VERSION ""

NS_ :

BS_:

BU_: BMS ECC EVBUS_Virtual_ECU GW OBC VCU

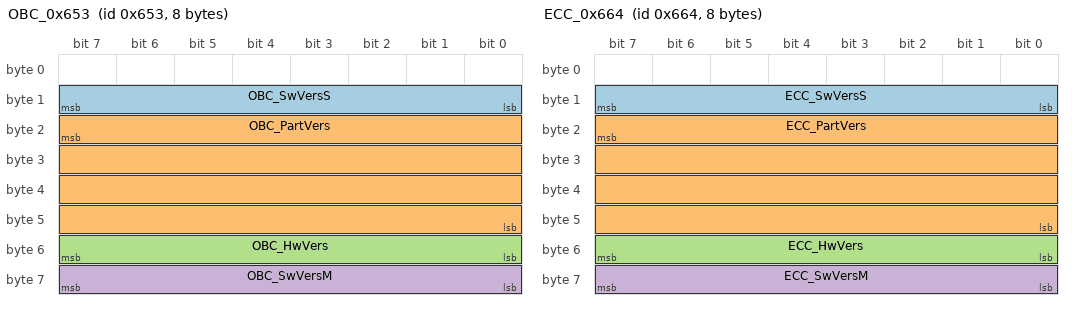
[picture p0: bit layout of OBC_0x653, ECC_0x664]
BO_ 1619 OBC_0x653: 8 OBC
 SG_ OBC_SwVersS : 15|8@0+ (1,0) [0|255] ""  GW,VCU
 SG_ OBC_PartVers : 23|32@0+ (1,0) [0|4294967295] ""  GW,VCU
 SG_ OBC_HwVers : 55|8@0+ (1,0) [0|255] ""  GW,VCU
 SG_ OBC_SwVersM : 63|8@0+ (1,0) [0|255] ""  GW,VCU

BO_ 1636 ECC_0x664: 8 ECC
 SG_ ECC_SwVersS : 15|8@0+ (1,0) [0|255] ""  GW
 SG_ ECC_PartVers : 23|32@0+ (1,0) [0|4294967295] ""  GW
 SG_ ECC_HwVers : 55|8@0+ (1,0) [0|255] ""  GW
 SG_ ECC_SwVersM : 63|8@0+ (1,0) [0|255] ""  GW

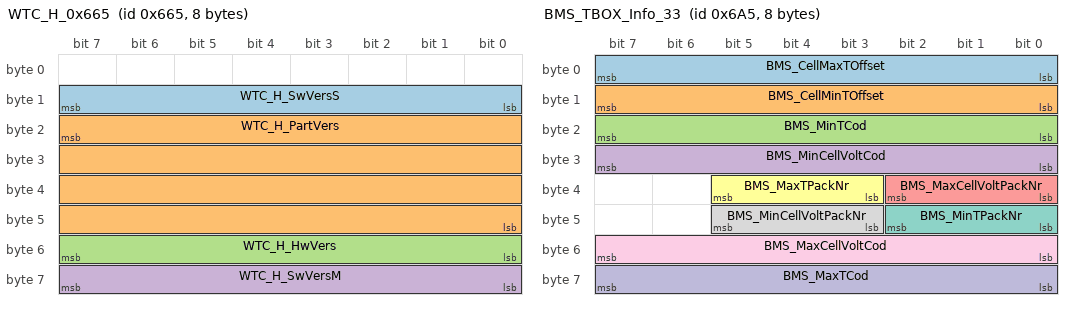
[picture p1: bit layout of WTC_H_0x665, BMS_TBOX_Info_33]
BO_ 1637 WTC_H_0x665: 8 ECC
 SG_ WTC_H_SwVersS : 15|8@0+ (1,0) [0|255] ""  GW
 SG_ WTC_H_PartVers : 23|32@0+ (1,0) [0|4294967295] ""  GW
 SG_ WTC_H_HwVers : 55|8@0+ (1,0) [0|255] ""  GW
 SG_ WTC_H_SwVersM : 63|8@0+ (1,0) [51|255] ""  GW

BO_ 1638 WTC_B_0x666: 8 ECC
 SG_ WTC_B_SwVersS : 15|8@0+ (1,0) [0|255] ""  GW
 SG_ WTC_B_PartVers : 23|32@0+ (1,0) [0|4294967295] ""  GW
 SG_ WTC_B_HwVers : 55|8@0+ (1,0) [0|255] ""  GW
 SG_ WTC_B_SwVersM : 63|8@0+ (1,0) [51|255] ""  GW

BO_ 1695 EAS_0x69F: 8 ECC
 SG_ EAS_SwVersS : 15|8@0+ (1,0) [0|255] ""  GW
 SG_ EAS_PartVers : 23|32@0+ (1,0) [0|4294967295] ""  GW
 SG_ EAS_HwVers : 55|8@0+ (1,0) [1|255] ""  GW
 SG_ EAS_SwVersM : 63|8@0+ (1,0) [51|255] ""  GW

BO_ 1696 BMS_PVIU_EnergyCounterActual: 8 BMS
 SG_ BMS_mxCounterActEnergy : 7|8@0+ (1,0) [0|255] ""  GW
 SG_ BMS_mxEnergyActValue1 : 15|24@0+ (1,0) [0|16777215] "Wh"  GW
 SG_ BMS_mxEnergyActValue2 : 39|24@0+ (1,0) [0|16777215] "Wh"  GW
 SG_ DCDC_ActTemp : 63|8@0+ (1,-40) [-40|210] "Degree Celsius"  GW

BO_ 1697 BMS_C_D_Ah: 8 BMS
 SG_ BMS_AccueChrgTotAh : 7|32@0+ (1,0) [0|4294967295] "Ah"  GW
 SG_ BMS_AccueDchaTotAh : 39|32@0+ (1,0) [0|4294967295] "Ah"  GW

BO_ 1698 VCU_0x6A2: 8 VCU
 SG_ VCU_SCChrgCnt : 7|16@0+ (1,0) [0|65535] ""  GW
 SG_ VCU_VehHVPwrOffTi : 23|24@0+ (1,0) [0|16777215] "min"  GW
 SG_ VCU_FCChrgCnt : 55|16@0+ (1,0) [0|65535] ""  GW

BO_ 1701 BMS_TBOX_Info_33: 8 BMS
 SG_ BMS_CellMaxTOffset : 7|8@0+ (1,-48) [-48|207] ""  GW
 SG_ BMS_CellMinTOffset : 15|8@0+ (1,-48) [-48|207] ""  GW
 SG_ BMS_MinTCod : 23|8@0+ (1,0) [0|255] ""  GW
 SG_ BMS_MinCellVoltCod : 31|8@0+ (1,0) [0|255] ""  GW
 SG_ BMS_MaxCellVoltPackNr : 34|3@0+ (1,0) [0|7] ""  GW
 SG_ BMS_MaxTPackNr : 37|3@0+ (1,0) [0|7] ""  GW
 SG_ BMS_MinTPackNr : 42|3@0+ (1,0) [0|7] ""  GW
 SG_ BMS_MinCellVoltPackNr : 45|3@0+ (1,0) [0|7] ""  GW
 SG_ BMS_MaxCellVoltCod : 55|8@0+ (1,0) [0|255] ""  GW
 SG_ BMS_MaxTCod : 63|8@0+ (1,0) [0|255] ""  GW

BO_ 1712 BMS_TBOX_Info_8: 8 BMS
 SG_ BMS_CellVolt1 : 7|16@0+ (0.1,0) [0|6553.4] "mV"  GW
 SG_ BMS_CellVolt2 : 23|16@0+ (0.1,0) [0|6553.4] "mV"  GW
 SG_ BMS_CellVolt3 : 39|16@0+ (0.1,0) [0|6553.4] "mV"  GW
 SG_ BMS_CellVolt4 : 55|16@0+ (0.1,0) [0|6553.4] "mV"  GW

BO_ 1713 BMS_TBOX_Info_9: 8 BMS
 SG_ BMS_CellVolt5 : 7|16@0+ (0.1,0) [0|6553.4] "mV"  GW
 SG_ BMS_CellVolt6 : 23|16@0+ (0.1,0) [0|6553.4] "mV"  GW
 SG_ BMS_CellVolt7 : 39|16@0+ (0.1,0) [0|6553.4] "mV"  GW
 SG_ BMS_CellVolt8 : 55|16@0+ (0.1,0) [0|6553.4] "mV"  GW

BO_ 1714 BMS_TBOX_Info_10: 8 BMS
 SG_ BMS_CellVolt9 : 7|16@0+ (0.1,0) [0|6553.4] "mV"  GW
 SG_ BMS_CellVolt10 : 23|16@0+ (0.1,0) [0|6553.4] "mV"  GW
 SG_ BMS_CellVolt11 : 39|16@0+ (0.1,0) [0|6553.4] "mV"  GW
 SG_ BMS_CellVolt12 : 55|16@0+ (0.1,0) [0|6553.4] "mV"  GW

BO_ 1715 BMS_TBOX_Info_11: 8 BMS
 SG_ BMS_CellVolt13 : 7|16@0+ (0.1,0) [0|6553.4] "mV"  GW
 SG_ BMS_CellVolt14 : 23|16@0+ (0.1,0) [0|6553.4] "mV"  GW
 SG_ BMS_CellVolt15 : 39|16@0+ (0.1,0) [0|6553.4] "mV"  GW
 SG_ BMS_CellVolt16 : 55|16@0+ (0.1,0) [0|6553.4] "mV"  GW

BO_ 1716 BMS_TBOX_Info_12: 8 BMS
 SG_ BMS_CellVolt17 : 7|16@0+ (0.1,0) [0|6553.4] "mV"  GW
 SG_ BMS_CellVolt18 : 23|16@0+ (0.1,0) [0|6553.4] "mV"  GW
 SG_ BMS_CellVolt19 : 39|16@0+ (0.1,0) [0|6553.4] "mV"  GW
 SG_ BMS_CellVolt20 : 55|16@0+ (0.1,0) [0|6553.4] "mV"  GW

BO_ 1717 BMS_TBOX_Info_13: 8 BMS
 SG_ BMS_CellVolt21 : 7|16@0+ (0.1,0) [0|6553.4] "mV"  GW
 SG_ BMS_CellVolt22 : 23|16@0+ (0.1,0) [0|6553.4] "mV"  GW
 SG_ BMS_CellVolt23 : 39|16@0+ (0.1,0) [0|6553.4] "mV"  GW
 SG_ BMS_CellVolt24 : 55|16@0+ (0.1,0) [0|6553.4] "mV"  GW

BO_ 1718 BMS_TBOX_Info_14: 8 BMS
 SG_ BMS_CellVolt25 : 7|16@0+ (0.1,0) [0|6553.4] "mV"  GW
 SG_ BMS_CellVolt26 : 23|16@0+ (0.1,0) [0|6553.4] "mV"  GW
 SG_ BMS_CellVolt27 : 39|16@0+ (0.1,0) [0|6553.4] "mV"  GW
 SG_ BMS_CellVolt28 : 55|16@0+ (0.1,0) [0|6553.4] "mV"  GW

BO_ 1719 BMS_TBOX_Info_15: 8 BMS
 SG_ BMS_CellVolt29 : 7|16@0+ (0.1,0) [0|6553.4] "mV"  GW
 SG_ BMS_CellVolt30 : 23|16@0+ (0.1,0) [0|6553.4] "mV"  GW
 SG_ BMS_CellVolt31 : 39|16@0+ (0.1,0) [0|6553.4] "mV"  GW
 SG_ BMS_CellVolt32 : 55|16@0+ (0.1,0) [0|6553.4] "mV"  GW

BO_ 1720 BMS_TBOX_Info_16: 8 BMS
 SG_ BMS_CellVolt33 : 7|16@0+ (0.1,0) [0|6553.4] "mV"  GW
 SG_ BMS_CellVolt34 : 23|16@0+ (0.1,0) [0|6553.4] "mV"  GW
 SG_ BMS_CellVolt35 : 39|16@0+ (0.1,0) [0|6553.4] "mV"  GW
 SG_ BMS_CellVolt36 : 55|16@0+ (0.1,0) [0|6553.4] "mV"  GW

BO_ 1721 BMS_TBOX_Info_17: 8 BMS
 SG_ BMS_CellVolt37 : 7|16@0+ (0.1,0) [0|6553.4] "mV"  GW
 SG_ BMS_CellVolt38 : 23|16@0+ (0.1,0) [0|6553.4] "mV"  GW
 SG_ BMS_CellVolt39 : 39|16@0+ (0.1,0) [0|6553.4] "mV"  GW
 SG_ BMS_CellVolt40 : 55|16@0+ (0.1,0) [0|6553.4] "mV"  GW

BO_ 1722 BMS_TBOX_Info_18: 8 BMS
 SG_ BMS_CellVolt41 : 7|16@0+ (0.1,0) [0|6553.4] "mV"  GW
 SG_ BMS_CellVolt42 : 23|16@0+ (0.1,0) [0|6553.4] "mV"  GW
 SG_ BMS_CellVolt43 : 39|16@0+ (0.1,0) [0|6553.4] "mV"  GW
 SG_ BMS_CellVolt44 : 55|16@0+ (0.1,0) [0|6553.4] "mV"  GW

BO_ 1723 BMS_TBOX_Info_19: 8 BMS
 SG_ BMS_CellVolt45 : 7|16@0+ (0.1,0) [0|6553.4] "mV"  GW
 SG_ BMS_CellVolt46 : 23|16@0+ (0.1,0) [0|6553.4] "mV"  GW
 SG_ BMS_CellVolt47 : 39|16@0+ (0.1,0) [0|6553.4] "mV"  GW
 SG_ BMS_CellVolt48 : 55|16@0+ (0.1,0) [0|6553.4] "mV"  GW

BO_ 1724 BMS_TBOX_Info_20: 8 BMS
 SG_ BMS_CellVolt49 : 7|16@0+ (0.1,0) [0|6553.4] "mV"  GW
 SG_ BMS_CellVolt50 : 23|16@0+ (0.1,0) [0|6553.4] "mV"  GW
 SG_ BMS_CellVolt51 : 39|16@0+ (0.1,0) [0|6553.4] "mV"  GW
 SG_ BMS_CellVolt52 : 55|16@0+ (0.1,0) [0|6553.4] "mV"  GW

BO_ 1725 BMS_TBOX_Info_21: 8 BMS
 SG_ BMS_CellVolt53 : 7|16@0+ (0.1,0) [0|6553.4] "mV"  GW
 SG_ BMS_CellVolt54 : 23|16@0+ (0.1,0) [0|6553.4] "mV"  GW
 SG_ BMS_CellVolt55 : 39|16@0+ (0.1,0) [0|6553.4] "mV"  GW
 SG_ BMS_CellVolt56 : 55|16@0+ (0.1,0) [0|6553.4] "mV"  GW

BO_ 1726 BMS_TBOX_Info_34: 8 BMS
 SG_ BMS_CellVolt57 : 7|16@0+ (0.1,0) [0|6553.4] "mV"  GW
 SG_ BMS_CellVolt58 : 23|16@0+ (0.1,0) [0|6553.4] "mV"  GW
 SG_ BMS_CellVolt59 : 39|16@0+ (0.1,0) [0|6553.4] "mV"  GW
 SG_ BMS_CellVolt60 : 55|16@0+ (0.1,0) [0|6553.4] "mV"  GW

BO_ 1727 BMS_TBOX_Info_35: 8 BMS
 SG_ BMS_CellVolt61 : 7|16@0+ (0.1,0) [0|6553.4] "mV"  GW
 SG_ BMS_CellVolt62 : 23|16@0+ (0.1,0) [0|6553.4] "mV"  GW
 SG_ BMS_CellVolt63 : 39|16@0+ (0.1,0) [0|6553.4] "mV"  GW
 SG_ BMS_CellVolt64 : 55|16@0+ (0.1,0) [0|6553.4] "mV"  GW

BO_ 1728 BMS_TBOX_Info_36: 8 BMS
 SG_ BMS_CellVolt65 : 7|16@0+ (0.1,0) [0|6553.4] "mV"  GW
 SG_ BMS_CellVolt66 : 23|16@0+ (0.1,0) [0|6553.4] "mV"  GW
 SG_ BMS_CellVolt67 : 39|16@0+ (0.1,0) [0|6553.4] "mV"  GW
 SG_ BMS_CellVolt68 : 55|16@0+ (0.1,0) [0|6553.4] "mV"  GW

BO_ 1729 BMS_TBOX_Info_37: 8 BMS
 SG_ BMS_CellVolt69 : 7|16@0+ (0.1,0) [0|6553.4] "mV"  GW
 SG_ BMS_CellVolt70 : 23|16@0+ (0.1,0) [0|6553.4] "mV"  GW
 SG_ BMS_CellVolt71 : 39|16@0+ (0.1,0) [0|6553.4] "mV"  GW
 SG_ BMS_CellVolt72 : 55|16@0+ (0.1,0) [0|6553.4] "mV"  GW

BO_ 1730 BMS_TBOX_Info_38: 8 BMS
 SG_ BMS_CellVolt73 : 7|16@0+ (0.1,0) [0|6553.4] "mV"  GW
 SG_ BMS_CellVolt74 : 23|16@0+ (0.1,0) [0|6553.4] "mV"  GW
 SG_ BMS_CellVolt75 : 39|16@0+ (0.1,0) [0|6553.4] "mV"  GW
 SG_ BMS_CellVolt76 : 55|16@0+ (0.1,0) [0|6553.4] "mV"  GW

BO_ 1731 BMS_TBOX_Info_39: 8 BMS
 SG_ BMS_CellVolt77 : 7|16@0+ (0.1,0) [0|6553.4] "mV"  GW
 SG_ BMS_CellVolt78 : 23|16@0+ (0.1,0) [0|6553.4] "mV"  GW
 SG_ BMS_CellVolt79 : 39|16@0+ (0.1,0) [0|6553.4] "mV"  GW
 SG_ BMS_CellVolt80 : 55|16@0+ (0.1,0) [0|6553.4] "mV"  GW

BO_ 1732 BMS_TBOX_Info_40: 8 BMS
 SG_ BMS_CellVolt81 : 7|16@0+ (0.1,0) [0|6553.4] "mV"  GW
 SG_ BMS_CellVolt82 : 23|16@0+ (0.1,0) [0|6553.4] "mV"  GW
 SG_ BMS_CellVolt83 : 39|16@0+ (0.1,0) [0|6553.4] "mV"  GW
 SG_ BMS_CellVolt84 : 55|16@0+ (0.1,0) [0|6553.4] "mV"  GW

BO_ 1733 BMS_TBOX_Info_41: 8 BMS
 SG_ BMS_CellVolt85 : 7|16@0+ (0.1,0) [0|6553.4] "mV"  GW
 SG_ BMS_CellVolt86 : 23|16@0+ (0.1,0) [0|6553.4] "mV"  GW
 SG_ BMS_CellVolt87 : 39|16@0+ (0.1,0) [0|6553.4] "mV"  GW
 SG_ BMS_CellVolt88 : 55|16@0+ (0.1,0) [0|6553.4] "mV"  GW

BO_ 1734 BMS_TBOX_Info_42: 8 BMS
 SG_ BMS_CellVolt89 : 7|16@0+ (0.1,0) [0|6553.4] "mV"  GW
 SG_ BMS_CellVolt90 : 23|16@0+ (0.1,0) [0|6553.4] "mV"  GW
 SG_ BMS_CellVolt91 : 39|16@0+ (0.1,0) [0|6553.4] "mV"  GW
 SG_ BMS_CellVolt92 : 55|16@0+ (0.1,0) [0|6553.4] "mV"  GW

BO_ 1735 BMS_TBOX_Info_43: 8 BMS
 SG_ BMS_CellVolt93 : 7|16@0+ (0.1,0) [0|6553.4] "mV"  GW
 SG_ BMS_CellVolt94 : 23|16@0+ (0.1,0) [0|6553.4] "mV"  GW
 SG_ BMS_CellVolt95 : 39|16@0+ (0.1,0) [0|6553.4] "mV"  GW
 SG_ BMS_CellVolt96 : 55|16@0+ (0.1,0) [0|6553.4] "mV"  GW

BO_ 1736 BMS_TBOX_Info_44: 8 BMS
 SG_ BMS_CellVolt97 : 7|16@0+ (0.1,0) [0|6553.4] "mV"  GW
 SG_ BMS_CellVolt98 : 23|16@0+ (0.1,0) [0|6553.4] "mV"  GW
 SG_ BMS_CellVolt99 : 39|16@0+ (0.1,0) [0|6553.4] "mV"  GW
 SG_ BMS_CellVolt100 : 55|16@0+ (0.1,0) [0|6553.4] "mV"  GW

BO_ 1737 BMS_TBOX_Info_45: 8 BMS
 SG_ BMS_CellVolt101 : 7|16@0+ (0.1,0) [0|6553.4] "mV"  GW
 SG_ BMS_CellVolt102 : 23|16@0+ (0.1,0) [0|6553.4] "mV"  GW
 SG_ BMS_CellVolt103 : 39|16@0+ (0.1,0) [0|6553.4] "mV"  GW
 SG_ BMS_CellVolt104 : 55|16@0+ (0.1,0) [0|6553.4] "mV"  GW

BO_ 1738 BMS_TBOX_Info_46: 8 BMS
 SG_ BMS_CellVolt105 : 7|16@0+ (0.1,0) [0|6553.4] "mV"  GW
 SG_ BMS_CellVolt106 : 23|16@0+ (0.1,0) [0|6553.4] "mV"  GW
 SG_ BMS_CellVolt107 : 39|16@0+ (0.1,0) [0|6553.4] "mV"  GW
 SG_ BMS_CellVolt108 : 55|16@0+ (0.1,0) [0|6553.4] "mV"  GW

BO_ 1739 BMS_TBOX_Info_47: 8 BMS
 SG_ BMS_CellVolt109 : 7|16@0+ (0.1,0) [0|6553.4] "mV"  GW
 SG_ BMS_CellVolt110 : 23|16@0+ (0.1,0) [0|6553.4] "mV"  GW
 SG_ BMS_CellVolt111 : 39|16@0+ (0.1,0) [0|6553.4] "mV"  GW
 SG_ BMS_CellVolt112 : 55|16@0+ (0.1,0) [0|6553.4] "mV"  GW

BO_ 1740 BMS_TBOX_Info_48: 8 BMS
 SG_ BMS_CellVolt113 : 7|16@0+ (0.1,0) [0|6553.4] "mV"  GW
 SG_ BMS_CellVolt114 : 23|16@0+ (0.1,0) [0|6553.4] "mV"  GW
 SG_ BMS_CellVolt115 : 39|16@0+ (0.1,0) [0|6553.4] "mV"  GW
 SG_ BMS_CellVolt116 : 55|16@0+ (0.1,0) [0|6553.4] "mV"  GW

BO_ 1741 BMS_TBOX_Info_49: 8 BMS
 SG_ BMS_CellVolt117 : 7|16@0+ (0.1,0) [0|6553.4] "mV"  GW
 SG_ BMS_CellVolt118 : 23|16@0+ (0.1,0) [0|6553.4] "mV"  GW
 SG_ BMS_CellVolt119 : 39|16@0+ (0.1,0) [0|6553.4] "mV"  GW
 SG_ BMS_CellVolt120 : 55|16@0+ (0.1,0) [0|6553.4] "mV"  GW

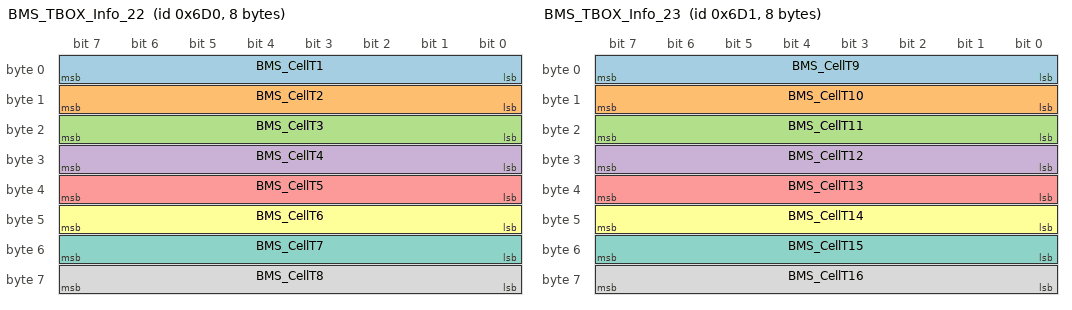
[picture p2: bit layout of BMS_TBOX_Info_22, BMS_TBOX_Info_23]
BO_ 1744 BMS_TBOX_Info_22: 8 BMS
 SG_ BMS_CellT1 : 7|8@0+ (1,-48) [-48|207] "Degree Celsius"  GW
 SG_ BMS_CellT2 : 15|8@0+ (1,-48) [-48|207] "Degree Celsius"  GW
 SG_ BMS_CellT3 : 23|8@0+ (1,-48) [-48|207] "Degree Celsius"  GW
 SG_ BMS_CellT4 : 31|8@0+ (1,-48) [-48|207] "Degree Celsius"  GW
 SG_ BMS_CellT5 : 39|8@0+ (1,-48) [-48|207] "Degree Celsius"  GW
 SG_ BMS_CellT6 : 47|8@0+ (1,-48) [-48|207] "Degree Celsius"  GW
 SG_ BMS_CellT7 : 55|8@0+ (1,-48) [-48|207] "Degree Celsius"  GW
 SG_ BMS_CellT8 : 63|8@0+ (1,-48) [-48|207] "Degree Celsius"  GW

BO_ 1745 BMS_TBOX_Info_23: 8 BMS
 SG_ BMS_CellT9 : 7|8@0+ (1,-48) [-48|207] "Degree Celsius"  GW
 SG_ BMS_CellT10 : 15|8@0+ (1,-48) [-48|207] "Degree Celsius"  GW
 SG_ BMS_CellT11 : 23|8@0+ (1,-48) [-48|207] "Degree Celsius"  GW
 SG_ BMS_CellT12 : 31|8@0+ (1,-48) [-48|207] "Degree Celsius"  GW
 SG_ BMS_CellT13 : 39|8@0+ (1,-48) [-48|207] "Degree Celsius"  GW
 SG_ BMS_CellT14 : 47|8@0+ (1,-48) [-48|207] "Degree Celsius"  GW
 SG_ BMS_CellT15 : 55|8@0+ (1,-48) [-48|207] "Degree Celsius"  GW
 SG_ BMS_CellT16 : 63|8@0+ (1,-48) [-48|207] "Degree Celsius"  GW

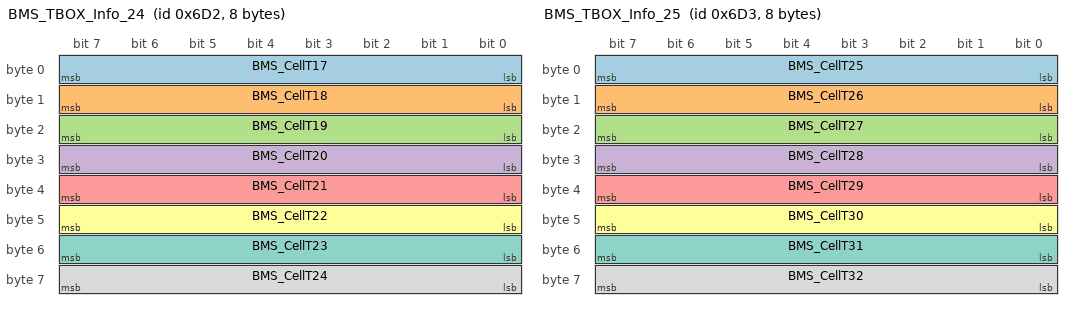
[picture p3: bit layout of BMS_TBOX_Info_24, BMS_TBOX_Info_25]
BO_ 1746 BMS_TBOX_Info_24: 8 BMS
 SG_ BMS_CellT17 : 7|8@0+ (1,-48) [-48|207] "Degree Celsius"  GW
 SG_ BMS_CellT18 : 15|8@0+ (1,-48) [-48|207] "Degree Celsius"  GW
 SG_ BMS_CellT19 : 23|8@0+ (1,-48) [-48|207] "Degree Celsius"  GW
 SG_ BMS_CellT20 : 31|8@0+ (1,-48) [-48|207] "Degree Celsius"  GW
 SG_ BMS_CellT21 : 39|8@0+ (1,-48) [-48|207] "Degree Celsius"  GW
 SG_ BMS_CellT22 : 47|8@0+ (1,-48) [-48|207] "Degree Celsius"  GW
 SG_ BMS_CellT23 : 55|8@0+ (1,-48) [-48|207] "Degree Celsius"  GW
 SG_ BMS_CellT24 : 63|8@0+ (1,-48) [-48|207] "Degree Celsius"  GW

BO_ 1747 BMS_TBOX_Info_25: 8 BMS
 SG_ BMS_CellT25 : 7|8@0+ (1,-48) [-48|207] "Degree Celsius"  GW
 SG_ BMS_CellT26 : 15|8@0+ (1,-48) [-48|207] "Degree Celsius"  GW
 SG_ BMS_CellT27 : 23|8@0+ (1,-48) [-48|207] "Degree Celsius"  GW
 SG_ BMS_CellT28 : 31|8@0+ (1,-48) [-48|207] "Degree Celsius"  GW
 SG_ BMS_CellT29 : 39|8@0+ (1,-48) [-48|207] "Degree Celsius"  GW
 SG_ BMS_CellT30 : 47|8@0+ (1,-48) [-48|207] "Degree Celsius"  GW
 SG_ BMS_CellT31 : 55|8@0+ (1,-48) [-48|207] "Degree Celsius"  GW
 SG_ BMS_CellT32 : 63|8@0+ (1,-48) [-48|207] "Degree Celsius"  GW

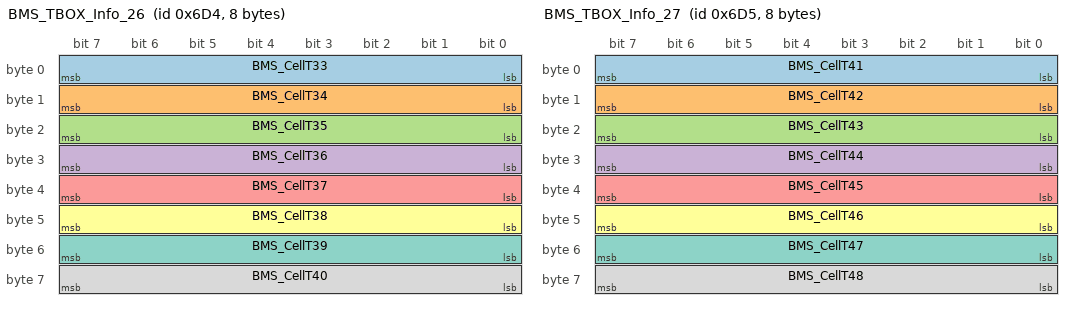
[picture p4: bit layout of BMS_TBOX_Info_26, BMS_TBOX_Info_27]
BO_ 1748 BMS_TBOX_Info_26: 8 BMS
 SG_ BMS_CellT33 : 7|8@0+ (1,-48) [-48|207] "Degree Celsius"  GW
 SG_ BMS_CellT34 : 15|8@0+ (1,-48) [-48|207] "Degree Celsius"  GW
 SG_ BMS_CellT35 : 23|8@0+ (1,-48) [-48|207] "Degree Celsius"  GW
 SG_ BMS_CellT36 : 31|8@0+ (1,-48) [-48|207] "Degree Celsius"  GW
 SG_ BMS_CellT37 : 39|8@0+ (1,-48) [-48|207] "Degree Celsius"  GW
 SG_ BMS_CellT38 : 47|8@0+ (1,-48) [-48|207] "Degree Celsius"  GW
 SG_ BMS_CellT39 : 55|8@0+ (1,-48) [-48|207] "Degree Celsius"  GW
 SG_ BMS_CellT40 : 63|8@0+ (1,-48) [-48|207] "Degree Celsius"  GW

BO_ 1749 BMS_TBOX_Info_27: 8 BMS
 SG_ BMS_CellT41 : 7|8@0+ (1,-48) [-48|207] "Degree Celsius"  GW
 SG_ BMS_CellT42 : 15|8@0+ (1,-48) [-48|207] "Degree Celsius"  GW
 SG_ BMS_CellT43 : 23|8@0+ (1,-48) [-48|207] "Degree Celsius"  GW
 SG_ BMS_CellT44 : 31|8@0+ (1,-48) [-48|207] "Degree Celsius"  GW
 SG_ BMS_CellT45 : 39|8@0+ (1,-48) [-48|207] "Degree Celsius"  GW
 SG_ BMS_CellT46 : 47|8@0+ (1,-48) [-48|207] "Degree Celsius"  GW
 SG_ BMS_CellT47 : 55|8@0+ (1,-48) [-48|207] "Degree Celsius"  GW
 SG_ BMS_CellT48 : 63|8@0+ (1,-48) [-48|207] "Degree Celsius"  GW

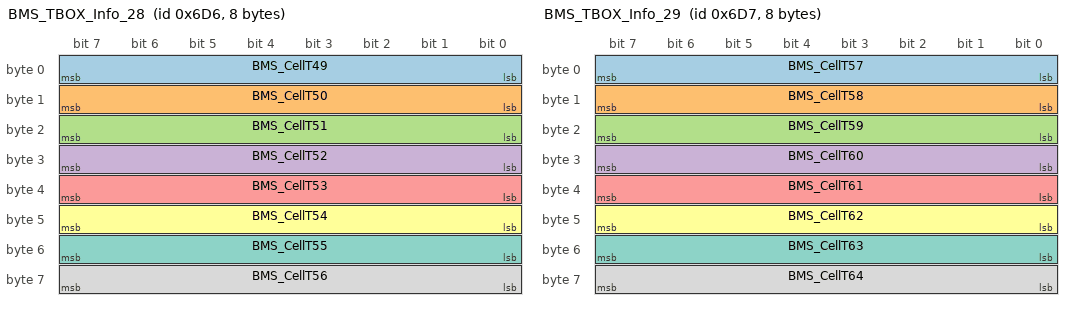
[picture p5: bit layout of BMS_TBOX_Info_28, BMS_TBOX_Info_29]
BO_ 1750 BMS_TBOX_Info_28: 8 BMS
 SG_ BMS_CellT49 : 7|8@0+ (1,-48) [-48|207] "Degree Celsius"  GW
 SG_ BMS_CellT50 : 15|8@0+ (1,-48) [-48|207] "Degree Celsius"  GW
 SG_ BMS_CellT51 : 23|8@0+ (1,-48) [-48|207] "Degree Celsius"  GW
 SG_ BMS_CellT52 : 31|8@0+ (1,-48) [-48|207] "Degree Celsius"  GW
 SG_ BMS_CellT53 : 39|8@0+ (1,-48) [-48|207] "Degree Celsius"  GW
 SG_ BMS_CellT54 : 47|8@0+ (1,-48) [-48|207] "Degree Celsius"  GW
 SG_ BMS_CellT55 : 55|8@0+ (1,-48) [-48|207] "Degree Celsius"  GW
 SG_ BMS_CellT56 : 63|8@0+ (1,-48) [-48|207] "Degree Celsius"  GW

BO_ 1751 BMS_TBOX_Info_29: 8 BMS
 SG_ BMS_CellT57 : 7|8@0+ (1,-48) [-48|207] "Degree Celsius"  GW
 SG_ BMS_CellT58 : 15|8@0+ (1,-48) [-48|207] "Degree Celsius"  GW
 SG_ BMS_CellT59 : 23|8@0+ (1,-48) [-48|207] "Degree Celsius"  GW
 SG_ BMS_CellT60 : 31|8@0+ (1,-48) [-48|207] "Degree Celsius"  GW
 SG_ BMS_CellT61 : 39|8@0+ (1,-48) [-48|207] "Degree Celsius"  GW
 SG_ BMS_CellT62 : 47|8@0+ (1,-48) [-48|207] "Degree Celsius"  GW
 SG_ BMS_CellT63 : 55|8@0+ (1,-48) [-48|207] "Degree Celsius"  GW
 SG_ BMS_CellT64 : 63|8@0+ (1,-48) [-48|207] "Degree Celsius"  GW

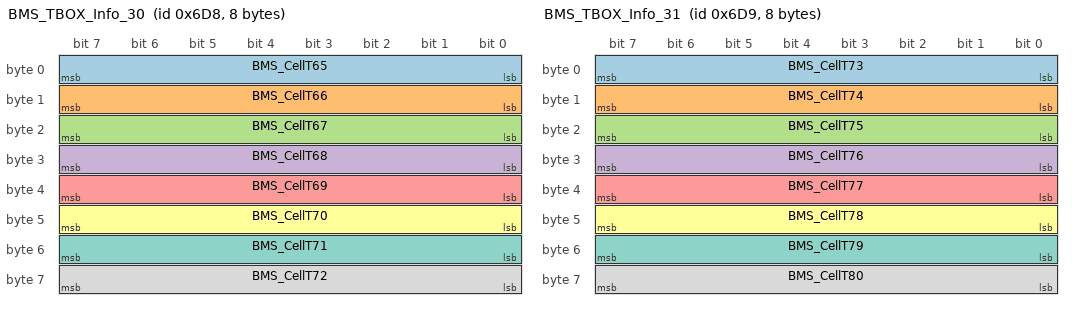
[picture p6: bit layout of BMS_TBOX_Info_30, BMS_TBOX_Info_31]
BO_ 1752 BMS_TBOX_Info_30: 8 BMS
 SG_ BMS_CellT65 : 7|8@0+ (1,-48) [-48|207] "Degree Celsius"  GW
 SG_ BMS_CellT66 : 15|8@0+ (1,-48) [-48|207] "Degree Celsius"  GW
 SG_ BMS_CellT67 : 23|8@0+ (1,-48) [-48|207] "Degree Celsius"  GW
 SG_ BMS_CellT68 : 31|8@0+ (1,-48) [-48|207] "Degree Celsius"  GW
 SG_ BMS_CellT69 : 39|8@0+ (1,-48) [-48|207] "Degree Celsius"  GW
 SG_ BMS_CellT70 : 47|8@0+ (1,-48) [-48|207] "Degree Celsius"  GW
 SG_ BMS_CellT71 : 55|8@0+ (1,-48) [-48|207] "Degree Celsius"  GW
 SG_ BMS_CellT72 : 63|8@0+ (1,-48) [-48|207] "Degree Celsius"  GW

BO_ 1753 BMS_TBOX_Info_31: 8 BMS
 SG_ BMS_CellT73 : 7|8@0+ (1,-48) [-48|207] "Degree Celsius"  GW
 SG_ BMS_CellT74 : 15|8@0+ (1,-48) [-48|207] "Degree Celsius"  GW
 SG_ BMS_CellT75 : 23|8@0+ (1,-48) [-48|207] "Degree Celsius"  GW
 SG_ BMS_CellT76 : 31|8@0+ (1,-48) [-48|207] "Degree Celsius"  GW
 SG_ BMS_CellT77 : 39|8@0+ (1,-48) [-48|207] "Degree Celsius"  GW
 SG_ BMS_CellT78 : 47|8@0+ (1,-48) [-48|207] "Degree Celsius"  GW
 SG_ BMS_CellT79 : 55|8@0+ (1,-48) [-48|207] "Degree Celsius"  GW
 SG_ BMS_CellT80 : 63|8@0+ (1,-48) [-48|207] "Degree Celsius"  GW

BO_ 1754 VCU_0x6DA: 16 VCU
 SG_ VCU_PwrGridAllwMaxPwrSplyCrt : 7|8@0+ (1,0) [0|255] "A"  GW,OBC
 SG_ VCU_ChrgLineAllwtCrt : 15|8@0+ (1,0) [0|255] "A"  GW,OBC
 SG_ VCU_DchaLineAllwCrt : 23|8@0+ (1,0) [0|255] "A"  GW,OBC
 SG_ VCU_DchaVehSts : 26|3@0+ (1,0) [0|7] ""  GW
 SG_ VCU_DCChrgSoktT1 : 39|8@0+ (1,-48) [-48|207] "Degree Celsius"  GW
 SG_ VCU_DCChrgSoktT2 : 47|8@0+ (1,-48) [-48|207] "Degree Celsius"  GW
 SG_ VCU_ACChrgDchaSoktT1 : 55|8@0+ (1,-48) [-48|207] "Degree Celsius"  GW
 SG_ VCU_6DA_SSecOC_Fresh_Byte0 : 71|8@0+ (1,0) [0|255] ""  GW,OBC
 SG_ VCU_6DA_SSecOC_MAC_Byte0 : 79|8@0+ (1,0) [0|255] ""  GW,OBC
 SG_ VCU_6DA_SSecOC_MAC_Byte1 : 87|8@0+ (1,0) [0|255] ""  GW,OBC
 SG_ VCU_6DA_SSecOC_MAC_Byte2 : 95|8@0+ (1,0) [0|255] ""  GW,OBC

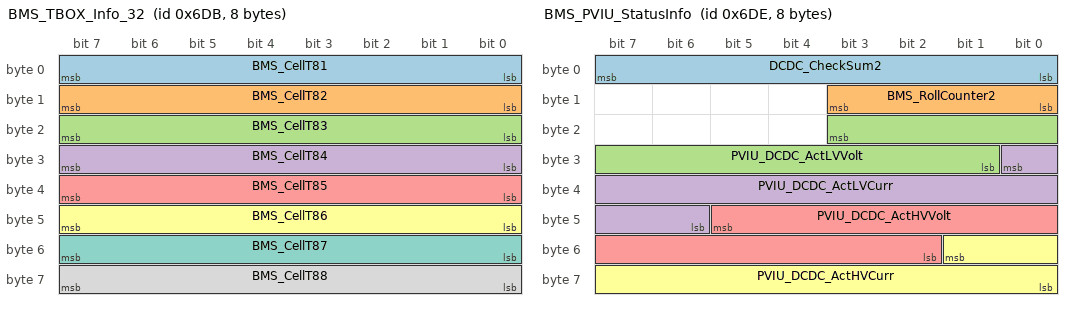
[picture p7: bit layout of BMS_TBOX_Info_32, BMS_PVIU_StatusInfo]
BO_ 1755 BMS_TBOX_Info_32: 8 BMS
 SG_ BMS_CellT81 : 7|8@0+ (1,-48) [-48|207] "Degree Celsius"  GW
 SG_ BMS_CellT82 : 15|8@0+ (1,-48) [-48|207] "Degree Celsius"  GW
 SG_ BMS_CellT83 : 23|8@0+ (1,-48) [-48|207] "Degree Celsius"  GW
 SG_ BMS_CellT84 : 31|8@0+ (1,-48) [-48|207] "Degree Celsius"  GW
 SG_ BMS_CellT85 : 39|8@0+ (1,-48) [-48|207] "Degree Celsius"  GW
 SG_ BMS_CellT86 : 47|8@0+ (1,-48) [-48|207] "Degree Celsius"  GW
 SG_ BMS_CellT87 : 55|8@0+ (1,-48) [-48|207] "Degree Celsius"  GW
 SG_ BMS_CellT88 : 63|8@0+ (1,-48) [-48|207] "Degree Celsius"  GW

BO_ 1756 BMS_PVIU_EnergyCounterHistory: 8 BMS
 SG_ BMS_mxCounterEnergy : 7|8@0+ (1,0) [0|255] ""  GW
 SG_ BMS_mxEnergyValue1 : 15|24@0+ (1,0) [0|16777215] "Wh"  GW
 SG_ BMS_mxEnergyValue2 : 39|24@0+ (1,0) [0|16777215] "Wh"  GW

BO_ 1757 BMS_PVIU_ActualPower: 8 BMS
 SG_ BMS_PVIU_actPower : 7|10@0+ (1,0) [0|1023] "W"  GW
 SG_ BMS_PVIU_EnergyOverall : 23|24@0+ (1,0) [0|16777215] "kWh"  GW
 SG_ BMS_PVIU_ActEngyYear : 47|24@0+ (1,0) [0|16777215] "Wh"  GW

BO_ 1758 BMS_PVIU_StatusInfo: 8 BMS
 SG_ DCDC_CheckSum2 : 7|8@0+ (1,0) [0|255] ""  GW
 SG_ BMS_RollCounter2 : 11|4@0+ (1,0) [0|15] ""  GW
 SG_ PVIU_DCDC_ActLVVolt : 19|11@0+ (0.05,0) [0|102.3] "V"  GW
 SG_ PVIU_DCDC_ActLVCurr : 24|11@0+ (0.01,0) [0|20.47] "A"  GW
 SG_ PVIU_DCDC_ActHVVolt : 45|12@0+ (0.25,0) [0|1023.75] "V"  GW
 SG_ PVIU_DCDC_ActHVCurr : 49|10@0+ (0.01,0) [0|10.23] "A"  GW

BO_ 1759 BMS_PVIU_ErrorStatus: 8 BMS
 SG_ BMS_0x6DF_CheckSum : 7|8@0+ (1,0) [0|255] ""  GW
 SG_ BMS_0x6DF_RollCounter : 11|4@0+ (1,0) [0|15] ""  GW
 SG_ BMS_PVIU_ModeReqSt : 13|2@0+ (1,0) [0|3] ""  GW
 SG_ BMS_PVIU_ModeSt : 15|2@0+ (1,0) [0|3] ""  GW
 SG_ BMS_PVIU_AvailInputPower : 23|11@0+ (1,0) [0|2047] "W"  GW
 SG_ BMS_PVIU_ActOutputPower : 28|11@0+ (1,0) [0|2047] "W"  GW
 SG_ BMS_PVIU_ActOutputEnergy : 33|13@0+ (1,0) [0|8191] "Wh"  GW
 SG_ BMS_PVIU_FailSt : 49|2@0+ (1,0) [0|3] ""  GW,VCU
 SG_ BMS_PVIU_F_Input_OVP : 50|1@0+ (1,0) [0|1] ""  GW
 SG_ BMS_PVIU_F_Input_UVP : 51|1@0+ (1,0) [0|1] ""  GW
 SG_ BMS_PVIU_F_Output_OVP : 52|1@0+ (1,0) [0|1] ""  GW
 SG_ BMS_PVIU_F_Output_UVP : 56|1@0+ (1,0) [0|1] ""  GW
 SG_ BMS_PVIU_F_12V_OVP : 57|1@0+ (1,0) [0|1] ""  GW
 SG_ BMS_PVIU_F_12V_UVP : 58|1@0+ (1,0) [0|1] ""  GW
 SG_ BMS_PVIU_F_Output_SCP : 59|1@0+ (1,0) [0|1] ""  GW
 SG_ BMS_PVIU_F_OTP : 60|1@0+ (1,0) [0|1] ""  GW
 SG_ BMS_PVIU_F_HVIL : 61|1@0+ (1,0) [0|1] ""  GW
 SG_ BMS_PVIU_F_CANRx_Timeout : 62|1@0+ (1,0) [0|1] ""  GW
 SG_ BMS_PVIU_F_Output_OCP : 63|1@0+ (1,0) [0|1] ""  GW

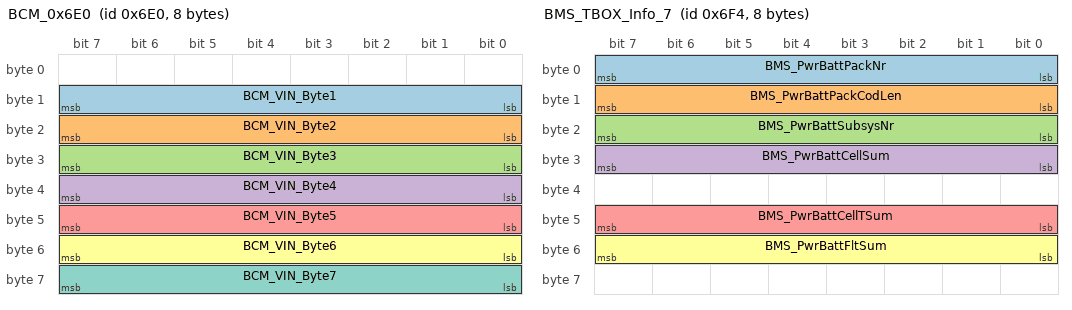
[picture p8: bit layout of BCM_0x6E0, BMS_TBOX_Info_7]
BO_ 1760 BCM_0x6E0: 8 GW
 SG_ BCM_VIN_Byte1 : 15|8@0+ (1,0) [0|255] ""  ECC,OBC,VCU
 SG_ BCM_VIN_Byte2 : 23|8@0+ (1,0) [0|255] ""  ECC,OBC,VCU
 SG_ BCM_VIN_Byte3 : 31|8@0+ (1,0) [0|255] ""  ECC,OBC,VCU
 SG_ BCM_VIN_Byte4 : 39|8@0+ (1,0) [0|255] ""  ECC,OBC,VCU
 SG_ BCM_VIN_Byte5 : 47|8@0+ (1,0) [0|255] ""  ECC,OBC,VCU
 SG_ BCM_VIN_Byte6 : 55|8@0+ (1,0) [0|255] ""  ECC,OBC,VCU
 SG_ BCM_VIN_Byte7 : 63|8@0+ (1,0) [0|255] ""  ECC,OBC,VCU

BO_ 1765 VCU_0x6E5: 8 VCU
 SG_ VCU_VINCod1 : 7|64@0+ (1,0) [0|16777215] ""  GW

BO_ 1766 VCU_0x6E6: 8 VCU
 SG_ VCU_VINCod2 : 7|64@0+ (1,0) [0|16777215] ""  GW

BO_ 1767 VCU_0x6E7: 8 VCU
 SG_ VCU_VINCod3 : 7|64@0+ (1,0) [0|16777215] ""  GW

BO_ 1776 BMS_TBOX_Info_3: 8 BMS
 SG_ BMS_PwrBattPackCod1 : 7|64@0+ (1,0) [0|16777215] ""  GW

BO_ 1777 BMS_TBOX_Info_4: 8 BMS
 SG_ BMS_PwrBattPackCod2 : 7|64@0+ (1,0) [0|16777215] ""  GW

BO_ 1778 BMS_TBOX_Info_5: 8 BMS
 SG_ BMS_PwrBattPackCod3 : 7|64@0+ (1,0) [0|16777215] ""  GW

BO_ 1779 BMS_TBOX_Info_6: 8 BMS
 SG_ BMS_PwrBattPackCod4 : 7|64@0+ (1,0) [0|16777215] ""  GW

BO_ 1780 BMS_TBOX_Info_7: 8 BMS
 SG_ BMS_PwrBattPackNr : 7|8@0+ (1,0) [0|255] ""  GW
 SG_ BMS_PwrBattPackCodLen : 15|8@0+ (1,0) [0|255] ""  GW
 SG_ BMS_PwrBattSubsysNr : 23|8@0+ (1,0) [0|255] ""  GW
 SG_ BMS_PwrBattCellSum : 31|8@0+ (1,0) [0|255] ""  GW
 SG_ BMS_PwrBattCellTSum : 47|8@0+ (1,0) [0|255] ""  GW
 SG_ BMS_PwrBattFltSum : 55|8@0+ (1,0) [0|255] ""  GW

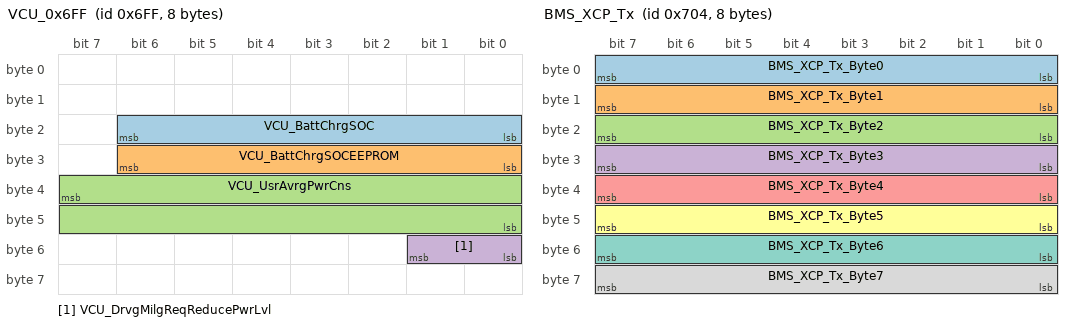
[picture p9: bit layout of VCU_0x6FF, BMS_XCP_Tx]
BO_ 1791 VCU_0x6FF: 8 VCU
 SG_ VCU_BattChrgSOC : 22|7@0+ (1,0) [0|100] "%"  GW
 SG_ VCU_BattChrgSOCEEPROM : 30|7@0+ (1,0) [0|100] "%"  GW
 SG_ VCU_UsrAvrgPwrCns : 39|16@0+ (0.0001,0) [0|6.5535] "Ah/km"  GW
 SG_ VCU_DrvgMilgReqReducePwrLvl : 49|2@0+ (1,0) [0|3] ""  GW

BO_ 1796 BMS_XCP_Tx: 8 BMS
 SG_ BMS_XCP_Tx_Byte0 : 7|8@0+ (1,0) [0|255] ""  EVBUS_Virtual_ECU
 SG_ BMS_XCP_Tx_Byte1 : 15|8@0+ (1,0) [0|255] ""  EVBUS_Virtual_ECU
 SG_ BMS_XCP_Tx_Byte2 : 23|8@0+ (1,0) [0|255] ""  EVBUS_Virtual_ECU
 SG_ BMS_XCP_Tx_Byte3 : 31|8@0+ (1,0) [0|255] ""  EVBUS_Virtual_ECU
 SG_ BMS_XCP_Tx_Byte4 : 39|8@0+ (1,0) [0|255] ""  EVBUS_Virtual_ECU
 SG_ BMS_XCP_Tx_Byte5 : 47|8@0+ (1,0) [0|255] ""  EVBUS_Virtual_ECU
 SG_ BMS_XCP_Tx_Byte6 : 55|8@0+ (1,0) [0|255] ""  EVBUS_Virtual_ECU
 SG_ BMS_XCP_Tx_Byte7 : 63|8@0+ (1,0) [0|255] ""  EVBUS_Virtual_ECU

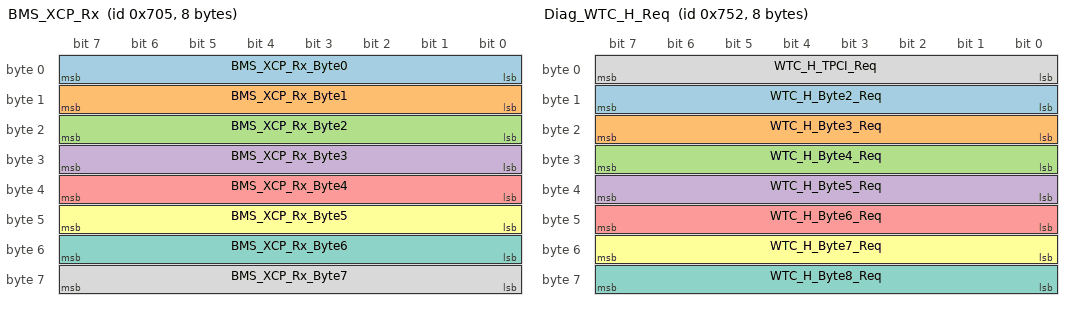
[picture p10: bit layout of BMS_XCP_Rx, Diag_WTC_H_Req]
BO_ 1797 BMS_XCP_Rx: 8 EVBUS_Virtual_ECU
 SG_ BMS_XCP_Rx_Byte0 : 7|8@0+ (1,0) [0|255] ""  BMS
 SG_ BMS_XCP_Rx_Byte1 : 15|8@0+ (1,0) [0|255] ""  BMS
 SG_ BMS_XCP_Rx_Byte2 : 23|8@0+ (1,0) [0|255] ""  BMS
 SG_ BMS_XCP_Rx_Byte3 : 31|8@0+ (1,0) [0|255] ""  BMS
 SG_ BMS_XCP_Rx_Byte4 : 39|8@0+ (1,0) [0|255] ""  BMS
 SG_ BMS_XCP_Rx_Byte5 : 47|8@0+ (1,0) [0|255] ""  BMS
 SG_ BMS_XCP_Rx_Byte6 : 55|8@0+ (1,0) [0|255] ""  BMS
 SG_ BMS_XCP_Rx_Byte7 : 63|8@0+ (1,0) [0|255] ""  BMS

BO_ 1798 VCU_XCP_Rx: 8 EVBUS_Virtual_ECU
 SG_ VCU_XCP_Rx_Signal : 7|64@0+ (1,0) [0|1.84467440737096E+019] ""  VCU

BO_ 1799 VCU_XCP_Tx: 8 VCU
 SG_ VCU_XCP_Tx_Signal : 7|64@0+ (1,0) [0|1.84467440737096E+019] ""  EVBUS_Virtual_ECU

BO_ 1800 ECC_XCP_Tx: 8 ECC
 SG_ ECC_XCP_Tx_Signal : 7|64@0+ (1,0) [0|1.84467440737096E+019] ""  EVBUS_Virtual_ECU

BO_ 1801 ECC_XCP_Rx1: 8 EVBUS_Virtual_ECU
 SG_ ECC_XCP_Rx_Signal_1 : 7|64@0+ (1,0) [0|1.84467440737096E+019] ""  ECC

BO_ 1802 ECC_XCP_Rx2: 8 EVBUS_Virtual_ECU
 SG_ ECC_XCP_Rx_Signal_2 : 7|64@0+ (1,0) [0|1.84467440737096E+019] ""  ECC

BO_ 1803 ECC_XCP_Rx3: 8 EVBUS_Virtual_ECU
 SG_ ECC_XCP_Rx_Signal_3 : 7|64@0+ (1,0) [0|1.84467440737096E+019] ""  ECC

BO_ 1804 ECC_XCP_Rx4: 8 EVBUS_Virtual_ECU
 SG_ ECC_XCP_Rx_Signal_4 : 7|64@0+ (1,0) [0|1.84467440737096E+019] ""  ECC

BO_ 1805 ECC_XCP_Rx5: 8 EVBUS_Virtual_ECU
 SG_ ECC_XCP_Rx_Signal_5 : 7|64@0+ (1,0) [0|1.84467440737096E+019] ""  ECC

BO_ 1806 ECC_XCP_Rx6: 8 EVBUS_Virtual_ECU
 SG_ ECC_XCP_Rx_Signal_6 : 7|64@0+ (1,0) [0|1.84467440737096E+019] ""  ECC

BO_ 1807 ECC_XCP_Rx7: 8 EVBUS_Virtual_ECU
 SG_ ECC_XCP_Rx_Signal_7 : 7|64@0+ (1,0) [0|1.84467440737096E+019] ""  ECC

BO_ 1808 ECC_XCP_Rx8: 8 EVBUS_Virtual_ECU
 SG_ ECC_XCP_Rx_Signal_8 : 7|64@0+ (1,0) [0|1.84467440737096E+019] ""  ECC

BO_ 1809 ECC_XCP_Rx9: 8 EVBUS_Virtual_ECU
 SG_ ECC_XCP_Rx_Signal_9 : 7|64@0+ (1,0) [0|1.84467440737096E+019] ""  ECC

BO_ 1812 OBC_TBOX_Debug: 16 OBC
 SG_ OBC_FailCode : 7|8@0+ (1,0) [0|250] ""  GW
 SG_ DCDC_FailCode : 15|8@0+ (1,0) [0|250] ""  GW
 SG_ DCDC_TempMOS : 23|8@0+ (1,-45) [-45|120] "Degree Celsius"  GW
 SG_ OBC_LLCTemp : 31|8@0+ (1,-45) [-45|120] "Degree Celsius"  GW
 SG_ DCDC_ULV1_1 : 39|8@0+ (1,0) [0|32] "V"  GW
 SG_ OBC_PFCTemp : 47|8@0+ (1,-45) [-45|120] "Degree Celsius"  GW
 SG_ DCDC_ClampCapVol : 55|10@0+ (1,0) [0|1000] "V"  GW
 SG_ OBC_CtrlActMode : 58|3@0+ (1,0) [0|7] ""  GW
 SG_ DCDC_CtrlMode : 61|3@0+ (1,0) [0|7] ""  GW
 SG_ PDU_DCPortVoltage : 71|10@0+ (1,0) [0|1000] "V"  GW
 SG_ PDU_BATVoltage : 72|10@0+ (1,0) [0|1000] "V"  GW
 SG_ Hw_Fault_Flag : 75|3@0+ (1,0) [0|7] ""  GW
 SG_ OBC_ElockCtrlCmd : 77|2@0+ (1,0) [0|3] ""  GW

BO_ 1874 Diag_WTC_H_Req: 8 GW
 SG_ WTC_H_Byte2_Req : 15|8@0+ (1,0) [0|255] ""  ECC
 SG_ WTC_H_Byte3_Req : 23|8@0+ (1,0) [0|255] ""  ECC
 SG_ WTC_H_Byte4_Req : 31|8@0+ (1,0) [0|255] ""  ECC
 SG_ WTC_H_Byte5_Req : 39|8@0+ (1,0) [0|255] ""  ECC
 SG_ WTC_H_Byte6_Req : 47|8@0+ (1,0) [0|255] ""  ECC
 SG_ WTC_H_Byte7_Req : 55|8@0+ (1,0) [0|255] ""  ECC
 SG_ WTC_H_Byte8_Req : 63|8@0+ (1,0) [0|255] ""  ECC
 SG_ WTC_H_TPCI_Req : 7|8@0+ (1,0) [0|255] ""  ECC

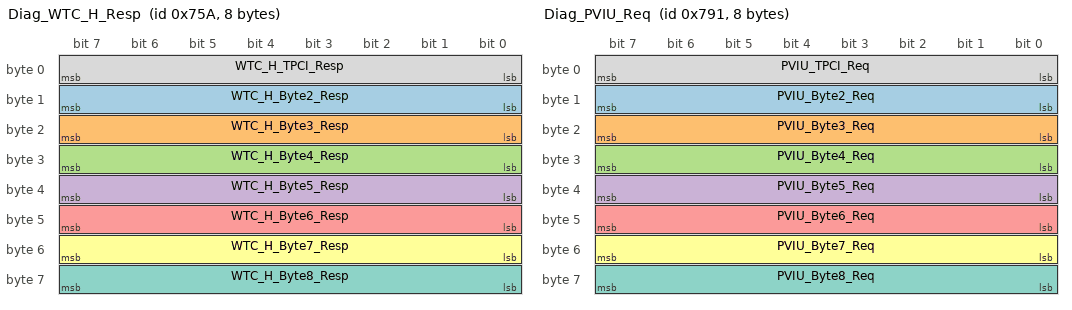
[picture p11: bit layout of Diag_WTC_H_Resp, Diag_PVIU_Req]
BO_ 1882 Diag_WTC_H_Resp: 8 ECC
 SG_ WTC_H_Byte2_Resp : 15|8@0+ (1,0) [0|255] ""  GW
 SG_ WTC_H_Byte3_Resp : 23|8@0+ (1,0) [0|255] ""  GW
 SG_ WTC_H_Byte4_Resp : 31|8@0+ (1,0) [0|255] ""  GW
 SG_ WTC_H_Byte5_Resp : 39|8@0+ (1,0) [0|255] ""  GW
 SG_ WTC_H_Byte6_Resp : 47|8@0+ (1,0) [0|255] ""  GW
 SG_ WTC_H_Byte7_Resp : 55|8@0+ (1,0) [0|255] ""  GW
 SG_ WTC_H_Byte8_Resp : 63|8@0+ (1,0) [0|255] ""  GW
 SG_ WTC_H_TPCI_Resp : 7|8@0+ (1,0) [0|255] ""  GW

BO_ 1937 Diag_PVIU_Req: 8 GW
 SG_ PVIU_Byte2_Req : 15|8@0+ (1,0) [0|255] ""  BMS
 SG_ PVIU_Byte3_Req : 23|8@0+ (1,0) [0|255] ""  BMS
 SG_ PVIU_Byte4_Req : 31|8@0+ (1,0) [0|255] ""  BMS
 SG_ PVIU_Byte5_Req : 39|8@0+ (1,0) [0|255] ""  BMS
 SG_ PVIU_Byte6_Req : 47|8@0+ (1,0) [0|255] ""  BMS
 SG_ PVIU_Byte7_Req : 55|8@0+ (1,0) [0|255] ""  BMS
 SG_ PVIU_Byte8_Req : 63|8@0+ (1,0) [0|255] ""  BMS
 SG_ PVIU_TPCI_Req : 7|8@0+ (1,0) [0|255] ""  BMS

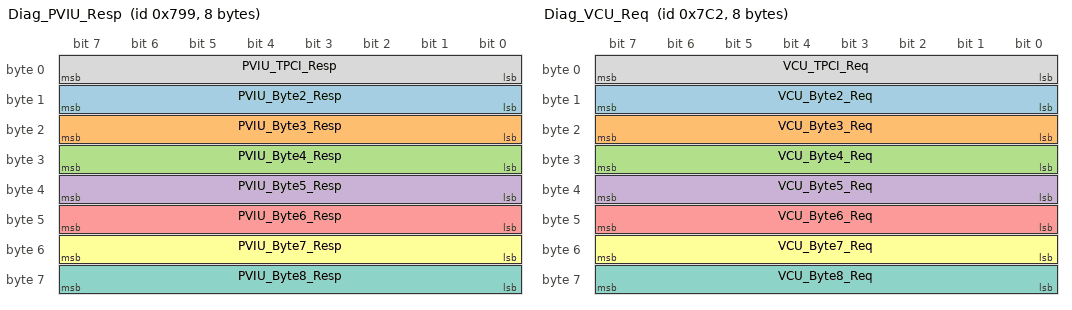
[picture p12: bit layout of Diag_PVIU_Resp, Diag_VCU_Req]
BO_ 1945 Diag_PVIU_Resp: 8 BMS
 SG_ PVIU_Byte2_Resp : 15|8@0+ (1,0) [0|255] ""  GW
 SG_ PVIU_Byte3_Resp : 23|8@0+ (1,0) [0|255] ""  GW
 SG_ PVIU_Byte4_Resp : 31|8@0+ (1,0) [0|255] ""  GW
 SG_ PVIU_Byte5_Resp : 39|8@0+ (1,0) [0|255] ""  GW
 SG_ PVIU_Byte6_Resp : 47|8@0+ (1,0) [0|255] ""  GW
 SG_ PVIU_Byte7_Resp : 55|8@0+ (1,0) [0|255] ""  GW
 SG_ PVIU_Byte8_Resp : 63|8@0+ (1,0) [0|255] ""  GW
 SG_ PVIU_TPCI_Resp : 7|8@0+ (1,0) [0|255] ""  GW

BO_ 1986 Diag_VCU_Req: 8 GW
 SG_ VCU_Byte2_Req : 15|8@0+ (1,0) [0|255] ""  VCU
 SG_ VCU_Byte3_Req : 23|8@0+ (1,0) [0|255] ""  VCU
 SG_ VCU_Byte4_Req : 31|8@0+ (1,0) [0|255] ""  VCU
 SG_ VCU_Byte5_Req : 39|8@0+ (1,0) [0|255] ""  VCU
 SG_ VCU_Byte6_Req : 47|8@0+ (1,0) [0|255] ""  VCU
 SG_ VCU_Byte7_Req : 55|8@0+ (1,0) [0|255] ""  VCU
 SG_ VCU_Byte8_Req : 63|8@0+ (1,0) [0|255] ""  VCU
 SG_ VCU_TPCI_Req : 7|8@0+ (1,0) [0|255] ""  VCU

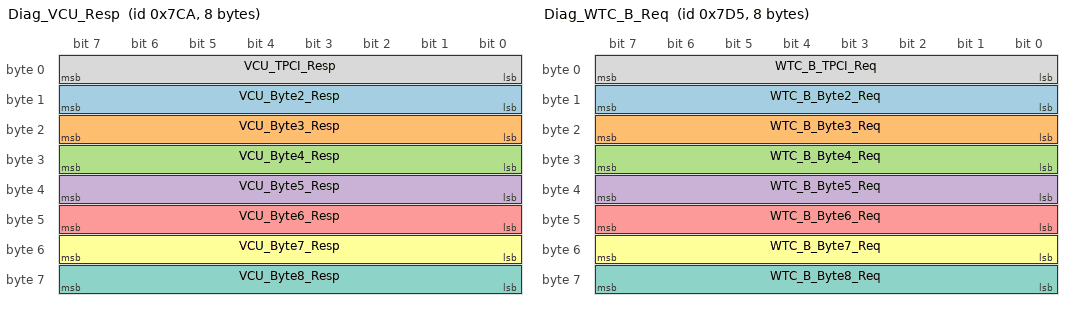
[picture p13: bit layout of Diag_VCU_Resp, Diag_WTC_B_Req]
BO_ 1994 Diag_VCU_Resp: 8 VCU
 SG_ VCU_Byte2_Resp : 15|8@0+ (1,0) [0|255] ""  GW
 SG_ VCU_Byte3_Resp : 23|8@0+ (1,0) [0|255] ""  GW
 SG_ VCU_Byte4_Resp : 31|8@0+ (1,0) [0|255] ""  GW
 SG_ VCU_Byte5_Resp : 39|8@0+ (1,0) [0|255] ""  GW
 SG_ VCU_Byte6_Resp : 47|8@0+ (1,0) [0|255] ""  GW
 SG_ VCU_Byte7_Resp : 55|8@0+ (1,0) [0|255] ""  GW
 SG_ VCU_Byte8_Resp : 63|8@0+ (1,0) [0|255] ""  GW
 SG_ VCU_TPCI_Resp : 7|8@0+ (1,0) [0|255] ""  GW

BO_ 2005 Diag_WTC_B_Req: 8 GW
 SG_ WTC_B_Byte2_Req : 15|8@0+ (1,0) [0|255] ""  ECC
 SG_ WTC_B_Byte3_Req : 23|8@0+ (1,0) [0|255] ""  ECC
 SG_ WTC_B_Byte4_Req : 31|8@0+ (1,0) [0|255] ""  ECC
 SG_ WTC_B_Byte5_Req : 39|8@0+ (1,0) [0|255] ""  ECC
 SG_ WTC_B_Byte6_Req : 47|8@0+ (1,0) [0|255] ""  ECC
 SG_ WTC_B_Byte7_Req : 55|8@0+ (1,0) [0|255] ""  ECC
 SG_ WTC_B_Byte8_Req : 63|8@0+ (1,0) [0|255] ""  ECC
 SG_ WTC_B_TPCI_Req : 7|8@0+ (1,0) [0|255] ""  ECC

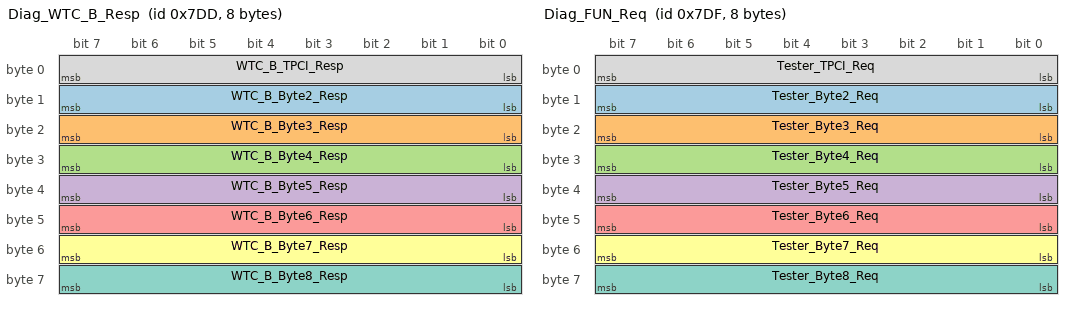
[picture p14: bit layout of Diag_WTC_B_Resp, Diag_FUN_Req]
BO_ 2013 Diag_WTC_B_Resp: 8 ECC
 SG_ WTC_B_Byte2_Resp : 15|8@0+ (1,0) [0|255] ""  GW
 SG_ WTC_B_Byte3_Resp : 23|8@0+ (1,0) [0|255] ""  GW
 SG_ WTC_B_Byte4_Resp : 31|8@0+ (1,0) [0|255] ""  GW
 SG_ WTC_B_Byte5_Resp : 39|8@0+ (1,0) [0|255] ""  GW
 SG_ WTC_B_Byte6_Resp : 47|8@0+ (1,0) [0|255] ""  GW
 SG_ WTC_B_Byte7_Resp : 55|8@0+ (1,0) [0|255] ""  GW
 SG_ WTC_B_Byte8_Resp : 63|8@0+ (1,0) [0|255] ""  GW
 SG_ WTC_B_TPCI_Resp : 7|8@0+ (1,0) [0|255] ""  GW

BO_ 2015 Diag_FUN_Req: 8 GW
 SG_ Tester_Byte2_Req : 15|8@0+ (1,0) [0|255] ""  VCU,BMS,OBC,ECC
 SG_ Tester_Byte3_Req : 23|8@0+ (1,0) [0|255] ""  VCU,BMS,OBC,ECC
 SG_ Tester_Byte4_Req : 31|8@0+ (1,0) [0|255] ""  VCU,BMS,OBC,ECC
 SG_ Tester_Byte5_Req : 39|8@0+ (1,0) [0|255] ""  VCU,BMS,OBC,ECC
 SG_ Tester_Byte6_Req : 47|8@0+ (1,0) [0|255] ""  VCU,BMS,OBC,ECC
 SG_ Tester_Byte7_Req : 55|8@0+ (1,0) [0|255] ""  VCU,BMS,OBC,ECC
 SG_ Tester_Byte8_Req : 63|8@0+ (1,0) [0|255] ""  VCU,BMS,OBC,ECC
 SG_ Tester_TPCI_Req : 7|8@0+ (1,0) [0|255] ""  VCU,BMS,OBC,ECC

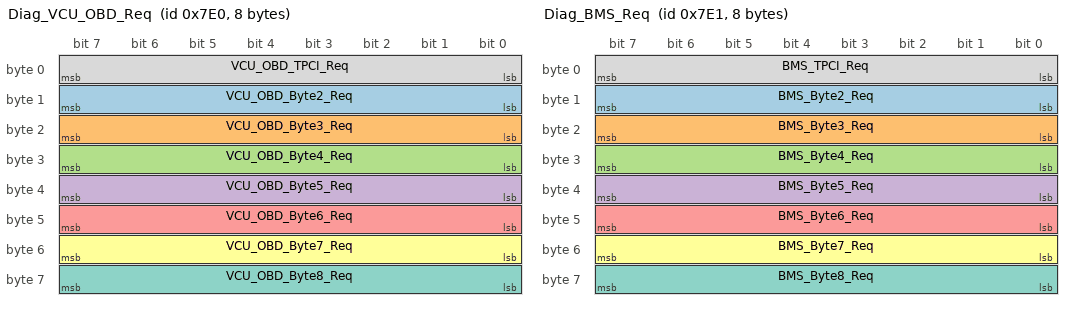
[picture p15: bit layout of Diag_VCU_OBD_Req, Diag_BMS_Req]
BO_ 2016 Diag_VCU_OBD_Req: 8 GW
 SG_ VCU_OBD_Byte2_Req : 15|8@0+ (1,0) [0|255] ""  VCU
 SG_ VCU_OBD_Byte3_Req : 23|8@0+ (1,0) [0|255] ""  VCU
 SG_ VCU_OBD_Byte4_Req : 31|8@0+ (1,0) [0|255] ""  VCU
 SG_ VCU_OBD_Byte5_Req : 39|8@0+ (1,0) [0|255] ""  VCU
 SG_ VCU_OBD_Byte6_Req : 47|8@0+ (1,0) [0|255] ""  VCU
 SG_ VCU_OBD_Byte7_Req : 55|8@0+ (1,0) [0|255] ""  VCU
 SG_ VCU_OBD_Byte8_Req : 63|8@0+ (1,0) [0|255] ""  VCU
 SG_ VCU_OBD_TPCI_Req : 7|8@0+ (1,0) [0|255] ""  VCU

BO_ 2017 Diag_BMS_Req: 8 GW
 SG_ BMS_Byte2_Req : 15|8@0+ (1,0) [0|255] ""  BMS
 SG_ BMS_Byte3_Req : 23|8@0+ (1,0) [0|255] ""  BMS
 SG_ BMS_Byte4_Req : 31|8@0+ (1,0) [0|255] ""  BMS
 SG_ BMS_Byte5_Req : 39|8@0+ (1,0) [0|255] ""  BMS
 SG_ BMS_Byte6_Req : 47|8@0+ (1,0) [0|255] ""  BMS
 SG_ BMS_Byte7_Req : 55|8@0+ (1,0) [0|255] ""  BMS
 SG_ BMS_Byte8_Req : 63|8@0+ (1,0) [0|255] ""  BMS
 SG_ BMS_TPCI_Req : 7|8@0+ (1,0) [0|255] ""  BMS

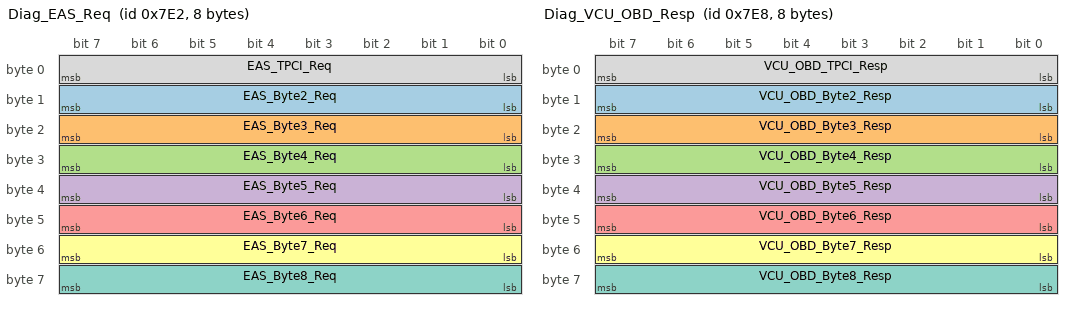
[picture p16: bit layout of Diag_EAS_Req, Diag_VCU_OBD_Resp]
BO_ 2018 Diag_EAS_Req: 8 GW
 SG_ EAS_Byte2_Req : 15|8@0+ (1,0) [0|255] ""  ECC
 SG_ EAS_Byte3_Req : 23|8@0+ (1,0) [0|255] ""  ECC
 SG_ EAS_Byte4_Req : 31|8@0+ (1,0) [0|255] ""  ECC
 SG_ EAS_Byte5_Req : 39|8@0+ (1,0) [0|255] ""  ECC
 SG_ EAS_Byte6_Req : 47|8@0+ (1,0) [0|255] ""  ECC
 SG_ EAS_Byte7_Req : 55|8@0+ (1,0) [0|255] ""  ECC
 SG_ EAS_Byte8_Req : 63|8@0+ (1,0) [0|255] ""  ECC
 SG_ EAS_TPCI_Req : 7|8@0+ (1,0) [0|255] ""  ECC

BO_ 2024 Diag_VCU_OBD_Resp: 8 VCU
 SG_ VCU_OBD_Byte2_Resp : 15|8@0+ (1,0) [0|255] ""  GW
 SG_ VCU_OBD_Byte3_Resp : 23|8@0+ (1,0) [0|255] ""  GW
 SG_ VCU_OBD_Byte4_Resp : 31|8@0+ (1,0) [0|255] ""  GW
 SG_ VCU_OBD_Byte5_Resp : 39|8@0+ (1,0) [0|255] ""  GW
 SG_ VCU_OBD_Byte6_Resp : 47|8@0+ (1,0) [0|255] ""  GW
 SG_ VCU_OBD_Byte7_Resp : 55|8@0+ (1,0) [0|255] ""  GW
 SG_ VCU_OBD_Byte8_Resp : 63|8@0+ (1,0) [0|255] ""  GW
 SG_ VCU_OBD_TPCI_Resp : 7|8@0+ (1,0) [0|255] ""  GW

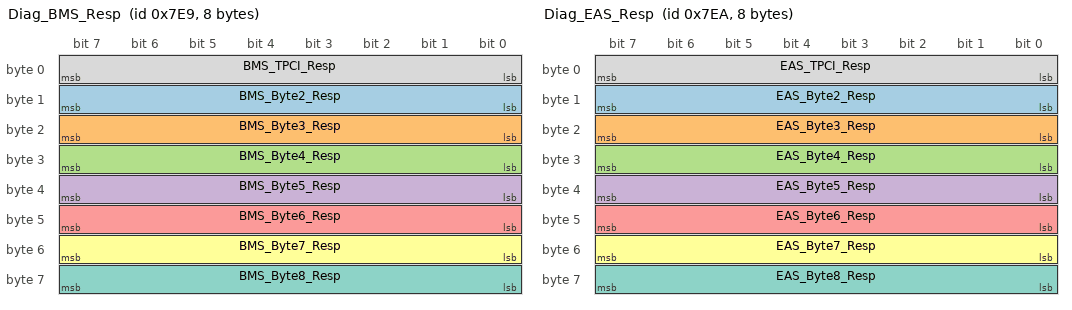
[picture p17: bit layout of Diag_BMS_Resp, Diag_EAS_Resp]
BO_ 2025 Diag_BMS_Resp: 8 BMS
 SG_ BMS_Byte2_Resp : 15|8@0+ (1,0) [0|255] ""  GW
 SG_ BMS_Byte3_Resp : 23|8@0+ (1,0) [0|255] ""  GW
 SG_ BMS_Byte4_Resp : 31|8@0+ (1,0) [0|255] ""  GW
 SG_ BMS_Byte5_Resp : 39|8@0+ (1,0) [0|255] ""  GW
 SG_ BMS_Byte6_Resp : 47|8@0+ (1,0) [0|255] ""  GW
 SG_ BMS_Byte7_Resp : 55|8@0+ (1,0) [0|255] ""  GW
 SG_ BMS_Byte8_Resp : 63|8@0+ (1,0) [0|255] ""  GW
 SG_ BMS_TPCI_Resp : 7|8@0+ (1,0) [0|255] ""  GW

BO_ 2026 Diag_EAS_Resp: 8 ECC
 SG_ EAS_Byte2_Resp : 15|8@0+ (1,0) [0|255] ""  GW
 SG_ EAS_Byte3_Resp : 23|8@0+ (1,0) [0|255] ""  GW
 SG_ EAS_Byte4_Resp : 31|8@0+ (1,0) [0|255] ""  GW
 SG_ EAS_Byte5_Resp : 39|8@0+ (1,0) [0|255] ""  GW
 SG_ EAS_Byte6_Resp : 47|8@0+ (1,0) [0|255] ""  GW
 SG_ EAS_Byte7_Resp : 55|8@0+ (1,0) [0|255] ""  GW
 SG_ EAS_Byte8_Resp : 63|8@0+ (1,0) [0|255] ""  GW
 SG_ EAS_TPCI_Resp : 7|8@0+ (1,0) [0|255] ""  GW

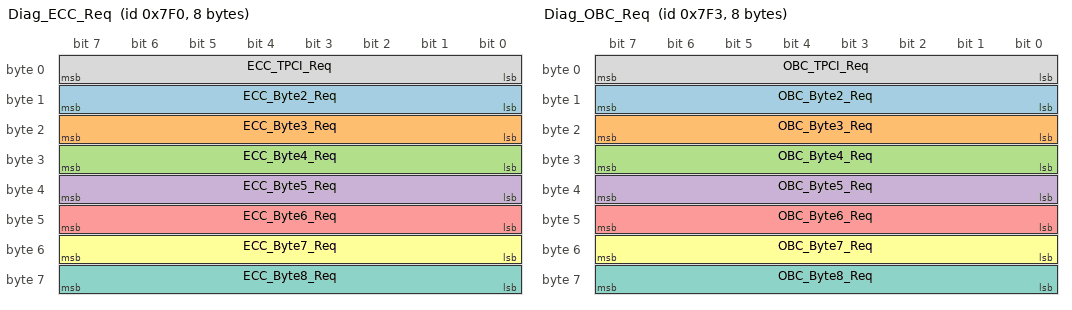
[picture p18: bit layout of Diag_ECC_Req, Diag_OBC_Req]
BO_ 2032 Diag_ECC_Req: 8 GW
 SG_ ECC_Byte2_Req : 15|8@0+ (1,0) [0|255] ""  ECC
 SG_ ECC_Byte3_Req : 23|8@0+ (1,0) [0|255] ""  ECC
 SG_ ECC_Byte4_Req : 31|8@0+ (1,0) [0|255] ""  ECC
 SG_ ECC_Byte5_Req : 39|8@0+ (1,0) [0|255] ""  ECC
 SG_ ECC_Byte6_Req : 47|8@0+ (1,0) [0|255] ""  ECC
 SG_ ECC_Byte7_Req : 55|8@0+ (1,0) [0|255] ""  ECC
 SG_ ECC_Byte8_Req : 63|8@0+ (1,0) [0|255] ""  ECC
 SG_ ECC_TPCI_Req : 7|8@0+ (1,0) [0|255] ""  ECC

BO_ 2035 Diag_OBC_Req: 8 GW
 SG_ OBC_Byte2_Req : 15|8@0+ (1,0) [0|255] ""  OBC
 SG_ OBC_Byte3_Req : 23|8@0+ (1,0) [0|255] ""  OBC
 SG_ OBC_Byte4_Req : 31|8@0+ (1,0) [0|255] ""  OBC
 SG_ OBC_Byte5_Req : 39|8@0+ (1,0) [0|255] ""  OBC
 SG_ OBC_Byte6_Req : 47|8@0+ (1,0) [0|255] ""  OBC
 SG_ OBC_Byte7_Req : 55|8@0+ (1,0) [0|255] ""  OBC
 SG_ OBC_Byte8_Req : 63|8@0+ (1,0) [0|255] ""  OBC
 SG_ OBC_TPCI_Req : 7|8@0+ (1,0) [0|255] ""  OBC

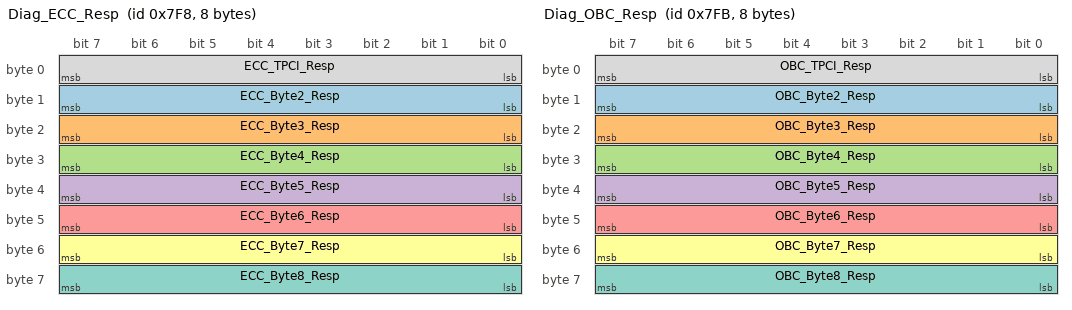
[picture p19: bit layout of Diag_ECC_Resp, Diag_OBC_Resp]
BO_ 2040 Diag_ECC_Resp: 8 ECC
 SG_ ECC_Byte2_Resp : 15|8@0+ (1,0) [0|255] ""  GW
 SG_ ECC_Byte3_Resp : 23|8@0+ (1,0) [0|255] ""  GW
 SG_ ECC_Byte4_Resp : 31|8@0+ (1,0) [0|255] ""  GW
 SG_ ECC_Byte5_Resp : 39|8@0+ (1,0) [0|255] ""  GW
 SG_ ECC_Byte6_Resp : 47|8@0+ (1,0) [0|255] ""  GW
 SG_ ECC_Byte7_Resp : 55|8@0+ (1,0) [0|255] ""  GW
 SG_ ECC_Byte8_Resp : 63|8@0+ (1,0) [0|255] ""  GW
 SG_ ECC_TPCI_Resp : 7|8@0+ (1,0) [0|255] ""  GW

BO_ 2043 Diag_OBC_Resp: 8 OBC
 SG_ OBC_Byte2_Resp : 15|8@0+ (1,0) [0|255] ""  GW
 SG_ OBC_Byte3_Resp : 23|8@0+ (1,0) [0|255] ""  GW
 SG_ OBC_Byte4_Resp : 31|8@0+ (1,0) [0|255] ""  GW
 SG_ OBC_Byte5_Resp : 39|8@0+ (1,0) [0|255] ""  GW
 SG_ OBC_Byte6_Resp : 47|8@0+ (1,0) [0|255] ""  GW
 SG_ OBC_Byte7_Resp : 55|8@0+ (1,0) [0|255] ""  GW
 SG_ OBC_Byte8_Resp : 63|8@0+ (1,0) [0|255] ""  GW
 SG_ OBC_TPCI_Resp : 7|8@0+ (1,0) [0|255] ""  GW

CM_ SG_ 1619 OBC_SwVersS "PDU software version number";
CM_ SG_ 1619 OBC_PartVers "PDU part number";
CM_ SG_ 1619 OBC_HwVers "PDU hardware version number";
CM_ SG_ 1619 OBC_SwVersM "PDU main software version number";
CM_ SG_ 1636 ECC_SwVersS "ECC software version number";
CM_ SG_ 1636 ECC_PartVers "ECC part number";
CM_ SG_ 1636 ECC_HwVers "ECC hardware version number";
CM_ SG_ 1636 ECC_SwVersM "ECC main software version number";
CM_ SG_ 1637 WTC_H_SwVersS "WTC_H software version number";
CM_ SG_ 1637 WTC_H_PartVers "WTC_H part assembly No.";
CM_ SG_ 1637 WTC_H_HwVers "WTC_H hardware version number";
CM_ SG_ 1637 WTC_H_SwVersM "WTC_H main software version number";
CM_ SG_ 1638 WTC_B_SwVersS "WTC_B software version number";
CM_ SG_ 1638 WTC_B_PartVers "WTC_B part assembly No.";
CM_ SG_ 1638 WTC_B_HwVers "WTC_B hardware version number";
CM_ SG_ 1638 WTC_B_SwVersM "WTC_B main software version number";
CM_ SG_ 1695 EAS_SwVersS "EAS software version number";
CM_ SG_ 1695 EAS_PartVers "EAS part assembly number";
CM_ SG_ 1695 EAS_HwVers "EAS hardware version number";
CM_ SG_ 1695 EAS_SwVersM "EAS main software version number";
CM_ SG_ 1696 BMS_mxCounterActEnergy "Date type for this message";
CM_ SG_ 1696 BMS_mxEnergyActValue1 "Signal  according valuetable or mxCounterActEnergy";
CM_ SG_ 1696 BMS_mxEnergyActValue2 "Signal  according valuetable or mxCounterActEnergy";
CM_ SG_ 1696 DCDC_ActTemp "DCDC actual temperature";
CM_ SG_ 1697 BMS_AccueChrgTotAh "Accumulated total charging ampere-hour";
CM_ SG_ 1697 BMS_AccueDchaTotAh "Cumulative discharge total ampere-hour";
CM_ SG_ 1698 VCU_SCChrgCnt "Statistics of slow charging times";
CM_ SG_ 1698 VCU_VehHVPwrOffTi "Static time of the vehicle when the high voltage is off (30 frames continuously after entering state 12/82/142)";
CM_ SG_ 1698 VCU_FCChrgCnt "Statistics of fast charging times";
CM_ SG_ 1701 BMS_CellMaxTOffset "Maximum temperature compensation value of single cell";
CM_ SG_ 1701 BMS_CellMinTOffset "Minimum temperature compensation value of single cell";
CM_ SG_ 1701 BMS_MinTCod "Minimum temperature number";
CM_ SG_ 1701 BMS_MinCellVoltCod "Minimum unit voltage number";
CM_ SG_ 1701 BMS_MaxCellVoltPackNr "Maximum single voltage package No.";
CM_ SG_ 1701 BMS_MaxTPackNr "Maximum temperature package number";
CM_ SG_ 1701 BMS_MinTPackNr "Minimum temperature package No.";
CM_ SG_ 1701 BMS_MinCellVoltPackNr "No. of minimum single voltage pack";
CM_ SG_ 1701 BMS_MaxCellVoltCod "Maximum unit voltage number";
CM_ SG_ 1701 BMS_MaxTCod "Maximum temperature number";
CM_ SG_ 1712 BMS_CellVolt1 "Cell voltage 1 # battery";
CM_ SG_ 1712 BMS_CellVolt2 "Cell voltage of No.2 battery";
CM_ SG_ 1712 BMS_CellVolt3 "Cell voltage of 3 # battery";
CM_ SG_ 1712 BMS_CellVolt4 "Cell voltage of 4 # battery";
CM_ SG_ 1713 BMS_CellVolt5 "Cell voltage of No.5 battery";
CM_ SG_ 1713 BMS_CellVolt6 "Cell voltage of 6 # battery";
CM_ SG_ 1713 BMS_CellVolt7 "Cell voltage of 7 # battery";
CM_ SG_ 1713 BMS_CellVolt8 "Cell voltage of 8 # battery";
CM_ SG_ 1714 BMS_CellVolt9 "Cell voltage of 9 # battery";
CM_ SG_ 1714 BMS_CellVolt10 "Cell voltage # 10";
CM_ SG_ 1714 BMS_CellVolt11 "Cell voltage of 11 # battery";
CM_ SG_ 1714 BMS_CellVolt12 "Cell voltage of 12 # battery";
CM_ SG_ 1715 BMS_CellVolt13 "Cell voltage of 13 # battery";
CM_ SG_ 1715 BMS_CellVolt14 "Cell voltage of 14 # battery";
CM_ SG_ 1715 BMS_CellVolt15 "Cell voltage of 15 # battery";
CM_ SG_ 1715 BMS_CellVolt16 "Cell voltage of 16 # battery";
CM_ SG_ 1716 BMS_CellVolt17 "Cell voltage of 17 # battery";
CM_ SG_ 1716 BMS_CellVolt18 "Cell voltage of 18 # battery";
CM_ SG_ 1716 BMS_CellVolt19 "Cell voltage of No.19";
CM_ SG_ 1716 BMS_CellVolt20 "Cell voltage of 20 # battery";
CM_ SG_ 1717 BMS_CellVolt21 "Cell voltage of 21 # battery";
CM_ SG_ 1717 BMS_CellVolt22 "Cell voltage of 22 # battery";
CM_ SG_ 1717 BMS_CellVolt23 "Cell voltage of 23 # battery";
CM_ SG_ 1717 BMS_CellVolt24 "Cell voltage of 24 # battery";
CM_ SG_ 1718 BMS_CellVolt25 "Cell voltage of 25 # battery";
CM_ SG_ 1718 BMS_CellVolt26 "Cell voltage of 26 # battery";
CM_ SG_ 1718 BMS_CellVolt27 "Cell voltage of No. 27";
CM_ SG_ 1718 BMS_CellVolt28 "Cell voltage of 28 # battery";
CM_ SG_ 1719 BMS_CellVolt29 "Cell voltage of # 29 battery";
CM_ SG_ 1719 BMS_CellVolt30 "Cell voltage # 30";
CM_ SG_ 1719 BMS_CellVolt31 "31 Battery cell voltage";
CM_ SG_ 1719 BMS_CellVolt32 "Cell voltage of 32 # battery";
CM_ SG_ 1720 BMS_CellVolt33 "Cell voltage # 33";
CM_ SG_ 1720 BMS_CellVolt34 "Cell voltage of 34 # battery";
CM_ SG_ 1720 BMS_CellVolt35 "Cell voltage of 35 # battery";
CM_ SG_ 1720 BMS_CellVolt36 "Cell voltage of 36 # battery";
CM_ SG_ 1721 BMS_CellVolt37 "Cell voltage of 37 # battery";
CM_ SG_ 1721 BMS_CellVolt38 "Cell voltage of 38 # battery";
CM_ SG_ 1721 BMS_CellVolt39 "Cell voltage # 39";
CM_ SG_ 1721 BMS_CellVolt40 "Cell voltage of 40 # battery";
CM_ SG_ 1722 BMS_CellVolt41 "Cell voltage of 41 # battery";
CM_ SG_ 1722 BMS_CellVolt42 "Cell voltage of 42 # battery";
CM_ SG_ 1722 BMS_CellVolt43 "Cell voltage of 43 # battery";
CM_ SG_ 1722 BMS_CellVolt44 "Cell voltage of 44 # battery";
CM_ SG_ 1723 BMS_CellVolt45 "Cell voltage of No.45 battery";
CM_ SG_ 1723 BMS_CellVolt46 "Cell voltage of 46 # battery";
CM_ SG_ 1723 BMS_CellVolt47 "Cell voltage of 47 # battery";
CM_ SG_ 1723 BMS_CellVolt48 "Cell voltage of 48 # battery";
CM_ SG_ 1724 BMS_CellVolt49 "Cell voltage of 49 # battery";
CM_ SG_ 1724 BMS_CellVolt50 "Cell voltage of 50 # battery";
CM_ SG_ 1724 BMS_CellVolt51 "Cell voltage of 51 # battery";
CM_ SG_ 1724 BMS_CellVolt52 "Cell voltage of 52 # battery";
CM_ SG_ 1725 BMS_CellVolt53 "Cell voltage of 53 # battery";
CM_ SG_ 1725 BMS_CellVolt54 "Cell voltage of 54 # battery";
CM_ SG_ 1725 BMS_CellVolt55 "Cell voltage of 55 # battery";
CM_ SG_ 1725 BMS_CellVolt56 "Cell voltage of 56 # battery";
CM_ SG_ 1726 BMS_CellVolt57 "Cell voltage of 57 # battery";
CM_ SG_ 1726 BMS_CellVolt58 "Cell voltage of 58 # battery";
CM_ SG_ 1726 BMS_CellVolt59 "Cell voltage of 59 # battery";
CM_ SG_ 1726 BMS_CellVolt60 "Cell voltage of 60 # battery";
CM_ SG_ 1727 BMS_CellVolt61 "Cell voltage of 61 # battery";
CM_ SG_ 1727 BMS_CellVolt62 "Cell voltage of 62 # battery";
CM_ SG_ 1727 BMS_CellVolt63 "Cell voltage of 63 # battery";
CM_ SG_ 1727 BMS_CellVolt64 "Cell voltage of 64 # battery";
CM_ SG_ 1728 BMS_CellVolt65 "Cell voltage of 65 # battery";
CM_ SG_ 1728 BMS_CellVolt66 "Cell voltage of 66 # battery";
CM_ SG_ 1728 BMS_CellVolt67 "Cell voltage of 67 # battery";
CM_ SG_ 1728 BMS_CellVolt68 "Cell voltage of 68 # battery";
CM_ SG_ 1729 BMS_CellVolt69 "Cell voltage of 69 # battery";
CM_ SG_ 1729 BMS_CellVolt70 "Cell voltage of 70 # battery";
CM_ SG_ 1729 BMS_CellVolt71 "Cell voltage of 71 # battery";
CM_ SG_ 1729 BMS_CellVolt72 "Cell voltage of 72 # battery";
CM_ SG_ 1730 BMS_CellVolt73 "Cell voltage of 73 # battery";
CM_ SG_ 1730 BMS_CellVolt74 "Cell voltage of 74 # battery";
CM_ SG_ 1730 BMS_CellVolt75 "Cell voltage of 75 # battery";
CM_ SG_ 1730 BMS_CellVolt76 "Cell voltage of 76 # battery";
CM_ SG_ 1731 BMS_CellVolt77 "Cell voltage of 77 # battery";
CM_ SG_ 1731 BMS_CellVolt78 "Cell voltage of 78 # battery";
CM_ SG_ 1731 BMS_CellVolt79 "Cell voltage of 79 # battery";
CM_ SG_ 1731 BMS_CellVolt80 "Cell voltage of 80 # battery";
CM_ SG_ 1732 BMS_CellVolt81 "Cell voltage of 81 # battery";
CM_ SG_ 1732 BMS_CellVolt82 "Cell voltage of 82 # battery";
CM_ SG_ 1732 BMS_CellVolt83 "Cell voltage # 83";
CM_ SG_ 1732 BMS_CellVolt84 "Cell voltage of 84 # battery";
CM_ SG_ 1733 BMS_CellVolt85 "Cell voltage of 85 # battery";
CM_ SG_ 1733 BMS_CellVolt86 "Cell voltage of 86 # battery";
CM_ SG_ 1733 BMS_CellVolt87 "Cell voltage of 87 # battery";
CM_ SG_ 1733 BMS_CellVolt88 "Cell voltage of 88 # battery";
CM_ SG_ 1734 BMS_CellVolt89 "Cell voltage of 89 # battery";
CM_ SG_ 1734 BMS_CellVolt90 "Cell voltage of 90 # battery";
CM_ SG_ 1734 BMS_CellVolt91 "Cell voltage of 91 # battery";
CM_ SG_ 1734 BMS_CellVolt92 "Cell voltage of 92 # battery";
CM_ SG_ 1735 BMS_CellVolt93 "Cell voltage of No93 battery";
CM_ SG_ 1735 BMS_CellVolt94 "Cell voltage of 94 # battery";
CM_ SG_ 1735 BMS_CellVolt95 "Cell voltage of 95 # battery";
CM_ SG_ 1735 BMS_CellVolt96 "Cell voltage of 96 # battery";
CM_ SG_ 1736 BMS_CellVolt97 "Cell voltage of 97 # battery";
CM_ SG_ 1736 BMS_CellVolt98 "Cell voltage of 98 # battery";
CM_ SG_ 1736 BMS_CellVolt99 "Cell voltage of 99 # battery";
CM_ SG_ 1736 BMS_CellVolt100 "Cell voltage of 100 # battery";
CM_ SG_ 1737 BMS_CellVolt101 "Cell voltage of 101 # battery";
CM_ SG_ 1737 BMS_CellVolt102 "Cell voltage of 102 # battery";
CM_ SG_ 1737 BMS_CellVolt103 "Cell voltage of battery # 103";
CM_ SG_ 1737 BMS_CellVolt104 "Cell voltage of 104 # battery";
CM_ SG_ 1738 BMS_CellVolt105 "Cell voltage of 105 # battery";
CM_ SG_ 1738 BMS_CellVolt106 "Cell voltage of 106 # battery";
CM_ SG_ 1738 BMS_CellVolt107 "Cell voltage of 107 # battery";
CM_ SG_ 1738 BMS_CellVolt108 "Cell voltage of 108 # battery";
CM_ SG_ 1739 BMS_CellVolt109 "Cell voltage of 109 # battery";
CM_ SG_ 1739 BMS_CellVolt110 "Cell voltage of 110 # battery";
CM_ SG_ 1739 BMS_CellVolt111 "Cell voltage of 111 # battery";
CM_ SG_ 1739 BMS_CellVolt112 "Cell voltage of 112 # battery";
CM_ SG_ 1740 BMS_CellVolt113 "Cell voltage of 113 # battery";
CM_ SG_ 1740 BMS_CellVolt114 "Cell voltage of 114 # battery";
CM_ SG_ 1740 BMS_CellVolt115 "Cell voltage of 115 # battery";
CM_ SG_ 1740 BMS_CellVolt116 "Cell voltage of 116# battery";
CM_ SG_ 1741 BMS_CellVolt117 "Cell voltage of 117 # battery";
CM_ SG_ 1741 BMS_CellVolt118 "Cell voltage of 118 # battery";
CM_ SG_ 1741 BMS_CellVolt119 "Cell voltage of 119 # battery";
CM_ SG_ 1741 BMS_CellVolt120 "Cell voltage of 120 # battery";
CM_ SG_ 1744 BMS_CellT1 "Temperature of No.1 inspection point";
CM_ SG_ 1744 BMS_CellT2 "Temperature at inspection point 2";
CM_ SG_ 1744 BMS_CellT3 "Temperature of No.3 inspection point";
CM_ SG_ 1744 BMS_CellT4 "Temperature at inspection point 4";
CM_ SG_ 1744 BMS_CellT5 "Temperature of No.5 inspection point";
CM_ SG_ 1744 BMS_CellT6 "Temperature of 6 # inspection point";
CM_ SG_ 1744 BMS_CellT7 "Temperature at 7 # inspection point";
CM_ SG_ 1744 BMS_CellT8 "Temperature of 8 # inspection point";
CM_ SG_ 1745 BMS_CellT9 "Temperature of # 9 inspection point";
CM_ SG_ 1745 BMS_CellT10 "10 # temperature inspection point temperature";
CM_ SG_ 1745 BMS_CellT11 "Temperature at 11 # inspection point";
CM_ SG_ 1745 BMS_CellT12 "Temperature at inspection point 12";
CM_ SG_ 1745 BMS_CellT13 "Temperature of # 13 inspection point";
CM_ SG_ 1745 BMS_CellT14 "Temperature of # 14 inspection point";
CM_ SG_ 1745 BMS_CellT15 "Temperature of No.15 inspection point";
CM_ SG_ 1745 BMS_CellT16 "Temperature of 16 # inspection point";
CM_ SG_ 1746 BMS_CellT17 "Temperature at 17 # inspection point";
CM_ SG_ 1746 BMS_CellT18 "Temperature of # 18 inspection point";
CM_ SG_ 1746 BMS_CellT19 "Temperature at No.19 inspection point";
CM_ SG_ 1746 BMS_CellT20 "Temperature at 20 # inspection point";
CM_ SG_ 1746 BMS_CellT21 "Temperature at No.21 inspection point";
CM_ SG_ 1746 BMS_CellT22 "Temperature at 22 # inspection point";
CM_ SG_ 1746 BMS_CellT23 "Temperature at No.23 inspection point";
CM_ SG_ 1746 BMS_CellT24 "Temperature at 24 # inspection point";
CM_ SG_ 1747 BMS_CellT25 "Temperature at 25 # inspection point";
CM_ SG_ 1747 BMS_CellT26 "Temperature at 26 # inspection point";
CM_ SG_ 1747 BMS_CellT27 "Temperature at inspection point No. 27";
CM_ SG_ 1747 BMS_CellT28 "Temperature at 28 # inspection point";
CM_ SG_ 1747 BMS_CellT29 "Temperature at 29 # inspection point";
CM_ SG_ 1747 BMS_CellT30 "Temperature at No.30 inspection point";
CM_ SG_ 1747 BMS_CellT31 "Temperature of No31 inspection point";
CM_ SG_ 1747 BMS_CellT32 "Temperature of 32 # inspection point";
CM_ SG_ 1748 BMS_CellT33 "Temperature at No.33 inspection point";
CM_ SG_ 1748 BMS_CellT34 "Temperature of inspection point 34";
CM_ SG_ 1748 BMS_CellT35 "Temperature of No.35 inspection point";
CM_ SG_ 1748 BMS_CellT36 "Temperature of No.36 inspection point";
CM_ SG_ 1748 BMS_CellT37 "Temperature of 37 # inspection point";
CM_ SG_ 1748 BMS_CellT38 "Temperature of 38 # inspection point";
CM_ SG_ 1748 BMS_CellT39 "Temperature of No39 inspection point";
CM_ SG_ 1748 BMS_CellT40 "Temperature # 40 inspection point";
CM_ SG_ 1749 BMS_CellT41 "Temperature # 41 inspection point";
CM_ SG_ 1749 BMS_CellT42 "Temperature at inspection point 42";
CM_ SG_ 1749 BMS_CellT43 "Temperature of 43 # inspection point";
CM_ SG_ 1749 BMS_CellT44 "Temperature of No44 inspection point";
CM_ SG_ 1749 BMS_CellT45 "Temperature of No.45 inspection point";
CM_ SG_ 1749 BMS_CellT46 "Temperature at 46 # inspection point";
CM_ SG_ 1749 BMS_CellT47 "Temperature at inspection point 47";
CM_ SG_ 1749 BMS_CellT48 "Temperature of inspection point 48";
CM_ SG_ 1750 BMS_CellT49 "Temperature at temperature inspection point 49";
CM_ SG_ 1750 BMS_CellT50 "Temperature at 50 # inspection point";
CM_ SG_ 1750 BMS_CellT51 "Temperature of temperature inspection point 51";
CM_ SG_ 1750 BMS_CellT52 "Temperature of inspection point 52";
CM_ SG_ 1750 BMS_CellT53 "Temperature of inspection point 53";
CM_ SG_ 1750 BMS_CellT54 "Temperature No. 54 inspection point temperature";
CM_ SG_ 1750 BMS_CellT55 "Temperature of No55 inspection point";
CM_ SG_ 1750 BMS_CellT56 "Temperature of inspection point 56";
CM_ SG_ 1751 BMS_CellT57 "Temperature of inspection point 57";
CM_ SG_ 1751 BMS_CellT58 "Temperature of No58 inspection point";
CM_ SG_ 1751 BMS_CellT59 "Temperature of 59 # inspection point";
CM_ SG_ 1751 BMS_CellT60 "Temperature No. 60 inspection point";
CM_ SG_ 1751 BMS_CellT61 "Temperature of 61 # inspection point";
CM_ SG_ 1751 BMS_CellT62 "Temperature inspection point No. 62";
CM_ SG_ 1751 BMS_CellT63 "Temperature No. 63 inspection point";
CM_ SG_ 1751 BMS_CellT64 "Temperature No. 64 inspection point";
CM_ SG_ 1752 BMS_CellT65 "Temperature of 65 # inspection point";
CM_ SG_ 1752 BMS_CellT66 "Temperature at inspection point 66";
CM_ SG_ 1752 BMS_CellT67 "Temperature at # 67 inspection point";
CM_ SG_ 1752 BMS_CellT68 "Temperature # 68 inspection point";
CM_ SG_ 1752 BMS_CellT69 "Temperature No. 69 inspection point";
CM_ SG_ 1752 BMS_CellT70 "Temperature of 70 # inspection point";
CM_ SG_ 1752 BMS_CellT71 "Temperature at 71 # inspection point";
CM_ SG_ 1752 BMS_CellT72 "Temperature at 72 # inspection point";
CM_ SG_ 1753 BMS_CellT73 "Temperature at No. 73 inspection point";
CM_ SG_ 1753 BMS_CellT74 "Temperature at inspection point 74";
CM_ SG_ 1753 BMS_CellT75 "Temperature of No.75 inspection point";
CM_ SG_ 1753 BMS_CellT76 "Temperature of inspection point 76";
CM_ SG_ 1753 BMS_CellT77 "Temperature of inspection point # 77";
CM_ SG_ 1753 BMS_CellT78 "Temperature of inspection point 78";
CM_ SG_ 1753 BMS_CellT79 "Temperature of No.79 inspection point";
CM_ SG_ 1753 BMS_CellT80 "Temperature of 80 # inspection point";
CM_ SG_ 1754 VCU_PwrGridAllwMaxPwrSplyCrt "Maximum allowable supply current of grid";
CM_ SG_ 1754 VCU_ChrgLineAllwtCrt "Allowable current of charging wire";
CM_ SG_ 1754 VCU_DchaLineAllwCrt "Allowable current of discharge wire";
CM_ SG_ 1754 VCU_DchaVehSts "Discharge vehicle state";
CM_ SG_ 1754 VCU_DCChrgSoktT1 "DC charging base temperature 1";
CM_ SG_ 1754 VCU_DCChrgSoktT2 "DC charging base temperature 2";
CM_ SG_ 1754 VCU_ACChrgDchaSoktT1 "AC charge and discharge seat temperature 1";
CM_ SG_ 1754 VCU_6DA_SSecOC_Fresh_Byte0 "Short SecOC Fresh signal byte 0 on CAN";
CM_ SG_ 1754 VCU_6DA_SSecOC_MAC_Byte0 "Short SecOC MAC signal byte 0 on CAN";
CM_ SG_ 1754 VCU_6DA_SSecOC_MAC_Byte1 "Short SecOC MAC signal byte 1 on CAN";
CM_ SG_ 1754 VCU_6DA_SSecOC_MAC_Byte2 "Short SecOC MAC signal byte 2 on CAN";
CM_ SG_ 1755 BMS_CellT81 "Temperature of No81 inspection point";
CM_ SG_ 1755 BMS_CellT82 "Temperature of inspection point 82";
CM_ SG_ 1755 BMS_CellT83 "Temperature of inspection point 83";
CM_ SG_ 1755 BMS_CellT84 "Temperature of inspection point 84";
CM_ SG_ 1755 BMS_CellT85 "Temperature of 85 # inspection point";
CM_ SG_ 1755 BMS_CellT86 "Temperature at inspection point 86";
CM_ SG_ 1755 BMS_CellT87 "Temperature of inspection point 87";
CM_ SG_ 1755 BMS_CellT88 "Temperature of No88 inspection point";
CM_ SG_ 1756 BMS_mxCounterEnergy "Date type for this message";
CM_ SG_ 1756 BMS_mxEnergyValue1 "Signal  according valuetable or mxCounterEnergy";
CM_ SG_ 1756 BMS_mxEnergyValue2 "Signal  according valuetable or mxCounterEnergy";
CM_ SG_ 1757 BMS_PVIU_actPower "actual delivered Power from PV-Panel";
CM_ SG_ 1757 BMS_PVIU_EnergyOverall "overall gathered energy";
CM_ SG_ 1757 BMS_PVIU_ActEngyYear "gathered actual energy of this year";
CM_ SG_ 1758 DCDC_CheckSum2 "chech sum for PVIU_0x6DE(E2E data ID: 0xD1)";
CM_ SG_ 1758 BMS_RollCounter2 "Rolling counter";
CM_ SG_ 1758 PVIU_DCDC_ActLVVolt "DCDC actual LV input voltage";
CM_ SG_ 1758 PVIU_DCDC_ActLVCurr "DCDC actual LV input current";
CM_ SG_ 1758 PVIU_DCDC_ActHVVolt "DCDC actual HV output voltage";
CM_ SG_ 1758 PVIU_DCDC_ActHVCurr "DCDC actual HV output current";
CM_ SG_ 1759 BMS_0x6DF_CheckSum "chech sum for BMS_PVIU_ErrorStatus(E2E data ID: 0xD2)";
CM_ SG_ 1759 BMS_0x6DF_RollCounter "Rolling counter";
CM_ SG_ 1759 BMS_PVIU_ModeReqSt "PVIU mode request status";
CM_ SG_ 1759 BMS_PVIU_ModeSt "PVIU operation mode";
CM_ SG_ 1759 BMS_PVIU_AvailInputPower "PVIU available input power";
CM_ SG_ 1759 BMS_PVIU_ActOutputPower "PVIU real time output power during power on cycle";
CM_ SG_ 1759 BMS_PVIU_ActOutputEnergy "PVIU real time output energy during power on cycle";
CM_ SG_ 1759 BMS_PVIU_FailSt "PVIU failure status";
CM_ SG_ 1759 BMS_PVIU_F_Input_OVP "PVIU input over voltage";
CM_ SG_ 1759 BMS_PVIU_F_Input_UVP "PVIU input under voltage";
CM_ SG_ 1759 BMS_PVIU_F_Output_OVP "PVIU output over voltage";
CM_ SG_ 1759 BMS_PVIU_F_Output_UVP "PVIU output under voltage";
CM_ SG_ 1759 BMS_PVIU_F_12V_OVP "PVIU 12v over voltage";
CM_ SG_ 1759 BMS_PVIU_F_12V_UVP "PVIU 12v under voltage";
CM_ SG_ 1759 BMS_PVIU_F_Output_SCP "PVIU output short circuit in normal mode";
CM_ SG_ 1759 BMS_PVIU_F_OTP "PVIU over temperature";
CM_ SG_ 1759 BMS_PVIU_F_HVIL "PVIU HVIL status on HV output connector";
CM_ SG_ 1759 BMS_PVIU_F_CANRx_Timeout "PVIU receive CAN message timeout";
CM_ SG_ 1759 BMS_PVIU_F_Output_OCP "PVIU output over current";
CM_ SG_ 1760 BCM_VIN_Byte1 "This Signal contains the seventh-last position of the vehicle identification number (positions are coded in ASCII).";
CM_ SG_ 1760 BCM_VIN_Byte2 "This Signal contains the sixth-last position of the vehicle identification number (positions are coded in ASCII).";
CM_ SG_ 1760 BCM_VIN_Byte3 "This Signal contains the fifth-last position of the vehicle identification number (positions are coded in ASCII).";
CM_ SG_ 1760 BCM_VIN_Byte4 "This Signal contains the fourth-last position of the vehicle identification number (positions are coded in ASCII).";
CM_ SG_ 1760 BCM_VIN_Byte5 "This Signal contains the third-last position of the vehicle identification number (positions are coded in ASCII).";
CM_ SG_ 1760 BCM_VIN_Byte6 "This Signal contains the second-last position of the vehicle identification number (positions are coded in ASCII).";
CM_ SG_ 1760 BCM_VIN_Byte7 "This Signal contains the last position of the vehicle identification number (positions are coded in ASCII).";
CM_ SG_ 1765 VCU_VINCod1 "VIN number 1 (indicating 1 to 8 ASC values in the number)VCUVINCode_1(Bit1~8ofASCII)";
CM_ SG_ 1766 VCU_VINCod2 "VIN number 2 (indicating 9 to 16 ASC values in the number)VCUVINCode_2(Bit9~16ofASCII)";
CM_ SG_ 1767 VCU_VINCod3 "VIN number 3 (indicating 17 to 24 ASC values in number)VCUVINCode_3(Bit17~24ofASCII)";
CM_ SG_ 1776 BMS_PwrBattPackCod1 "Power battery pack number 1 (indicating 1 to 8 ASC code values in the number)";
CM_ SG_ 1777 BMS_PwrBattPackCod2 "Power battery pack number 2 (indicating 9 to 16 ASC codes in number)";
CM_ SG_ 1778 BMS_PwrBattPackCod3 "Power battery pack number 3 (indicating 17 to 24 ASC codes in number)";
CM_ SG_ 1779 BMS_PwrBattPackCod4 "Power battery pack number 4 (indicating 25 to 32 ASC codes in number)";
CM_ SG_ 1780 BMS_PwrBattPackNr "Number of power battery packs";
CM_ SG_ 1780 BMS_PwrBattPackCodLen "Number length of power battery pack";
CM_ SG_ 1780 BMS_PwrBattSubsysNr "Serial number of power battery subsystem";
CM_ SG_ 1780 BMS_PwrBattCellSum "Total number of power battery cells";
CM_ SG_ 1780 BMS_PwrBattCellTSum "Total number of traction battery temperature points";
CM_ SG_ 1780 BMS_PwrBattFltSum "Total number of power battery faults";
CM_ SG_ 1791 VCU_BattChrgSOC "Battery SOC correction value";
CM_ SG_ 1791 VCU_BattChrgSOCEEPROM "Battery SOC EEPROM storage value";
CM_ SG_ 1791 VCU_UsrAvrgPwrCns "Average power consumption of user condition";
CM_ SG_ 1791 VCU_DrvgMilgReqReducePwrLvl "Driving range request power level drop";
CM_ SG_ 1796 BMS_XCP_Tx_Byte0 "XCP signal";
CM_ SG_ 1796 BMS_XCP_Tx_Byte1 "XCP signal";
CM_ SG_ 1796 BMS_XCP_Tx_Byte2 "XCP signal";
CM_ SG_ 1796 BMS_XCP_Tx_Byte3 "XCP signal";
CM_ SG_ 1796 BMS_XCP_Tx_Byte4 "XCP signal";
CM_ SG_ 1796 BMS_XCP_Tx_Byte5 "XCP signal";
CM_ SG_ 1796 BMS_XCP_Tx_Byte6 "XCP signal";
CM_ SG_ 1796 BMS_XCP_Tx_Byte7 "XCP signal";
CM_ SG_ 1797 BMS_XCP_Rx_Byte0 "XCP signal";
CM_ SG_ 1797 BMS_XCP_Rx_Byte1 "XCP signal";
CM_ SG_ 1797 BMS_XCP_Rx_Byte2 "XCP signal";
CM_ SG_ 1797 BMS_XCP_Rx_Byte3 "XCP signal";
CM_ SG_ 1797 BMS_XCP_Rx_Byte4 "XCP signal";
CM_ SG_ 1797 BMS_XCP_Rx_Byte5 "XCP signal";
CM_ SG_ 1797 BMS_XCP_Rx_Byte6 "XCP signal";
CM_ SG_ 1797 BMS_XCP_Rx_Byte7 "XCP signal";
CM_ SG_ 1812 OBC_FailCode "OBC failure code";
CM_ SG_ 1812 DCDC_FailCode "DCDC failure code";
CM_ SG_ 1812 DCDC_TempMOS "DCDC MOS temperatur";
CM_ SG_ 1812 OBC_LLCTemp "OBC  LLC temperatur";
CM_ SG_ 1812 DCDC_ULV1_1 "DCDC Low Voltage";
CM_ SG_ 1812 OBC_PFCTemp "OBC Pfc temperatur";
CM_ SG_ 1812 DCDC_ClampCapVol "Clamp Cap Voltage";
CM_ SG_ 1812 OBC_CtrlActMode "OBC control  mode";
CM_ SG_ 1812 DCDC_CtrlMode "DCDC control mode";
CM_ SG_ 1812 PDU_DCPortVoltage "PDU DC charger side voltage";
CM_ SG_ 1812 PDU_BATVoltage "PDU battery side  voltage";
CM_ SG_ 1812 Hw_Fault_Flag "Hardware Fault Flag";
CM_ SG_ 1812 OBC_ElockCtrlCmd "Elock Control command";
CM_ SG_ 1874 WTC_H_Byte2_Req "Diagnostic signal";
CM_ SG_ 1874 WTC_H_Byte3_Req "Diagnostic signal";
CM_ SG_ 1874 WTC_H_Byte4_Req "Diagnostic signal";
CM_ SG_ 1874 WTC_H_Byte5_Req "Diagnostic signal";
CM_ SG_ 1874 WTC_H_Byte6_Req "Diagnostic signal";
CM_ SG_ 1874 WTC_H_Byte7_Req "Diagnostic signal";
CM_ SG_ 1874 WTC_H_Byte8_Req "Diagnostic signal";
CM_ SG_ 1874 WTC_H_TPCI_Req "Diagnostic signal";
CM_ SG_ 1882 WTC_H_Byte2_Resp "Diagnostic signal";
CM_ SG_ 1882 WTC_H_Byte3_Resp "Diagnostic signal";
CM_ SG_ 1882 WTC_H_Byte4_Resp "Diagnostic signal";
CM_ SG_ 1882 WTC_H_Byte5_Resp "Diagnostic signal";
CM_ SG_ 1882 WTC_H_Byte6_Resp "Diagnostic signal";
CM_ SG_ 1882 WTC_H_Byte7_Resp "Diagnostic signal";
CM_ SG_ 1882 WTC_H_Byte8_Resp "Diagnostic signal";
CM_ SG_ 1882 WTC_H_TPCI_Resp "Diagnostic signal";
CM_ SG_ 1937 PVIU_Byte2_Req "Diagnostic signal";
CM_ SG_ 1937 PVIU_Byte3_Req "Diagnostic signal";
CM_ SG_ 1937 PVIU_Byte4_Req "Diagnostic signal";
CM_ SG_ 1937 PVIU_Byte5_Req "Diagnostic signal";
CM_ SG_ 1937 PVIU_Byte6_Req "Diagnostic signal";
CM_ SG_ 1937 PVIU_Byte7_Req "Diagnostic signal";
CM_ SG_ 1937 PVIU_Byte8_Req "Diagnostic signal";
CM_ SG_ 1937 PVIU_TPCI_Req "Diagnostic signal";
CM_ SG_ 1945 PVIU_Byte2_Resp "Diagnostic signal";
CM_ SG_ 1945 PVIU_Byte3_Resp "Diagnostic signal";
CM_ SG_ 1945 PVIU_Byte4_Resp "Diagnostic signal";
CM_ SG_ 1945 PVIU_Byte5_Resp "Diagnostic signal";
CM_ SG_ 1945 PVIU_Byte6_Resp "Diagnostic signal";
CM_ SG_ 1945 PVIU_Byte7_Resp "Diagnostic signal";
CM_ SG_ 1945 PVIU_Byte8_Resp "Diagnostic signal";
CM_ SG_ 1945 PVIU_TPCI_Resp "Diagnostic signal";
CM_ SG_ 1986 VCU_Byte2_Req "Diagnostic signal";
CM_ SG_ 1986 VCU_Byte3_Req "Diagnostic signal";
CM_ SG_ 1986 VCU_Byte4_Req "Diagnostic signal";
CM_ SG_ 1986 VCU_Byte5_Req "Diagnostic signal";
CM_ SG_ 1986 VCU_Byte6_Req "Diagnostic signal";
CM_ SG_ 1986 VCU_Byte7_Req "Diagnostic signal";
CM_ SG_ 1986 VCU_Byte8_Req "Diagnostic signal";
CM_ SG_ 1986 VCU_TPCI_Req "Diagnostic signal";
CM_ SG_ 1994 VCU_Byte2_Resp "Diagnostic signal";
CM_ SG_ 1994 VCU_Byte3_Resp "Diagnostic signal";
CM_ SG_ 1994 VCU_Byte4_Resp "Diagnostic signal";
CM_ SG_ 1994 VCU_Byte5_Resp "Diagnostic signal";
CM_ SG_ 1994 VCU_Byte6_Resp "Diagnostic signal";
CM_ SG_ 1994 VCU_Byte7_Resp "Diagnostic signal";
CM_ SG_ 1994 VCU_Byte8_Resp "Diagnostic signal";
CM_ SG_ 1994 VCU_TPCI_Resp "Diagnostic signal";
CM_ SG_ 2005 WTC_B_Byte2_Req "Diagnostic signal";
CM_ SG_ 2005 WTC_B_Byte3_Req "Diagnostic signal";
CM_ SG_ 2005 WTC_B_Byte4_Req "Diagnostic signal";
CM_ SG_ 2005 WTC_B_Byte5_Req "Diagnostic signal";
CM_ SG_ 2005 WTC_B_Byte6_Req "Diagnostic signal";
CM_ SG_ 2005 WTC_B_Byte7_Req "Diagnostic signal";
CM_ SG_ 2005 WTC_B_Byte8_Req "Diagnostic signal";
CM_ SG_ 2005 WTC_B_TPCI_Req "Diagnostic signal";
CM_ SG_ 2013 WTC_B_Byte2_Resp "Diagnostic signal";
CM_ SG_ 2013 WTC_B_Byte3_Resp "Diagnostic signal";
CM_ SG_ 2013 WTC_B_Byte4_Resp "Diagnostic signal";
CM_ SG_ 2013 WTC_B_Byte5_Resp "Diagnostic signal";
CM_ SG_ 2013 WTC_B_Byte6_Resp "Diagnostic signal";
CM_ SG_ 2013 WTC_B_Byte7_Resp "Diagnostic signal";
CM_ SG_ 2013 WTC_B_Byte8_Resp "Diagnostic signal";
CM_ SG_ 2013 WTC_B_TPCI_Resp "Diagnostic signal";
CM_ SG_ 2015 Tester_Byte2_Req "Diagnostic signal";
CM_ SG_ 2015 Tester_Byte3_Req "Diagnostic signal";
CM_ SG_ 2015 Tester_Byte4_Req "Diagnostic signal";
CM_ SG_ 2015 Tester_Byte5_Req "Diagnostic signal";
CM_ SG_ 2015 Tester_Byte6_Req "Diagnostic signal";
CM_ SG_ 2015 Tester_Byte7_Req "Diagnostic signal";
CM_ SG_ 2015 Tester_Byte8_Req "Diagnostic signal";
CM_ SG_ 2015 Tester_TPCI_Req "Diagnostic signal";
CM_ SG_ 2016 VCU_OBD_Byte2_Req "Diagnostic signal";
CM_ SG_ 2016 VCU_OBD_Byte3_Req "Diagnostic signal";
CM_ SG_ 2016 VCU_OBD_Byte4_Req "Diagnostic signal";
CM_ SG_ 2016 VCU_OBD_Byte5_Req "Diagnostic signal";
CM_ SG_ 2016 VCU_OBD_Byte6_Req "Diagnostic signal";
CM_ SG_ 2016 VCU_OBD_Byte7_Req "Diagnostic signal";
CM_ SG_ 2016 VCU_OBD_Byte8_Req "Diagnostic signal";
CM_ SG_ 2016 VCU_OBD_TPCI_Req "Diagnostic signal";
CM_ SG_ 2017 BMS_Byte2_Req "Diagnostic signal";
CM_ SG_ 2017 BMS_Byte3_Req "Diagnostic signal";
CM_ SG_ 2017 BMS_Byte4_Req "Diagnostic signal";
CM_ SG_ 2017 BMS_Byte5_Req "Diagnostic signal";
CM_ SG_ 2017 BMS_Byte6_Req "Diagnostic signal";
CM_ SG_ 2017 BMS_Byte7_Req "Diagnostic signal";
CM_ SG_ 2017 BMS_Byte8_Req "Diagnostic signal";
CM_ SG_ 2017 BMS_TPCI_Req "Diagnostic signal";
CM_ SG_ 2018 EAS_Byte2_Req "Diagnostic signal";
CM_ SG_ 2018 EAS_Byte3_Req "Diagnostic signal";
CM_ SG_ 2018 EAS_Byte4_Req "Diagnostic signal";
CM_ SG_ 2018 EAS_Byte5_Req "Diagnostic signal";
CM_ SG_ 2018 EAS_Byte6_Req "Diagnostic signal";
CM_ SG_ 2018 EAS_Byte7_Req "Diagnostic signal";
CM_ SG_ 2018 EAS_Byte8_Req "Diagnostic signal";
CM_ SG_ 2018 EAS_TPCI_Req "Diagnostic signal";
CM_ SG_ 2024 VCU_OBD_Byte2_Resp "Diagnostic signal";
CM_ SG_ 2024 VCU_OBD_Byte3_Resp "Diagnostic signal";
CM_ SG_ 2024 VCU_OBD_Byte4_Resp "Diagnostic signal";
CM_ SG_ 2024 VCU_OBD_Byte5_Resp "Diagnostic signal";
CM_ SG_ 2024 VCU_OBD_Byte6_Resp "Diagnostic signal";
CM_ SG_ 2024 VCU_OBD_Byte7_Resp "Diagnostic signal";
CM_ SG_ 2024 VCU_OBD_Byte8_Resp "Diagnostic signal";
CM_ SG_ 2024 VCU_OBD_TPCI_Resp "Diagnostic signal";
CM_ SG_ 2025 BMS_Byte2_Resp "Diagnostic signal";
CM_ SG_ 2025 BMS_Byte3_Resp "Diagnostic signal";
CM_ SG_ 2025 BMS_Byte4_Resp "Diagnostic signal";
CM_ SG_ 2025 BMS_Byte5_Resp "Diagnostic signal";
CM_ SG_ 2025 BMS_Byte6_Resp "Diagnostic signal";
CM_ SG_ 2025 BMS_Byte7_Resp "Diagnostic signal";
CM_ SG_ 2025 BMS_Byte8_Resp "Diagnostic signal";
CM_ SG_ 2025 BMS_TPCI_Resp "Diagnostic signal";
CM_ SG_ 2026 EAS_Byte2_Resp "Diagnostic signal";
CM_ SG_ 2026 EAS_Byte3_Resp "Diagnostic signal";
CM_ SG_ 2026 EAS_Byte4_Resp "Diagnostic signal";
CM_ SG_ 2026 EAS_Byte5_Resp "Diagnostic signal";
CM_ SG_ 2026 EAS_Byte6_Resp "Diagnostic signal";
CM_ SG_ 2026 EAS_Byte7_Resp "Diagnostic signal";
CM_ SG_ 2026 EAS_Byte8_Resp "Diagnostic signal";
CM_ SG_ 2026 EAS_TPCI_Resp "Diagnostic signal";
CM_ SG_ 2032 ECC_Byte2_Req "Diagnostic signal";
CM_ SG_ 2032 ECC_Byte3_Req "Diagnostic signal";
CM_ SG_ 2032 ECC_Byte4_Req "Diagnostic signal";
CM_ SG_ 2032 ECC_Byte5_Req "Diagnostic signal";
CM_ SG_ 2032 ECC_Byte6_Req "Diagnostic signal";
CM_ SG_ 2032 ECC_Byte7_Req "Diagnostic signal";
CM_ SG_ 2032 ECC_Byte8_Req "Diagnostic signal";
CM_ SG_ 2032 ECC_TPCI_Req "Diagnostic signal";
CM_ SG_ 2035 OBC_Byte2_Req "Diagnostic signal";
CM_ SG_ 2035 OBC_Byte3_Req "Diagnostic signal";
CM_ SG_ 2035 OBC_Byte4_Req "Diagnostic signal";
CM_ SG_ 2035 OBC_Byte5_Req "Diagnostic signal";
CM_ SG_ 2035 OBC_Byte6_Req "Diagnostic signal";
CM_ SG_ 2035 OBC_Byte7_Req "Diagnostic signal";
CM_ SG_ 2035 OBC_Byte8_Req "Diagnostic signal";
CM_ SG_ 2035 OBC_TPCI_Req "Diagnostic signal";
CM_ SG_ 2040 ECC_Byte2_Resp "Diagnostic signal";
CM_ SG_ 2040 ECC_Byte3_Resp "Diagnostic signal";
CM_ SG_ 2040 ECC_Byte4_Resp "Diagnostic signal";
CM_ SG_ 2040 ECC_Byte5_Resp "Diagnostic signal";
CM_ SG_ 2040 ECC_Byte6_Resp "Diagnostic signal";
CM_ SG_ 2040 ECC_Byte7_Resp "Diagnostic signal";
CM_ SG_ 2040 ECC_Byte8_Resp "Diagnostic signal";
CM_ SG_ 2040 ECC_TPCI_Resp "Diagnostic signal";
CM_ SG_ 2043 OBC_Byte2_Resp "Diagnostic signal";
CM_ SG_ 2043 OBC_Byte3_Resp "Diagnostic signal";
CM_ SG_ 2043 OBC_Byte4_Resp "Diagnostic signal";
CM_ SG_ 2043 OBC_Byte5_Resp "Diagnostic signal";
CM_ SG_ 2043 OBC_Byte6_Resp "Diagnostic signal";
CM_ SG_ 2043 OBC_Byte7_Resp "Diagnostic signal";
CM_ SG_ 2043 OBC_Byte8_Resp "Diagnostic signal";
CM_ SG_ 2043 OBC_TPCI_Resp "Diagnostic signal";
BA_DEF_ BO_  "NmAsrMessage" ENUM  "No","Yes";
BA_DEF_ SG_  "GenSigCycleTime" INT 0 0;
BA_DEF_ BO_  "NmMessage" ENUM  "No","Yes";
BA_DEF_ BO_  "SC_Message" ENUM  "No","Yes","Yes, split message";
BA_DEF_ BO_  "DiagState" ENUM  "No","Yes";
BA_DEF_ BO_  "SC_LinkPos" INT 0 65535;
BA_DEF_ BO_  "DiagRequest" ENUM  "No","Yes";
BA_DEF_ BO_  "DiagFdOnly" ENUM  "No","Yes";
BA_DEF_ BO_  "DiagResponse" ENUM  "No","Yes";
BA_DEF_ BO_  "SCP_AuthInfoTxLength" INT 0 512;
BA_DEF_ BO_  "GenMsgSendType" ENUM  "Cyclic","NotUsed","NotUsed","NotUsed","NotUsed","NotUsed","NotUsed","IfActive","NoMsgSendType";
BA_DEF_ BO_  "SCP_DataId" INT 0 65535;
BA_DEF_ BO_  "GenMsgCycleTime" INT 0 0;
BA_DEF_ BO_  "SCP_FreshnessValueId" INT 0 65535;
BA_DEF_ BO_  "SCP_FreshnessValueLength" INT 0 512;
BA_DEF_ SG_  "GenSigStartValue" INT 0 0;
BA_DEF_ BO_  "SCL_CryptographicMessageID" INT 0 65535;
BA_DEF_ SG_  "GenSigInactiveValue" INT 0 0;
BA_DEF_ SG_  "GenSigSendType" ENUM  "Cyclic","OnWrite","OnWriteWithRepetition","OnChange","OnChangeWithRepetition","IfActive","IfActiveWithRepetition","NoSigSendType";
BA_DEF_ BO_  "SCP_FreshnessValueTxLength" INT 0 512;
BA_DEF_ BO_  "GenMsgCycleTimeFast" INT 0 0;
BA_DEF_ BO_  "GenMsgNrOfRepetition" INT 0 0;
BA_DEF_ BO_  "DiagConnection" INT 0 65535;
BA_DEF_ BO_  "GenMsgDelayTime" INT 0 0;
BA_DEF_ BO_  "CANFD_BRS" ENUM  "0","1";
BA_DEF_ BO_  "VFrameFormat" ENUM  "StandardCAN","ExtendedCAN","reserved","reserved","reserved","reserved","reserved","reserved","reserved","reserved","reserved","reserved","reserved","reserved","StandardCAN_FD","ExtendedCAN_FD";
BA_DEF_ BO_  "GenMsgILSupport" ENUM  "No","Yes";
BA_DEF_ BO_  "GenMsgStartDelayTime" INT 0 65535;
BA_DEF_ BO_  "E2EP01DataLength" INT 0 65535;
BA_DEF_ BO_  "E2EP01DataId" INT 0 65535;
BA_DEF_ SG_  "sigSecLevel" STRING ;
BA_DEF_ SG_  "sigConfig" STRING ;
BA_DEF_ SG_  "sigExplanation" STRING ;
BA_DEF_ SG_  "SystemSignalLongSymbol" STRING ;
BA_DEF_REL_ BU_SG_REL_  "SC_Verification" ENUM  "No","Yes";
BA_DEF_DEF_  "NmAsrMessage" "No";
BA_DEF_DEF_  "GenSigCycleTime" 0;
BA_DEF_DEF_  "NmMessage" "No";
BA_DEF_DEF_  "SC_Message" "No";
BA_DEF_DEF_  "DiagState" "No";
BA_DEF_DEF_  "SC_LinkPos" 0;
BA_DEF_DEF_  "DiagRequest" "No";
BA_DEF_DEF_  "DiagFdOnly" "No";
BA_DEF_DEF_  "DiagResponse" "No";
BA_DEF_DEF_  "SCP_AuthInfoTxLength" 0;
BA_DEF_DEF_  "GenMsgSendType" "Cyclic";
BA_DEF_DEF_  "SCP_DataId" 0;
BA_DEF_DEF_  "GenMsgCycleTime" 0;
BA_DEF_DEF_  "SCP_FreshnessValueId" 0;
BA_DEF_DEF_  "SCP_FreshnessValueLength" 0;
BA_DEF_DEF_  "GenSigStartValue" 0;
BA_DEF_DEF_  "SCL_CryptographicMessageID" 0;
BA_DEF_DEF_  "GenSigInactiveValue" 0;
BA_DEF_DEF_  "GenSigSendType" "Cyclic";
BA_DEF_DEF_  "SCP_FreshnessValueTxLength" 0;
BA_DEF_DEF_  "GenMsgCycleTimeFast" 0;
BA_DEF_DEF_  "GenMsgNrOfRepetition" 0;
BA_DEF_DEF_  "DiagConnection" 0;
BA_DEF_DEF_  "GenMsgDelayTime" 0;
BA_DEF_DEF_  "CANFD_BRS" "1";
BA_DEF_DEF_  "VFrameFormat" "StandardCAN";
BA_DEF_DEF_  "GenMsgILSupport" "Yes";
BA_DEF_DEF_  "GenMsgStartDelayTime" 0;
BA_DEF_DEF_  "E2EP01DataLength" 0;
BA_DEF_DEF_  "E2EP01DataId" 0;
BA_DEF_DEF_  "sigSecLevel" "";
BA_DEF_DEF_  "sigConfig" "";
BA_DEF_DEF_  "sigExplanation" "";
BA_DEF_DEF_REL_ "SC_Verification" "No";
BA_DEF_DEF_  "SystemSignalLongSymbol" "";
BA_ "GenMsgCycleTime" BO_ 1619 1000;
BA_ "VFrameFormat" BO_ 1619 14;
BA_ "GenMsgCycleTime" BO_ 1636 1000;
BA_ "VFrameFormat" BO_ 1636 14;
BA_ "GenMsgCycleTime" BO_ 1637 1000;
BA_ "VFrameFormat" BO_ 1637 14;
BA_ "GenMsgCycleTime" BO_ 1638 1000;
BA_ "VFrameFormat" BO_ 1638 14;
BA_ "GenMsgCycleTime" BO_ 1695 1000;
BA_ "VFrameFormat" BO_ 1695 14;
BA_ "GenMsgCycleTime" BO_ 1696 500;
BA_ "VFrameFormat" BO_ 1696 14;
BA_ "GenMsgCycleTime" BO_ 1697 2000;
BA_ "VFrameFormat" BO_ 1697 14;
BA_ "GenMsgCycleTime" BO_ 1698 2000;
BA_ "VFrameFormat" BO_ 1698 14;
BA_ "GenMsgCycleTime" BO_ 1701 1000;
BA_ "VFrameFormat" BO_ 1701 14;
BA_ "GenMsgCycleTime" BO_ 1712 2000;
BA_ "VFrameFormat" BO_ 1712 14;
BA_ "GenMsgCycleTime" BO_ 1713 2000;
BA_ "VFrameFormat" BO_ 1713 14;
BA_ "GenMsgCycleTime" BO_ 1714 2000;
BA_ "VFrameFormat" BO_ 1714 14;
BA_ "GenMsgCycleTime" BO_ 1715 2000;
BA_ "VFrameFormat" BO_ 1715 14;
BA_ "GenMsgCycleTime" BO_ 1716 2000;
BA_ "VFrameFormat" BO_ 1716 14;
BA_ "GenMsgCycleTime" BO_ 1717 2000;
BA_ "VFrameFormat" BO_ 1717 14;
BA_ "GenMsgCycleTime" BO_ 1718 2000;
BA_ "VFrameFormat" BO_ 1718 14;
BA_ "GenMsgCycleTime" BO_ 1719 2000;
BA_ "VFrameFormat" BO_ 1719 14;
BA_ "GenMsgCycleTime" BO_ 1720 2000;
BA_ "VFrameFormat" BO_ 1720 14;
BA_ "GenMsgCycleTime" BO_ 1721 2000;
BA_ "VFrameFormat" BO_ 1721 14;
BA_ "GenMsgCycleTime" BO_ 1722 2000;
BA_ "VFrameFormat" BO_ 1722 14;
BA_ "GenMsgCycleTime" BO_ 1723 2000;
BA_ "VFrameFormat" BO_ 1723 14;
BA_ "GenMsgCycleTime" BO_ 1724 2000;
BA_ "VFrameFormat" BO_ 1724 14;
BA_ "GenMsgCycleTime" BO_ 1725 2000;
BA_ "VFrameFormat" BO_ 1725 14;
BA_ "GenMsgCycleTime" BO_ 1726 2000;
BA_ "VFrameFormat" BO_ 1726 14;
BA_ "GenMsgCycleTime" BO_ 1727 2000;
BA_ "VFrameFormat" BO_ 1727 14;
BA_ "GenMsgCycleTime" BO_ 1728 2000;
BA_ "VFrameFormat" BO_ 1728 14;
BA_ "GenMsgCycleTime" BO_ 1729 2000;
BA_ "VFrameFormat" BO_ 1729 14;
BA_ "GenMsgCycleTime" BO_ 1730 2000;
BA_ "VFrameFormat" BO_ 1730 14;
BA_ "GenMsgCycleTime" BO_ 1731 2000;
BA_ "VFrameFormat" BO_ 1731 14;
BA_ "GenMsgCycleTime" BO_ 1732 2000;
BA_ "VFrameFormat" BO_ 1732 14;
BA_ "GenMsgCycleTime" BO_ 1733 2000;
BA_ "VFrameFormat" BO_ 1733 14;
BA_ "GenMsgCycleTime" BO_ 1734 2000;
BA_ "VFrameFormat" BO_ 1734 14;
BA_ "GenMsgCycleTime" BO_ 1735 2000;
BA_ "VFrameFormat" BO_ 1735 14;
BA_ "GenMsgCycleTime" BO_ 1736 2000;
BA_ "VFrameFormat" BO_ 1736 14;
BA_ "GenMsgCycleTime" BO_ 1737 2000;
BA_ "VFrameFormat" BO_ 1737 14;
BA_ "GenMsgCycleTime" BO_ 1738 2000;
BA_ "VFrameFormat" BO_ 1738 14;
BA_ "GenMsgCycleTime" BO_ 1739 2000;
BA_ "VFrameFormat" BO_ 1739 14;
BA_ "GenMsgCycleTime" BO_ 1740 2000;
BA_ "VFrameFormat" BO_ 1740 14;
BA_ "GenMsgCycleTime" BO_ 1741 2000;
BA_ "VFrameFormat" BO_ 1741 14;
BA_ "GenMsgCycleTime" BO_ 1744 2000;
BA_ "VFrameFormat" BO_ 1744 14;
BA_ "GenMsgCycleTime" BO_ 1745 2000;
BA_ "VFrameFormat" BO_ 1745 14;
BA_ "GenMsgCycleTime" BO_ 1746 2000;
BA_ "VFrameFormat" BO_ 1746 14;
BA_ "GenMsgCycleTime" BO_ 1747 2000;
BA_ "VFrameFormat" BO_ 1747 14;
BA_ "GenMsgCycleTime" BO_ 1748 2000;
BA_ "VFrameFormat" BO_ 1748 14;
BA_ "GenMsgCycleTime" BO_ 1749 2000;
BA_ "VFrameFormat" BO_ 1749 14;
BA_ "GenMsgCycleTime" BO_ 1750 2000;
BA_ "VFrameFormat" BO_ 1750 14;
BA_ "GenMsgCycleTime" BO_ 1751 2000;
BA_ "VFrameFormat" BO_ 1751 14;
BA_ "GenMsgCycleTime" BO_ 1752 2000;
BA_ "VFrameFormat" BO_ 1752 14;
BA_ "GenMsgCycleTime" BO_ 1753 2000;
BA_ "VFrameFormat" BO_ 1753 14;
BA_ "GenMsgCycleTime" BO_ 1754 1000;
BA_ "SCL_CryptographicMessageID" BO_ 1754 1754;
BA_ "SCP_AuthInfoTxLength" BO_ 1754 24;
BA_ "SCP_DataId" BO_ 1754 1754;
BA_ "SCP_FreshnessValueId" BO_ 1754 1754;
BA_ "SCP_FreshnessValueLength" BO_ 1754 64;
BA_ "SCP_FreshnessValueTxLength" BO_ 1754 8;
BA_ "SC_LinkPos" BO_ 1754 64;
BA_ "SC_Message" BO_ 1754 1;
BA_ "VFrameFormat" BO_ 1754 14;
BA_ "GenMsgCycleTime" BO_ 1755 2000;
BA_ "VFrameFormat" BO_ 1755 14;
BA_ "GenMsgSendType" BO_ 1756 8;
BA_ "VFrameFormat" BO_ 1756 14;
BA_ "GenMsgCycleTime" BO_ 1757 1000;
BA_ "VFrameFormat" BO_ 1757 14;
BA_ "E2EP01DataId" BO_ 1758 209;
BA_ "E2EP01DataLength" BO_ 1758 64;
BA_ "GenMsgCycleTime" BO_ 1758 1000;
BA_ "VFrameFormat" BO_ 1758 14;
BA_ "E2EP01DataId" BO_ 1759 210;
BA_ "E2EP01DataLength" BO_ 1759 64;
BA_ "GenMsgCycleTime" BO_ 1759 1000;
BA_ "VFrameFormat" BO_ 1759 14;
BA_ "GenMsgCycleTime" BO_ 1760 5000;
BA_ "VFrameFormat" BO_ 1760 14;
BA_ "GenMsgCycleTime" BO_ 1765 5000;
BA_ "VFrameFormat" BO_ 1765 14;
BA_ "GenMsgCycleTime" BO_ 1766 5000;
BA_ "VFrameFormat" BO_ 1766 14;
BA_ "GenMsgCycleTime" BO_ 1767 5000;
BA_ "VFrameFormat" BO_ 1767 14;
BA_ "GenMsgCycleTime" BO_ 1776 5000;
BA_ "VFrameFormat" BO_ 1776 14;
BA_ "GenMsgCycleTime" BO_ 1777 5000;
BA_ "VFrameFormat" BO_ 1777 14;
BA_ "GenMsgCycleTime" BO_ 1778 5000;
BA_ "VFrameFormat" BO_ 1778 14;
BA_ "GenMsgCycleTime" BO_ 1779 5000;
BA_ "VFrameFormat" BO_ 1779 14;
BA_ "GenMsgCycleTime" BO_ 1780 5000;
BA_ "VFrameFormat" BO_ 1780 14;
BA_ "GenMsgCycleTime" BO_ 1791 5000;
BA_ "VFrameFormat" BO_ 1791 14;
BA_ "GenMsgILSupport" BO_ 1796 0;
BA_ "GenMsgSendType" BO_ 1796 8;
BA_ "VFrameFormat" BO_ 1796 14;
BA_ "GenMsgILSupport" BO_ 1797 0;
BA_ "GenMsgSendType" BO_ 1797 8;
BA_ "VFrameFormat" BO_ 1797 14;
BA_ "GenMsgILSupport" BO_ 1798 0;
BA_ "GenMsgSendType" BO_ 1798 8;
BA_ "VFrameFormat" BO_ 1798 14;
BA_ "GenMsgILSupport" BO_ 1799 0;
BA_ "GenMsgSendType" BO_ 1799 8;
BA_ "VFrameFormat" BO_ 1799 14;
BA_ "GenMsgILSupport" BO_ 1800 0;
BA_ "GenMsgSendType" BO_ 1800 8;
BA_ "VFrameFormat" BO_ 1800 14;
BA_ "GenMsgILSupport" BO_ 1801 0;
BA_ "GenMsgSendType" BO_ 1801 8;
BA_ "VFrameFormat" BO_ 1801 14;
BA_ "GenMsgILSupport" BO_ 1802 0;
BA_ "GenMsgSendType" BO_ 1802 8;
BA_ "VFrameFormat" BO_ 1802 14;
BA_ "GenMsgILSupport" BO_ 1803 0;
BA_ "GenMsgSendType" BO_ 1803 8;
BA_ "VFrameFormat" BO_ 1803 14;
BA_ "GenMsgILSupport" BO_ 1804 0;
BA_ "GenMsgSendType" BO_ 1804 8;
BA_ "VFrameFormat" BO_ 1804 14;
BA_ "GenMsgILSupport" BO_ 1805 0;
BA_ "GenMsgSendType" BO_ 1805 8;
BA_ "VFrameFormat" BO_ 1805 14;
BA_ "GenMsgILSupport" BO_ 1806 0;
BA_ "GenMsgSendType" BO_ 1806 8;
BA_ "VFrameFormat" BO_ 1806 14;
BA_ "GenMsgILSupport" BO_ 1807 0;
BA_ "GenMsgSendType" BO_ 1807 8;
BA_ "VFrameFormat" BO_ 1807 14;
BA_ "GenMsgILSupport" BO_ 1808 0;
BA_ "GenMsgSendType" BO_ 1808 8;
BA_ "VFrameFormat" BO_ 1808 14;
BA_ "GenMsgILSupport" BO_ 1809 0;
BA_ "GenMsgSendType" BO_ 1809 8;
BA_ "VFrameFormat" BO_ 1809 14;
BA_ "GenMsgCycleTime" BO_ 1812 100;
BA_ "VFrameFormat" BO_ 1812 14;
BA_ "DiagConnection" BO_ 1874 8466;
BA_ "DiagFdOnly" BO_ 1874 1;
BA_ "DiagRequest" BO_ 1874 1;
BA_ "GenMsgILSupport" BO_ 1874 0;
BA_ "GenMsgSendType" BO_ 1874 8;
BA_ "VFrameFormat" BO_ 1874 14;
BA_ "DiagConnection" BO_ 1882 8466;
BA_ "DiagFdOnly" BO_ 1882 1;
BA_ "DiagResponse" BO_ 1882 1;
BA_ "GenMsgILSupport" BO_ 1882 0;
BA_ "GenMsgSendType" BO_ 1882 8;
BA_ "VFrameFormat" BO_ 1882 14;
BA_ "DiagConnection" BO_ 1937 8457;
BA_ "DiagFdOnly" BO_ 1937 1;
BA_ "DiagRequest" BO_ 1937 1;
BA_ "GenMsgILSupport" BO_ 1937 0;
BA_ "GenMsgSendType" BO_ 1937 8;
BA_ "VFrameFormat" BO_ 1937 14;
BA_ "DiagConnection" BO_ 1945 8457;
BA_ "DiagFdOnly" BO_ 1945 1;
BA_ "DiagResponse" BO_ 1945 1;
BA_ "GenMsgILSupport" BO_ 1945 0;
BA_ "GenMsgSendType" BO_ 1945 8;
BA_ "VFrameFormat" BO_ 1945 14;
BA_ "DiagConnection" BO_ 1986 8449;
BA_ "DiagFdOnly" BO_ 1986 1;
BA_ "DiagRequest" BO_ 1986 1;
BA_ "GenMsgILSupport" BO_ 1986 0;
BA_ "GenMsgSendType" BO_ 1986 8;
BA_ "VFrameFormat" BO_ 1986 14;
BA_ "DiagConnection" BO_ 1994 8449;
BA_ "DiagFdOnly" BO_ 1994 1;
BA_ "DiagResponse" BO_ 1994 1;
BA_ "GenMsgILSupport" BO_ 1994 0;
BA_ "GenMsgSendType" BO_ 1994 8;
BA_ "VFrameFormat" BO_ 1994 14;
BA_ "DiagConnection" BO_ 2005 8465;
BA_ "DiagFdOnly" BO_ 2005 1;
BA_ "DiagRequest" BO_ 2005 1;
BA_ "GenMsgILSupport" BO_ 2005 0;
BA_ "GenMsgSendType" BO_ 2005 8;
BA_ "VFrameFormat" BO_ 2005 14;
BA_ "DiagConnection" BO_ 2013 8465;
BA_ "DiagFdOnly" BO_ 2013 1;
BA_ "DiagResponse" BO_ 2013 1;
BA_ "GenMsgILSupport" BO_ 2013 0;
BA_ "GenMsgSendType" BO_ 2013 8;
BA_ "VFrameFormat" BO_ 2013 14;
BA_ "DiagConnection" BO_ 2015 8573;
BA_ "DiagFdOnly" BO_ 2015 1;
BA_ "DiagState" BO_ 2015 1;
BA_ "GenMsgILSupport" BO_ 2015 0;
BA_ "GenMsgSendType" BO_ 2015 8;
BA_ "VFrameFormat" BO_ 2015 14;
BA_ "DiagConnection" BO_ 2016 8449;
BA_ "DiagFdOnly" BO_ 2016 1;
BA_ "DiagRequest" BO_ 2016 1;
BA_ "GenMsgILSupport" BO_ 2016 0;
BA_ "GenMsgSendType" BO_ 2016 8;
BA_ "VFrameFormat" BO_ 2016 14;
BA_ "DiagConnection" BO_ 2017 8455;
BA_ "DiagFdOnly" BO_ 2017 1;
BA_ "DiagRequest" BO_ 2017 1;
BA_ "GenMsgILSupport" BO_ 2017 0;
BA_ "GenMsgSendType" BO_ 2017 8;
BA_ "VFrameFormat" BO_ 2017 14;
BA_ "DiagConnection" BO_ 2018 8464;
BA_ "DiagFdOnly" BO_ 2018 1;
BA_ "DiagRequest" BO_ 2018 1;
BA_ "GenMsgILSupport" BO_ 2018 0;
BA_ "GenMsgSendType" BO_ 2018 8;
BA_ "VFrameFormat" BO_ 2018 14;
BA_ "DiagConnection" BO_ 2024 8449;
BA_ "DiagFdOnly" BO_ 2024 1;
BA_ "DiagResponse" BO_ 2024 1;
BA_ "GenMsgILSupport" BO_ 2024 0;
BA_ "GenMsgSendType" BO_ 2024 8;
BA_ "VFrameFormat" BO_ 2024 14;
BA_ "DiagConnection" BO_ 2025 8455;
BA_ "DiagFdOnly" BO_ 2025 1;
BA_ "DiagResponse" BO_ 2025 1;
BA_ "GenMsgILSupport" BO_ 2025 0;
BA_ "GenMsgSendType" BO_ 2025 8;
BA_ "VFrameFormat" BO_ 2025 14;
BA_ "DiagConnection" BO_ 2026 8464;
BA_ "DiagFdOnly" BO_ 2026 1;
BA_ "DiagResponse" BO_ 2026 1;
BA_ "GenMsgILSupport" BO_ 2026 0;
BA_ "GenMsgSendType" BO_ 2026 8;
BA_ "VFrameFormat" BO_ 2026 14;
BA_ "DiagConnection" BO_ 2032 8467;
BA_ "DiagFdOnly" BO_ 2032 1;
BA_ "DiagRequest" BO_ 2032 1;
BA_ "GenMsgILSupport" BO_ 2032 0;
BA_ "GenMsgSendType" BO_ 2032 8;
BA_ "VFrameFormat" BO_ 2032 14;
BA_ "DiagConnection" BO_ 2035 8454;
BA_ "DiagFdOnly" BO_ 2035 1;
BA_ "DiagRequest" BO_ 2035 1;
BA_ "GenMsgILSupport" BO_ 2035 0;
BA_ "GenMsgSendType" BO_ 2035 8;
BA_ "VFrameFormat" BO_ 2035 14;
BA_ "DiagConnection" BO_ 2040 8467;
BA_ "DiagFdOnly" BO_ 2040 1;
BA_ "DiagResponse" BO_ 2040 1;
BA_ "GenMsgILSupport" BO_ 2040 0;
BA_ "GenMsgSendType" BO_ 2040 8;
BA_ "VFrameFormat" BO_ 2040 14;
BA_ "DiagConnection" BO_ 2043 8454;
BA_ "DiagFdOnly" BO_ 2043 1;
BA_ "DiagResponse" BO_ 2043 1;
BA_ "GenMsgILSupport" BO_ 2043 0;
BA_ "GenMsgSendType" BO_ 2043 8;
BA_ "VFrameFormat" BO_ 2043 14;
BA_ "sigConfig" SG_ 1619 OBC_SwVersS "null";
BA_ "sigExplanation" SG_ 1619 OBC_SwVersS "null";
BA_ "sigSecLevel" SG_ 1619 OBC_SwVersS "null";
BA_ "sigConfig" SG_ 1619 OBC_PartVers "null";
BA_ "sigExplanation" SG_ 1619 OBC_PartVers "null";
BA_ "sigSecLevel" SG_ 1619 OBC_PartVers "null";
BA_ "sigConfig" SG_ 1619 OBC_HwVers "null";
BA_ "sigExplanation" SG_ 1619 OBC_HwVers "null";
BA_ "sigSecLevel" SG_ 1619 OBC_HwVers "null";
BA_ "sigConfig" SG_ 1619 OBC_SwVersM "null";
BA_ "sigExplanation" SG_ 1619 OBC_SwVersM "null";
BA_ "sigSecLevel" SG_ 1619 OBC_SwVersM "null";
BA_ "sigConfig" SG_ 1636 ECC_SwVersS "null";
BA_ "sigExplanation" SG_ 1636 ECC_SwVersS "null";
BA_ "sigSecLevel" SG_ 1636 ECC_SwVersS "null";
BA_ "GenSigStartValue" SG_ 1636 ECC_PartVers 1;
BA_ "sigConfig" SG_ 1636 ECC_PartVers "null";
BA_ "sigExplanation" SG_ 1636 ECC_PartVers "null";
BA_ "sigSecLevel" SG_ 1636 ECC_PartVers "null";
BA_ "sigConfig" SG_ 1636 ECC_HwVers "null";
BA_ "sigExplanation" SG_ 1636 ECC_HwVers "null";
BA_ "sigSecLevel" SG_ 1636 ECC_HwVers "null";
BA_ "sigConfig" SG_ 1636 ECC_SwVersM "null";
BA_ "sigExplanation" SG_ 1636 ECC_SwVersM "null";
BA_ "sigSecLevel" SG_ 1636 ECC_SwVersM "null";
BA_ "sigConfig" SG_ 1637 WTC_H_SwVersS "null";
BA_ "sigExplanation" SG_ 1637 WTC_H_SwVersS "null";
BA_ "sigSecLevel" SG_ 1637 WTC_H_SwVersS "null";
BA_ "GenSigStartValue" SG_ 1637 WTC_H_PartVers 1;
BA_ "sigConfig" SG_ 1637 WTC_H_PartVers "null";
BA_ "sigExplanation" SG_ 1637 WTC_H_PartVers "null";
BA_ "sigSecLevel" SG_ 1637 WTC_H_PartVers "null";
BA_ "sigConfig" SG_ 1637 WTC_H_HwVers "null";
BA_ "sigExplanation" SG_ 1637 WTC_H_HwVers "null";
BA_ "sigSecLevel" SG_ 1637 WTC_H_HwVers "null";
BA_ "GenSigStartValue" SG_ 1637 WTC_H_SwVersM 51;
BA_ "sigConfig" SG_ 1637 WTC_H_SwVersM "null";
BA_ "sigExplanation" SG_ 1637 WTC_H_SwVersM "null";
BA_ "sigSecLevel" SG_ 1637 WTC_H_SwVersM "null";
BA_ "sigConfig" SG_ 1638 WTC_B_SwVersS "null";
BA_ "sigExplanation" SG_ 1638 WTC_B_SwVersS "null";
BA_ "sigSecLevel" SG_ 1638 WTC_B_SwVersS "null";
BA_ "GenSigStartValue" SG_ 1638 WTC_B_PartVers 1;
BA_ "sigConfig" SG_ 1638 WTC_B_PartVers "null";
BA_ "sigExplanation" SG_ 1638 WTC_B_PartVers "null";
BA_ "sigSecLevel" SG_ 1638 WTC_B_PartVers "null";
BA_ "sigConfig" SG_ 1638 WTC_B_HwVers "null";
BA_ "sigExplanation" SG_ 1638 WTC_B_HwVers "null";
BA_ "sigSecLevel" SG_ 1638 WTC_B_HwVers "null";
BA_ "GenSigStartValue" SG_ 1638 WTC_B_SwVersM 51;
BA_ "sigConfig" SG_ 1638 WTC_B_SwVersM "null";
BA_ "sigExplanation" SG_ 1638 WTC_B_SwVersM "null";
BA_ "sigSecLevel" SG_ 1638 WTC_B_SwVersM "null";
BA_ "sigConfig" SG_ 1695 EAS_SwVersS "null";
BA_ "sigExplanation" SG_ 1695 EAS_SwVersS "null";
BA_ "sigSecLevel" SG_ 1695 EAS_SwVersS "null";
BA_ "sigConfig" SG_ 1695 EAS_PartVers "null";
BA_ "sigExplanation" SG_ 1695 EAS_PartVers "null";
BA_ "sigSecLevel" SG_ 1695 EAS_PartVers "null";
BA_ "GenSigStartValue" SG_ 1695 EAS_HwVers 1;
BA_ "sigConfig" SG_ 1695 EAS_HwVers "null";
BA_ "sigExplanation" SG_ 1695 EAS_HwVers "null";
BA_ "sigSecLevel" SG_ 1695 EAS_HwVers "null";
BA_ "GenSigStartValue" SG_ 1695 EAS_SwVersM 51;
BA_ "sigConfig" SG_ 1695 EAS_SwVersM "null";
BA_ "sigExplanation" SG_ 1695 EAS_SwVersM "null";
BA_ "sigSecLevel" SG_ 1695 EAS_SwVersM "null";
BA_ "sigConfig" SG_ 1696 BMS_mxCounterActEnergy "null";
BA_ "sigExplanation" SG_ 1696 BMS_mxCounterActEnergy "null";
BA_ "sigSecLevel" SG_ 1696 BMS_mxCounterActEnergy "null";
BA_ "sigConfig" SG_ 1696 BMS_mxEnergyActValue1 "null";
BA_ "sigExplanation" SG_ 1696 BMS_mxEnergyActValue1 "null";
BA_ "sigSecLevel" SG_ 1696 BMS_mxEnergyActValue1 "null";
BA_ "sigConfig" SG_ 1696 BMS_mxEnergyActValue2 "null";
BA_ "sigExplanation" SG_ 1696 BMS_mxEnergyActValue2 "null";
BA_ "sigSecLevel" SG_ 1696 BMS_mxEnergyActValue2 "null";
BA_ "sigConfig" SG_ 1696 DCDC_ActTemp "null";
BA_ "sigExplanation" SG_ 1696 DCDC_ActTemp "null";
BA_ "sigSecLevel" SG_ 1696 DCDC_ActTemp "null";
BA_ "sigConfig" SG_ 1697 BMS_AccueChrgTotAh "null";
BA_ "sigExplanation" SG_ 1697 BMS_AccueChrgTotAh "null";
BA_ "sigSecLevel" SG_ 1697 BMS_AccueChrgTotAh "null";
BA_ "sigConfig" SG_ 1697 BMS_AccueDchaTotAh "null";
BA_ "sigExplanation" SG_ 1697 BMS_AccueDchaTotAh "null";
BA_ "sigSecLevel" SG_ 1697 BMS_AccueDchaTotAh "null";
BA_ "sigConfig" SG_ 1698 VCU_SCChrgCnt "null";
BA_ "sigExplanation" SG_ 1698 VCU_SCChrgCnt "null";
BA_ "sigSecLevel" SG_ 1698 VCU_SCChrgCnt "null";
BA_ "sigConfig" SG_ 1698 VCU_VehHVPwrOffTi "null";
BA_ "sigExplanation" SG_ 1698 VCU_VehHVPwrOffTi "null";
BA_ "sigSecLevel" SG_ 1698 VCU_VehHVPwrOffTi "null";
BA_ "sigConfig" SG_ 1698 VCU_FCChrgCnt "null";
BA_ "sigExplanation" SG_ 1698 VCU_FCChrgCnt "null";
BA_ "sigSecLevel" SG_ 1698 VCU_FCChrgCnt "null";
BA_ "sigConfig" SG_ 1701 BMS_CellMaxTOffset "null";
BA_ "sigExplanation" SG_ 1701 BMS_CellMaxTOffset "null";
BA_ "sigSecLevel" SG_ 1701 BMS_CellMaxTOffset "null";
BA_ "sigConfig" SG_ 1701 BMS_CellMinTOffset "null";
BA_ "sigExplanation" SG_ 1701 BMS_CellMinTOffset "null";
BA_ "sigSecLevel" SG_ 1701 BMS_CellMinTOffset "null";
BA_ "sigConfig" SG_ 1701 BMS_MinTCod "null";
BA_ "sigExplanation" SG_ 1701 BMS_MinTCod "null";
BA_ "sigSecLevel" SG_ 1701 BMS_MinTCod "null";
BA_ "sigConfig" SG_ 1701 BMS_MinCellVoltCod "null";
BA_ "sigExplanation" SG_ 1701 BMS_MinCellVoltCod "null";
BA_ "sigSecLevel" SG_ 1701 BMS_MinCellVoltCod "null";
BA_ "sigConfig" SG_ 1701 BMS_MaxCellVoltPackNr "null";
BA_ "sigExplanation" SG_ 1701 BMS_MaxCellVoltPackNr "null";
BA_ "sigSecLevel" SG_ 1701 BMS_MaxCellVoltPackNr "null";
BA_ "sigConfig" SG_ 1701 BMS_MaxTPackNr "null";
BA_ "sigExplanation" SG_ 1701 BMS_MaxTPackNr "null";
BA_ "sigSecLevel" SG_ 1701 BMS_MaxTPackNr "null";
BA_ "sigConfig" SG_ 1701 BMS_MinTPackNr "null";
BA_ "sigExplanation" SG_ 1701 BMS_MinTPackNr "null";
BA_ "sigSecLevel" SG_ 1701 BMS_MinTPackNr "null";
BA_ "sigConfig" SG_ 1701 BMS_MinCellVoltPackNr "null";
BA_ "sigExplanation" SG_ 1701 BMS_MinCellVoltPackNr "null";
BA_ "sigSecLevel" SG_ 1701 BMS_MinCellVoltPackNr "null";
BA_ "sigConfig" SG_ 1701 BMS_MaxCellVoltCod "null";
BA_ "sigExplanation" SG_ 1701 BMS_MaxCellVoltCod "null";
BA_ "sigSecLevel" SG_ 1701 BMS_MaxCellVoltCod "null";
BA_ "sigConfig" SG_ 1701 BMS_MaxTCod "null";
BA_ "sigExplanation" SG_ 1701 BMS_MaxTCod "null";
BA_ "sigSecLevel" SG_ 1701 BMS_MaxTCod "null";
BA_ "sigConfig" SG_ 1712 BMS_CellVolt1 "null";
BA_ "sigExplanation" SG_ 1712 BMS_CellVolt1 "null";
BA_ "sigSecLevel" SG_ 1712 BMS_CellVolt1 "null";
BA_ "sigConfig" SG_ 1712 BMS_CellVolt2 "null";
BA_ "sigExplanation" SG_ 1712 BMS_CellVolt2 "null";
BA_ "sigSecLevel" SG_ 1712 BMS_CellVolt2 "null";
BA_ "sigConfig" SG_ 1712 BMS_CellVolt3 "null";
BA_ "sigExplanation" SG_ 1712 BMS_CellVolt3 "null";
BA_ "sigSecLevel" SG_ 1712 BMS_CellVolt3 "null";
BA_ "sigConfig" SG_ 1712 BMS_CellVolt4 "null";
BA_ "sigExplanation" SG_ 1712 BMS_CellVolt4 "null";
BA_ "sigSecLevel" SG_ 1712 BMS_CellVolt4 "null";
BA_ "sigConfig" SG_ 1713 BMS_CellVolt5 "null";
BA_ "sigExplanation" SG_ 1713 BMS_CellVolt5 "null";
BA_ "sigSecLevel" SG_ 1713 BMS_CellVolt5 "null";
BA_ "sigConfig" SG_ 1713 BMS_CellVolt6 "null";
BA_ "sigExplanation" SG_ 1713 BMS_CellVolt6 "null";
BA_ "sigSecLevel" SG_ 1713 BMS_CellVolt6 "null";
BA_ "sigConfig" SG_ 1713 BMS_CellVolt7 "null";
BA_ "sigExplanation" SG_ 1713 BMS_CellVolt7 "null";
BA_ "sigSecLevel" SG_ 1713 BMS_CellVolt7 "null";
BA_ "sigConfig" SG_ 1713 BMS_CellVolt8 "null";
BA_ "sigExplanation" SG_ 1713 BMS_CellVolt8 "null";
BA_ "sigSecLevel" SG_ 1713 BMS_CellVolt8 "null";
BA_ "sigConfig" SG_ 1714 BMS_CellVolt9 "null";
BA_ "sigExplanation" SG_ 1714 BMS_CellVolt9 "null";
BA_ "sigSecLevel" SG_ 1714 BMS_CellVolt9 "null";
BA_ "sigConfig" SG_ 1714 BMS_CellVolt10 "null";
BA_ "sigExplanation" SG_ 1714 BMS_CellVolt10 "null";
BA_ "sigSecLevel" SG_ 1714 BMS_CellVolt10 "null";
BA_ "sigConfig" SG_ 1714 BMS_CellVolt11 "null";
BA_ "sigExplanation" SG_ 1714 BMS_CellVolt11 "null";
BA_ "sigSecLevel" SG_ 1714 BMS_CellVolt11 "null";
BA_ "sigConfig" SG_ 1714 BMS_CellVolt12 "null";
BA_ "sigExplanation" SG_ 1714 BMS_CellVolt12 "null";
BA_ "sigSecLevel" SG_ 1714 BMS_CellVolt12 "null";
BA_ "sigConfig" SG_ 1715 BMS_CellVolt13 "null";
BA_ "sigExplanation" SG_ 1715 BMS_CellVolt13 "null";
BA_ "sigSecLevel" SG_ 1715 BMS_CellVolt13 "null";
BA_ "sigConfig" SG_ 1715 BMS_CellVolt14 "null";
BA_ "sigExplanation" SG_ 1715 BMS_CellVolt14 "null";
BA_ "sigSecLevel" SG_ 1715 BMS_CellVolt14 "null";
BA_ "sigConfig" SG_ 1715 BMS_CellVolt15 "null";
BA_ "sigExplanation" SG_ 1715 BMS_CellVolt15 "null";
BA_ "sigSecLevel" SG_ 1715 BMS_CellVolt15 "null";
BA_ "sigConfig" SG_ 1715 BMS_CellVolt16 "null";
BA_ "sigExplanation" SG_ 1715 BMS_CellVolt16 "null";
BA_ "sigSecLevel" SG_ 1715 BMS_CellVolt16 "null";
BA_ "sigConfig" SG_ 1716 BMS_CellVolt17 "null";
BA_ "sigExplanation" SG_ 1716 BMS_CellVolt17 "null";
BA_ "sigSecLevel" SG_ 1716 BMS_CellVolt17 "null";
BA_ "sigConfig" SG_ 1716 BMS_CellVolt18 "null";
BA_ "sigExplanation" SG_ 1716 BMS_CellVolt18 "null";
BA_ "sigSecLevel" SG_ 1716 BMS_CellVolt18 "null";
BA_ "sigConfig" SG_ 1716 BMS_CellVolt19 "null";
BA_ "sigExplanation" SG_ 1716 BMS_CellVolt19 "null";
BA_ "sigSecLevel" SG_ 1716 BMS_CellVolt19 "null";
BA_ "sigConfig" SG_ 1716 BMS_CellVolt20 "null";
BA_ "sigExplanation" SG_ 1716 BMS_CellVolt20 "null";
BA_ "sigSecLevel" SG_ 1716 BMS_CellVolt20 "null";
BA_ "sigConfig" SG_ 1717 BMS_CellVolt21 "null";
BA_ "sigExplanation" SG_ 1717 BMS_CellVolt21 "null";
BA_ "sigSecLevel" SG_ 1717 BMS_CellVolt21 "null";
BA_ "sigConfig" SG_ 1717 BMS_CellVolt22 "null";
BA_ "sigExplanation" SG_ 1717 BMS_CellVolt22 "null";
BA_ "sigSecLevel" SG_ 1717 BMS_CellVolt22 "null";
BA_ "sigConfig" SG_ 1717 BMS_CellVolt23 "null";
BA_ "sigExplanation" SG_ 1717 BMS_CellVolt23 "null";
BA_ "sigSecLevel" SG_ 1717 BMS_CellVolt23 "null";
BA_ "sigConfig" SG_ 1717 BMS_CellVolt24 "null";
BA_ "sigExplanation" SG_ 1717 BMS_CellVolt24 "null";
BA_ "sigSecLevel" SG_ 1717 BMS_CellVolt24 "null";
BA_ "sigConfig" SG_ 1718 BMS_CellVolt25 "null";
BA_ "sigExplanation" SG_ 1718 BMS_CellVolt25 "null";
BA_ "sigSecLevel" SG_ 1718 BMS_CellVolt25 "null";
BA_ "sigConfig" SG_ 1718 BMS_CellVolt26 "null";
BA_ "sigExplanation" SG_ 1718 BMS_CellVolt26 "null";
BA_ "sigSecLevel" SG_ 1718 BMS_CellVolt26 "null";
BA_ "sigConfig" SG_ 1718 BMS_CellVolt27 "null";
BA_ "sigExplanation" SG_ 1718 BMS_CellVolt27 "null";
BA_ "sigSecLevel" SG_ 1718 BMS_CellVolt27 "null";
BA_ "sigConfig" SG_ 1718 BMS_CellVolt28 "null";
BA_ "sigExplanation" SG_ 1718 BMS_CellVolt28 "null";
BA_ "sigSecLevel" SG_ 1718 BMS_CellVolt28 "null";
BA_ "sigConfig" SG_ 1719 BMS_CellVolt29 "null";
BA_ "sigExplanation" SG_ 1719 BMS_CellVolt29 "null";
BA_ "sigSecLevel" SG_ 1719 BMS_CellVolt29 "null";
BA_ "sigConfig" SG_ 1719 BMS_CellVolt30 "null";
BA_ "sigExplanation" SG_ 1719 BMS_CellVolt30 "null";
BA_ "sigSecLevel" SG_ 1719 BMS_CellVolt30 "null";
BA_ "sigConfig" SG_ 1719 BMS_CellVolt31 "null";
BA_ "sigExplanation" SG_ 1719 BMS_CellVolt31 "null";
BA_ "sigSecLevel" SG_ 1719 BMS_CellVolt31 "null";
BA_ "sigConfig" SG_ 1719 BMS_CellVolt32 "null";
BA_ "sigExplanation" SG_ 1719 BMS_CellVolt32 "null";
BA_ "sigSecLevel" SG_ 1719 BMS_CellVolt32 "null";
BA_ "sigConfig" SG_ 1720 BMS_CellVolt33 "null";
BA_ "sigExplanation" SG_ 1720 BMS_CellVolt33 "null";
BA_ "sigSecLevel" SG_ 1720 BMS_CellVolt33 "null";
BA_ "sigConfig" SG_ 1720 BMS_CellVolt34 "null";
BA_ "sigExplanation" SG_ 1720 BMS_CellVolt34 "null";
BA_ "sigSecLevel" SG_ 1720 BMS_CellVolt34 "null";
BA_ "sigConfig" SG_ 1720 BMS_CellVolt35 "null";
BA_ "sigExplanation" SG_ 1720 BMS_CellVolt35 "null";
BA_ "sigSecLevel" SG_ 1720 BMS_CellVolt35 "null";
BA_ "sigConfig" SG_ 1720 BMS_CellVolt36 "null";
BA_ "sigExplanation" SG_ 1720 BMS_CellVolt36 "null";
BA_ "sigSecLevel" SG_ 1720 BMS_CellVolt36 "null";
BA_ "sigConfig" SG_ 1721 BMS_CellVolt37 "null";
BA_ "sigExplanation" SG_ 1721 BMS_CellVolt37 "null";
BA_ "sigSecLevel" SG_ 1721 BMS_CellVolt37 "null";
BA_ "sigConfig" SG_ 1721 BMS_CellVolt38 "null";
BA_ "sigExplanation" SG_ 1721 BMS_CellVolt38 "null";
BA_ "sigSecLevel" SG_ 1721 BMS_CellVolt38 "null";
BA_ "sigConfig" SG_ 1721 BMS_CellVolt39 "null";
BA_ "sigExplanation" SG_ 1721 BMS_CellVolt39 "null";
BA_ "sigSecLevel" SG_ 1721 BMS_CellVolt39 "null";
BA_ "sigConfig" SG_ 1721 BMS_CellVolt40 "null";
BA_ "sigExplanation" SG_ 1721 BMS_CellVolt40 "null";
BA_ "sigSecLevel" SG_ 1721 BMS_CellVolt40 "null";
BA_ "sigConfig" SG_ 1722 BMS_CellVolt41 "null";
BA_ "sigExplanation" SG_ 1722 BMS_CellVolt41 "null";
BA_ "sigSecLevel" SG_ 1722 BMS_CellVolt41 "null";
BA_ "sigConfig" SG_ 1722 BMS_CellVolt42 "null";
BA_ "sigExplanation" SG_ 1722 BMS_CellVolt42 "null";
BA_ "sigSecLevel" SG_ 1722 BMS_CellVolt42 "null";
BA_ "sigConfig" SG_ 1722 BMS_CellVolt43 "null";
BA_ "sigExplanation" SG_ 1722 BMS_CellVolt43 "null";
BA_ "sigSecLevel" SG_ 1722 BMS_CellVolt43 "null";
BA_ "sigConfig" SG_ 1722 BMS_CellVolt44 "null";
BA_ "sigExplanation" SG_ 1722 BMS_CellVolt44 "null";
BA_ "sigSecLevel" SG_ 1722 BMS_CellVolt44 "null";
BA_ "sigConfig" SG_ 1723 BMS_CellVolt45 "null";
BA_ "sigExplanation" SG_ 1723 BMS_CellVolt45 "null";
BA_ "sigSecLevel" SG_ 1723 BMS_CellVolt45 "null";
BA_ "sigConfig" SG_ 1723 BMS_CellVolt46 "null";
BA_ "sigExplanation" SG_ 1723 BMS_CellVolt46 "null";
BA_ "sigSecLevel" SG_ 1723 BMS_CellVolt46 "null";
BA_ "sigConfig" SG_ 1723 BMS_CellVolt47 "null";
BA_ "sigExplanation" SG_ 1723 BMS_CellVolt47 "null";
BA_ "sigSecLevel" SG_ 1723 BMS_CellVolt47 "null";
BA_ "sigConfig" SG_ 1723 BMS_CellVolt48 "null";
BA_ "sigExplanation" SG_ 1723 BMS_CellVolt48 "null";
BA_ "sigSecLevel" SG_ 1723 BMS_CellVolt48 "null";
BA_ "sigConfig" SG_ 1724 BMS_CellVolt49 "null";
BA_ "sigExplanation" SG_ 1724 BMS_CellVolt49 "null";
BA_ "sigSecLevel" SG_ 1724 BMS_CellVolt49 "null";
BA_ "sigConfig" SG_ 1724 BMS_CellVolt50 "null";
BA_ "sigExplanation" SG_ 1724 BMS_CellVolt50 "null";
BA_ "sigSecLevel" SG_ 1724 BMS_CellVolt50 "null";
BA_ "sigConfig" SG_ 1724 BMS_CellVolt51 "null";
BA_ "sigExplanation" SG_ 1724 BMS_CellVolt51 "null";
BA_ "sigSecLevel" SG_ 1724 BMS_CellVolt51 "null";
BA_ "sigConfig" SG_ 1724 BMS_CellVolt52 "null";
BA_ "sigExplanation" SG_ 1724 BMS_CellVolt52 "null";
BA_ "sigSecLevel" SG_ 1724 BMS_CellVolt52 "null";
BA_ "sigConfig" SG_ 1725 BMS_CellVolt53 "null";
BA_ "sigExplanation" SG_ 1725 BMS_CellVolt53 "null";
BA_ "sigSecLevel" SG_ 1725 BMS_CellVolt53 "null";
BA_ "sigConfig" SG_ 1725 BMS_CellVolt54 "null";
BA_ "sigExplanation" SG_ 1725 BMS_CellVolt54 "null";
BA_ "sigSecLevel" SG_ 1725 BMS_CellVolt54 "null";
BA_ "sigConfig" SG_ 1725 BMS_CellVolt55 "null";
BA_ "sigExplanation" SG_ 1725 BMS_CellVolt55 "null";
BA_ "sigSecLevel" SG_ 1725 BMS_CellVolt55 "null";
BA_ "sigConfig" SG_ 1725 BMS_CellVolt56 "null";
BA_ "sigExplanation" SG_ 1725 BMS_CellVolt56 "null";
BA_ "sigSecLevel" SG_ 1725 BMS_CellVolt56 "null";
BA_ "sigConfig" SG_ 1726 BMS_CellVolt57 "null";
BA_ "sigExplanation" SG_ 1726 BMS_CellVolt57 "null";
BA_ "sigSecLevel" SG_ 1726 BMS_CellVolt57 "null";
BA_ "sigConfig" SG_ 1726 BMS_CellVolt58 "null";
BA_ "sigExplanation" SG_ 1726 BMS_CellVolt58 "null";
BA_ "sigSecLevel" SG_ 1726 BMS_CellVolt58 "null";
BA_ "sigConfig" SG_ 1726 BMS_CellVolt59 "null";
BA_ "sigExplanation" SG_ 1726 BMS_CellVolt59 "null";
BA_ "sigSecLevel" SG_ 1726 BMS_CellVolt59 "null";
BA_ "sigConfig" SG_ 1726 BMS_CellVolt60 "null";
BA_ "sigExplanation" SG_ 1726 BMS_CellVolt60 "null";
BA_ "sigSecLevel" SG_ 1726 BMS_CellVolt60 "null";
BA_ "sigConfig" SG_ 1727 BMS_CellVolt61 "null";
BA_ "sigExplanation" SG_ 1727 BMS_CellVolt61 "null";
BA_ "sigSecLevel" SG_ 1727 BMS_CellVolt61 "null";
BA_ "sigConfig" SG_ 1727 BMS_CellVolt62 "null";
BA_ "sigExplanation" SG_ 1727 BMS_CellVolt62 "null";
BA_ "sigSecLevel" SG_ 1727 BMS_CellVolt62 "null";
BA_ "sigConfig" SG_ 1727 BMS_CellVolt63 "null";
BA_ "sigExplanation" SG_ 1727 BMS_CellVolt63 "null";
BA_ "sigSecLevel" SG_ 1727 BMS_CellVolt63 "null";
BA_ "sigConfig" SG_ 1727 BMS_CellVolt64 "null";
BA_ "sigExplanation" SG_ 1727 BMS_CellVolt64 "null";
BA_ "sigSecLevel" SG_ 1727 BMS_CellVolt64 "null";
BA_ "sigConfig" SG_ 1728 BMS_CellVolt65 "null";
BA_ "sigExplanation" SG_ 1728 BMS_CellVolt65 "null";
BA_ "sigSecLevel" SG_ 1728 BMS_CellVolt65 "null";
BA_ "sigConfig" SG_ 1728 BMS_CellVolt66 "null";
BA_ "sigExplanation" SG_ 1728 BMS_CellVolt66 "null";
BA_ "sigSecLevel" SG_ 1728 BMS_CellVolt66 "null";
BA_ "sigConfig" SG_ 1728 BMS_CellVolt67 "null";
BA_ "sigExplanation" SG_ 1728 BMS_CellVolt67 "null";
BA_ "sigSecLevel" SG_ 1728 BMS_CellVolt67 "null";
BA_ "sigConfig" SG_ 1728 BMS_CellVolt68 "null";
BA_ "sigExplanation" SG_ 1728 BMS_CellVolt68 "null";
BA_ "sigSecLevel" SG_ 1728 BMS_CellVolt68 "null";
BA_ "sigConfig" SG_ 1729 BMS_CellVolt69 "null";
BA_ "sigExplanation" SG_ 1729 BMS_CellVolt69 "null";
BA_ "sigSecLevel" SG_ 1729 BMS_CellVolt69 "null";
BA_ "sigConfig" SG_ 1729 BMS_CellVolt70 "null";
BA_ "sigExplanation" SG_ 1729 BMS_CellVolt70 "null";
BA_ "sigSecLevel" SG_ 1729 BMS_CellVolt70 "null";
BA_ "sigConfig" SG_ 1729 BMS_CellVolt71 "null";
BA_ "sigExplanation" SG_ 1729 BMS_CellVolt71 "null";
BA_ "sigSecLevel" SG_ 1729 BMS_CellVolt71 "null";
BA_ "sigConfig" SG_ 1729 BMS_CellVolt72 "null";
BA_ "sigExplanation" SG_ 1729 BMS_CellVolt72 "null";
BA_ "sigSecLevel" SG_ 1729 BMS_CellVolt72 "null";
BA_ "sigConfig" SG_ 1730 BMS_CellVolt73 "null";
BA_ "sigExplanation" SG_ 1730 BMS_CellVolt73 "null";
BA_ "sigSecLevel" SG_ 1730 BMS_CellVolt73 "null";
BA_ "sigConfig" SG_ 1730 BMS_CellVolt74 "null";
BA_ "sigExplanation" SG_ 1730 BMS_CellVolt74 "null";
BA_ "sigSecLevel" SG_ 1730 BMS_CellVolt74 "null";
BA_ "sigConfig" SG_ 1730 BMS_CellVolt75 "null";
BA_ "sigExplanation" SG_ 1730 BMS_CellVolt75 "null";
BA_ "sigSecLevel" SG_ 1730 BMS_CellVolt75 "null";
BA_ "sigConfig" SG_ 1730 BMS_CellVolt76 "null";
BA_ "sigExplanation" SG_ 1730 BMS_CellVolt76 "null";
BA_ "sigSecLevel" SG_ 1730 BMS_CellVolt76 "null";
BA_ "sigConfig" SG_ 1731 BMS_CellVolt77 "null";
BA_ "sigExplanation" SG_ 1731 BMS_CellVolt77 "null";
BA_ "sigSecLevel" SG_ 1731 BMS_CellVolt77 "null";
BA_ "sigConfig" SG_ 1731 BMS_CellVolt78 "null";
BA_ "sigExplanation" SG_ 1731 BMS_CellVolt78 "null";
BA_ "sigSecLevel" SG_ 1731 BMS_CellVolt78 "null";
BA_ "sigConfig" SG_ 1731 BMS_CellVolt79 "null";
BA_ "sigExplanation" SG_ 1731 BMS_CellVolt79 "null";
BA_ "sigSecLevel" SG_ 1731 BMS_CellVolt79 "null";
BA_ "sigConfig" SG_ 1731 BMS_CellVolt80 "null";
BA_ "sigExplanation" SG_ 1731 BMS_CellVolt80 "null";
BA_ "sigSecLevel" SG_ 1731 BMS_CellVolt80 "null";
BA_ "sigConfig" SG_ 1732 BMS_CellVolt81 "null";
BA_ "sigExplanation" SG_ 1732 BMS_CellVolt81 "null";
BA_ "sigSecLevel" SG_ 1732 BMS_CellVolt81 "null";
BA_ "sigConfig" SG_ 1732 BMS_CellVolt82 "null";
BA_ "sigExplanation" SG_ 1732 BMS_CellVolt82 "null";
BA_ "sigSecLevel" SG_ 1732 BMS_CellVolt82 "null";
BA_ "sigConfig" SG_ 1732 BMS_CellVolt83 "null";
BA_ "sigExplanation" SG_ 1732 BMS_CellVolt83 "null";
BA_ "sigSecLevel" SG_ 1732 BMS_CellVolt83 "null";
BA_ "sigConfig" SG_ 1732 BMS_CellVolt84 "null";
BA_ "sigExplanation" SG_ 1732 BMS_CellVolt84 "null";
BA_ "sigSecLevel" SG_ 1732 BMS_CellVolt84 "null";
BA_ "sigConfig" SG_ 1733 BMS_CellVolt85 "null";
BA_ "sigExplanation" SG_ 1733 BMS_CellVolt85 "null";
BA_ "sigSecLevel" SG_ 1733 BMS_CellVolt85 "null";
BA_ "sigConfig" SG_ 1733 BMS_CellVolt86 "null";
BA_ "sigExplanation" SG_ 1733 BMS_CellVolt86 "null";
BA_ "sigSecLevel" SG_ 1733 BMS_CellVolt86 "null";
BA_ "sigConfig" SG_ 1733 BMS_CellVolt87 "null";
BA_ "sigExplanation" SG_ 1733 BMS_CellVolt87 "null";
BA_ "sigSecLevel" SG_ 1733 BMS_CellVolt87 "null";
BA_ "sigConfig" SG_ 1733 BMS_CellVolt88 "null";
BA_ "sigExplanation" SG_ 1733 BMS_CellVolt88 "null";
BA_ "sigSecLevel" SG_ 1733 BMS_CellVolt88 "null";
BA_ "sigConfig" SG_ 1734 BMS_CellVolt89 "null";
BA_ "sigExplanation" SG_ 1734 BMS_CellVolt89 "null";
BA_ "sigSecLevel" SG_ 1734 BMS_CellVolt89 "null";
BA_ "sigConfig" SG_ 1734 BMS_CellVolt90 "null";
BA_ "sigExplanation" SG_ 1734 BMS_CellVolt90 "null";
BA_ "sigSecLevel" SG_ 1734 BMS_CellVolt90 "null";
BA_ "sigConfig" SG_ 1734 BMS_CellVolt91 "null";
BA_ "sigExplanation" SG_ 1734 BMS_CellVolt91 "null";
BA_ "sigSecLevel" SG_ 1734 BMS_CellVolt91 "null";
BA_ "sigConfig" SG_ 1734 BMS_CellVolt92 "null";
BA_ "sigExplanation" SG_ 1734 BMS_CellVolt92 "null";
BA_ "sigSecLevel" SG_ 1734 BMS_CellVolt92 "null";
BA_ "sigConfig" SG_ 1735 BMS_CellVolt93 "null";
BA_ "sigExplanation" SG_ 1735 BMS_CellVolt93 "null";
BA_ "sigSecLevel" SG_ 1735 BMS_CellVolt93 "null";
BA_ "sigConfig" SG_ 1735 BMS_CellVolt94 "null";
BA_ "sigExplanation" SG_ 1735 BMS_CellVolt94 "null";
BA_ "sigSecLevel" SG_ 1735 BMS_CellVolt94 "null";
BA_ "sigConfig" SG_ 1735 BMS_CellVolt95 "null";
BA_ "sigExplanation" SG_ 1735 BMS_CellVolt95 "null";
BA_ "sigSecLevel" SG_ 1735 BMS_CellVolt95 "null";
BA_ "sigConfig" SG_ 1735 BMS_CellVolt96 "null";
BA_ "sigExplanation" SG_ 1735 BMS_CellVolt96 "null";
BA_ "sigSecLevel" SG_ 1735 BMS_CellVolt96 "null";
BA_ "sigConfig" SG_ 1736 BMS_CellVolt97 "null";
BA_ "sigExplanation" SG_ 1736 BMS_CellVolt97 "null";
BA_ "sigSecLevel" SG_ 1736 BMS_CellVolt97 "null";
BA_ "sigConfig" SG_ 1736 BMS_CellVolt98 "null";
BA_ "sigExplanation" SG_ 1736 BMS_CellVolt98 "null";
BA_ "sigSecLevel" SG_ 1736 BMS_CellVolt98 "null";
BA_ "sigConfig" SG_ 1736 BMS_CellVolt99 "null";
BA_ "sigExplanation" SG_ 1736 BMS_CellVolt99 "null";
BA_ "sigSecLevel" SG_ 1736 BMS_CellVolt99 "null";
BA_ "sigConfig" SG_ 1736 BMS_CellVolt100 "null";
BA_ "sigExplanation" SG_ 1736 BMS_CellVolt100 "null";
BA_ "sigSecLevel" SG_ 1736 BMS_CellVolt100 "null";
BA_ "sigConfig" SG_ 1737 BMS_CellVolt101 "null";
BA_ "sigExplanation" SG_ 1737 BMS_CellVolt101 "null";
BA_ "sigSecLevel" SG_ 1737 BMS_CellVolt101 "null";
BA_ "sigConfig" SG_ 1737 BMS_CellVolt102 "null";
BA_ "sigExplanation" SG_ 1737 BMS_CellVolt102 "null";
BA_ "sigSecLevel" SG_ 1737 BMS_CellVolt102 "null";
BA_ "sigConfig" SG_ 1737 BMS_CellVolt103 "null";
BA_ "sigExplanation" SG_ 1737 BMS_CellVolt103 "null";
BA_ "sigSecLevel" SG_ 1737 BMS_CellVolt103 "null";
BA_ "sigConfig" SG_ 1737 BMS_CellVolt104 "null";
BA_ "sigExplanation" SG_ 1737 BMS_CellVolt104 "null";
BA_ "sigSecLevel" SG_ 1737 BMS_CellVolt104 "null";
BA_ "sigConfig" SG_ 1738 BMS_CellVolt105 "null";
BA_ "sigExplanation" SG_ 1738 BMS_CellVolt105 "null";
BA_ "sigSecLevel" SG_ 1738 BMS_CellVolt105 "null";
BA_ "sigConfig" SG_ 1738 BMS_CellVolt106 "null";
BA_ "sigExplanation" SG_ 1738 BMS_CellVolt106 "null";
BA_ "sigSecLevel" SG_ 1738 BMS_CellVolt106 "null";
BA_ "sigConfig" SG_ 1738 BMS_CellVolt107 "null";
BA_ "sigExplanation" SG_ 1738 BMS_CellVolt107 "null";
BA_ "sigSecLevel" SG_ 1738 BMS_CellVolt107 "null";
BA_ "sigConfig" SG_ 1738 BMS_CellVolt108 "null";
BA_ "sigExplanation" SG_ 1738 BMS_CellVolt108 "null";
BA_ "sigSecLevel" SG_ 1738 BMS_CellVolt108 "null";
BA_ "sigConfig" SG_ 1739 BMS_CellVolt109 "null";
BA_ "sigExplanation" SG_ 1739 BMS_CellVolt109 "null";
BA_ "sigSecLevel" SG_ 1739 BMS_CellVolt109 "null";
BA_ "sigConfig" SG_ 1739 BMS_CellVolt110 "null";
BA_ "sigExplanation" SG_ 1739 BMS_CellVolt110 "null";
BA_ "sigSecLevel" SG_ 1739 BMS_CellVolt110 "null";
BA_ "sigConfig" SG_ 1739 BMS_CellVolt111 "null";
BA_ "sigExplanation" SG_ 1739 BMS_CellVolt111 "null";
BA_ "sigSecLevel" SG_ 1739 BMS_CellVolt111 "null";
BA_ "sigConfig" SG_ 1739 BMS_CellVolt112 "null";
BA_ "sigExplanation" SG_ 1739 BMS_CellVolt112 "null";
BA_ "sigSecLevel" SG_ 1739 BMS_CellVolt112 "null";
BA_ "sigConfig" SG_ 1740 BMS_CellVolt113 "null";
BA_ "sigExplanation" SG_ 1740 BMS_CellVolt113 "null";
BA_ "sigSecLevel" SG_ 1740 BMS_CellVolt113 "null";
BA_ "sigConfig" SG_ 1740 BMS_CellVolt114 "null";
BA_ "sigExplanation" SG_ 1740 BMS_CellVolt114 "null";
BA_ "sigSecLevel" SG_ 1740 BMS_CellVolt114 "null";
BA_ "sigConfig" SG_ 1740 BMS_CellVolt115 "null";
BA_ "sigExplanation" SG_ 1740 BMS_CellVolt115 "null";
BA_ "sigSecLevel" SG_ 1740 BMS_CellVolt115 "null";
BA_ "sigConfig" SG_ 1740 BMS_CellVolt116 "null";
BA_ "sigExplanation" SG_ 1740 BMS_CellVolt116 "null";
BA_ "sigSecLevel" SG_ 1740 BMS_CellVolt116 "null";
BA_ "sigConfig" SG_ 1741 BMS_CellVolt117 "null";
BA_ "sigExplanation" SG_ 1741 BMS_CellVolt117 "null";
BA_ "sigSecLevel" SG_ 1741 BMS_CellVolt117 "null";
BA_ "sigConfig" SG_ 1741 BMS_CellVolt118 "null";
BA_ "sigExplanation" SG_ 1741 BMS_CellVolt118 "null";
BA_ "sigSecLevel" SG_ 1741 BMS_CellVolt118 "null";
BA_ "sigConfig" SG_ 1741 BMS_CellVolt119 "null";
BA_ "sigExplanation" SG_ 1741 BMS_CellVolt119 "null";
BA_ "sigSecLevel" SG_ 1741 BMS_CellVolt119 "null";
BA_ "sigConfig" SG_ 1741 BMS_CellVolt120 "null";
BA_ "sigExplanation" SG_ 1741 BMS_CellVolt120 "null";
BA_ "sigSecLevel" SG_ 1741 BMS_CellVolt120 "null";
BA_ "GenSigStartValue" SG_ 1744 BMS_CellT1 48;
BA_ "sigConfig" SG_ 1744 BMS_CellT1 "null";
BA_ "sigExplanation" SG_ 1744 BMS_CellT1 "null";
BA_ "sigSecLevel" SG_ 1744 BMS_CellT1 "null";
BA_ "GenSigStartValue" SG_ 1744 BMS_CellT2 48;
BA_ "sigConfig" SG_ 1744 BMS_CellT2 "null";
BA_ "sigExplanation" SG_ 1744 BMS_CellT2 "null";
BA_ "sigSecLevel" SG_ 1744 BMS_CellT2 "null";
BA_ "GenSigStartValue" SG_ 1744 BMS_CellT3 48;
BA_ "sigConfig" SG_ 1744 BMS_CellT3 "null";
BA_ "sigExplanation" SG_ 1744 BMS_CellT3 "null";
BA_ "sigSecLevel" SG_ 1744 BMS_CellT3 "null";
BA_ "GenSigStartValue" SG_ 1744 BMS_CellT4 48;
BA_ "sigConfig" SG_ 1744 BMS_CellT4 "null";
BA_ "sigExplanation" SG_ 1744 BMS_CellT4 "null";
BA_ "sigSecLevel" SG_ 1744 BMS_CellT4 "null";
BA_ "GenSigStartValue" SG_ 1744 BMS_CellT5 48;
BA_ "sigConfig" SG_ 1744 BMS_CellT5 "null";
BA_ "sigExplanation" SG_ 1744 BMS_CellT5 "null";
BA_ "sigSecLevel" SG_ 1744 BMS_CellT5 "null";
BA_ "GenSigStartValue" SG_ 1744 BMS_CellT6 48;
BA_ "sigConfig" SG_ 1744 BMS_CellT6 "null";
BA_ "sigExplanation" SG_ 1744 BMS_CellT6 "null";
BA_ "sigSecLevel" SG_ 1744 BMS_CellT6 "null";
BA_ "GenSigStartValue" SG_ 1744 BMS_CellT7 48;
BA_ "sigConfig" SG_ 1744 BMS_CellT7 "null";
BA_ "sigExplanation" SG_ 1744 BMS_CellT7 "null";
BA_ "sigSecLevel" SG_ 1744 BMS_CellT7 "null";
BA_ "GenSigStartValue" SG_ 1744 BMS_CellT8 48;
BA_ "sigConfig" SG_ 1744 BMS_CellT8 "null";
BA_ "sigExplanation" SG_ 1744 BMS_CellT8 "null";
BA_ "sigSecLevel" SG_ 1744 BMS_CellT8 "null";
BA_ "GenSigStartValue" SG_ 1745 BMS_CellT9 48;
BA_ "sigConfig" SG_ 1745 BMS_CellT9 "null";
BA_ "sigExplanation" SG_ 1745 BMS_CellT9 "null";
BA_ "sigSecLevel" SG_ 1745 BMS_CellT9 "null";
BA_ "GenSigStartValue" SG_ 1745 BMS_CellT10 48;
BA_ "sigConfig" SG_ 1745 BMS_CellT10 "null";
BA_ "sigExplanation" SG_ 1745 BMS_CellT10 "null";
BA_ "sigSecLevel" SG_ 1745 BMS_CellT10 "null";
BA_ "GenSigStartValue" SG_ 1745 BMS_CellT11 48;
BA_ "sigConfig" SG_ 1745 BMS_CellT11 "null";
BA_ "sigExplanation" SG_ 1745 BMS_CellT11 "null";
BA_ "sigSecLevel" SG_ 1745 BMS_CellT11 "null";
BA_ "GenSigStartValue" SG_ 1745 BMS_CellT12 48;
BA_ "sigConfig" SG_ 1745 BMS_CellT12 "null";
BA_ "sigExplanation" SG_ 1745 BMS_CellT12 "null";
BA_ "sigSecLevel" SG_ 1745 BMS_CellT12 "null";
BA_ "GenSigStartValue" SG_ 1745 BMS_CellT13 48;
BA_ "sigConfig" SG_ 1745 BMS_CellT13 "null";
BA_ "sigExplanation" SG_ 1745 BMS_CellT13 "null";
BA_ "sigSecLevel" SG_ 1745 BMS_CellT13 "null";
BA_ "GenSigStartValue" SG_ 1745 BMS_CellT14 48;
BA_ "sigConfig" SG_ 1745 BMS_CellT14 "null";
BA_ "sigExplanation" SG_ 1745 BMS_CellT14 "null";
BA_ "sigSecLevel" SG_ 1745 BMS_CellT14 "null";
BA_ "GenSigStartValue" SG_ 1745 BMS_CellT15 48;
BA_ "sigConfig" SG_ 1745 BMS_CellT15 "null";
BA_ "sigExplanation" SG_ 1745 BMS_CellT15 "null";
BA_ "sigSecLevel" SG_ 1745 BMS_CellT15 "null";
BA_ "GenSigStartValue" SG_ 1745 BMS_CellT16 48;
BA_ "sigConfig" SG_ 1745 BMS_CellT16 "null";
BA_ "sigExplanation" SG_ 1745 BMS_CellT16 "null";
BA_ "sigSecLevel" SG_ 1745 BMS_CellT16 "null";
BA_ "GenSigStartValue" SG_ 1746 BMS_CellT17 48;
BA_ "sigConfig" SG_ 1746 BMS_CellT17 "null";
BA_ "sigExplanation" SG_ 1746 BMS_CellT17 "null";
BA_ "sigSecLevel" SG_ 1746 BMS_CellT17 "null";
BA_ "GenSigStartValue" SG_ 1746 BMS_CellT18 48;
BA_ "sigConfig" SG_ 1746 BMS_CellT18 "null";
BA_ "sigExplanation" SG_ 1746 BMS_CellT18 "null";
BA_ "sigSecLevel" SG_ 1746 BMS_CellT18 "null";
BA_ "GenSigStartValue" SG_ 1746 BMS_CellT19 48;
BA_ "sigConfig" SG_ 1746 BMS_CellT19 "null";
BA_ "sigExplanation" SG_ 1746 BMS_CellT19 "null";
BA_ "sigSecLevel" SG_ 1746 BMS_CellT19 "null";
BA_ "GenSigStartValue" SG_ 1746 BMS_CellT20 48;
BA_ "sigConfig" SG_ 1746 BMS_CellT20 "null";
BA_ "sigExplanation" SG_ 1746 BMS_CellT20 "null";
BA_ "sigSecLevel" SG_ 1746 BMS_CellT20 "null";
BA_ "GenSigStartValue" SG_ 1746 BMS_CellT21 48;
BA_ "sigConfig" SG_ 1746 BMS_CellT21 "null";
BA_ "sigExplanation" SG_ 1746 BMS_CellT21 "null";
BA_ "sigSecLevel" SG_ 1746 BMS_CellT21 "null";
BA_ "GenSigStartValue" SG_ 1746 BMS_CellT22 48;
BA_ "sigConfig" SG_ 1746 BMS_CellT22 "null";
BA_ "sigExplanation" SG_ 1746 BMS_CellT22 "null";
BA_ "sigSecLevel" SG_ 1746 BMS_CellT22 "null";
BA_ "GenSigStartValue" SG_ 1746 BMS_CellT23 48;
BA_ "sigConfig" SG_ 1746 BMS_CellT23 "null";
BA_ "sigExplanation" SG_ 1746 BMS_CellT23 "null";
BA_ "sigSecLevel" SG_ 1746 BMS_CellT23 "null";
BA_ "GenSigStartValue" SG_ 1746 BMS_CellT24 48;
BA_ "sigConfig" SG_ 1746 BMS_CellT24 "null";
BA_ "sigExplanation" SG_ 1746 BMS_CellT24 "null";
BA_ "sigSecLevel" SG_ 1746 BMS_CellT24 "null";
BA_ "GenSigStartValue" SG_ 1747 BMS_CellT25 48;
BA_ "sigConfig" SG_ 1747 BMS_CellT25 "null";
BA_ "sigExplanation" SG_ 1747 BMS_CellT25 "null";
BA_ "sigSecLevel" SG_ 1747 BMS_CellT25 "null";
BA_ "GenSigStartValue" SG_ 1747 BMS_CellT26 48;
BA_ "sigConfig" SG_ 1747 BMS_CellT26 "null";
BA_ "sigExplanation" SG_ 1747 BMS_CellT26 "null";
BA_ "sigSecLevel" SG_ 1747 BMS_CellT26 "null";
BA_ "GenSigStartValue" SG_ 1747 BMS_CellT27 48;
BA_ "sigConfig" SG_ 1747 BMS_CellT27 "null";
BA_ "sigExplanation" SG_ 1747 BMS_CellT27 "null";
BA_ "sigSecLevel" SG_ 1747 BMS_CellT27 "null";
BA_ "GenSigStartValue" SG_ 1747 BMS_CellT28 48;
BA_ "sigConfig" SG_ 1747 BMS_CellT28 "null";
BA_ "sigExplanation" SG_ 1747 BMS_CellT28 "null";
BA_ "sigSecLevel" SG_ 1747 BMS_CellT28 "null";
BA_ "GenSigStartValue" SG_ 1747 BMS_CellT29 48;
BA_ "sigConfig" SG_ 1747 BMS_CellT29 "null";
BA_ "sigExplanation" SG_ 1747 BMS_CellT29 "null";
BA_ "sigSecLevel" SG_ 1747 BMS_CellT29 "null";
BA_ "GenSigStartValue" SG_ 1747 BMS_CellT30 48;
BA_ "sigConfig" SG_ 1747 BMS_CellT30 "null";
BA_ "sigExplanation" SG_ 1747 BMS_CellT30 "null";
BA_ "sigSecLevel" SG_ 1747 BMS_CellT30 "null";
BA_ "GenSigStartValue" SG_ 1747 BMS_CellT31 48;
BA_ "sigConfig" SG_ 1747 BMS_CellT31 "null";
BA_ "sigExplanation" SG_ 1747 BMS_CellT31 "null";
BA_ "sigSecLevel" SG_ 1747 BMS_CellT31 "null";
BA_ "GenSigStartValue" SG_ 1747 BMS_CellT32 48;
BA_ "sigConfig" SG_ 1747 BMS_CellT32 "null";
BA_ "sigExplanation" SG_ 1747 BMS_CellT32 "null";
BA_ "sigSecLevel" SG_ 1747 BMS_CellT32 "null";
BA_ "GenSigStartValue" SG_ 1748 BMS_CellT33 48;
BA_ "sigConfig" SG_ 1748 BMS_CellT33 "null";
BA_ "sigExplanation" SG_ 1748 BMS_CellT33 "null";
BA_ "sigSecLevel" SG_ 1748 BMS_CellT33 "null";
BA_ "GenSigStartValue" SG_ 1748 BMS_CellT34 48;
BA_ "sigConfig" SG_ 1748 BMS_CellT34 "null";
BA_ "sigExplanation" SG_ 1748 BMS_CellT34 "null";
BA_ "sigSecLevel" SG_ 1748 BMS_CellT34 "null";
BA_ "GenSigStartValue" SG_ 1748 BMS_CellT35 48;
BA_ "sigConfig" SG_ 1748 BMS_CellT35 "null";
BA_ "sigExplanation" SG_ 1748 BMS_CellT35 "null";
BA_ "sigSecLevel" SG_ 1748 BMS_CellT35 "null";
BA_ "GenSigStartValue" SG_ 1748 BMS_CellT36 48;
BA_ "sigConfig" SG_ 1748 BMS_CellT36 "null";
BA_ "sigExplanation" SG_ 1748 BMS_CellT36 "null";
BA_ "sigSecLevel" SG_ 1748 BMS_CellT36 "null";
BA_ "GenSigStartValue" SG_ 1748 BMS_CellT37 48;
BA_ "sigConfig" SG_ 1748 BMS_CellT37 "null";
BA_ "sigExplanation" SG_ 1748 BMS_CellT37 "null";
BA_ "sigSecLevel" SG_ 1748 BMS_CellT37 "null";
BA_ "GenSigStartValue" SG_ 1748 BMS_CellT38 48;
BA_ "sigConfig" SG_ 1748 BMS_CellT38 "null";
BA_ "sigExplanation" SG_ 1748 BMS_CellT38 "null";
BA_ "sigSecLevel" SG_ 1748 BMS_CellT38 "null";
BA_ "GenSigStartValue" SG_ 1748 BMS_CellT39 48;
BA_ "sigConfig" SG_ 1748 BMS_CellT39 "null";
BA_ "sigExplanation" SG_ 1748 BMS_CellT39 "null";
BA_ "sigSecLevel" SG_ 1748 BMS_CellT39 "null";
BA_ "GenSigStartValue" SG_ 1748 BMS_CellT40 48;
BA_ "sigConfig" SG_ 1748 BMS_CellT40 "null";
BA_ "sigExplanation" SG_ 1748 BMS_CellT40 "null";
BA_ "sigSecLevel" SG_ 1748 BMS_CellT40 "null";
BA_ "GenSigStartValue" SG_ 1749 BMS_CellT41 48;
BA_ "sigConfig" SG_ 1749 BMS_CellT41 "null";
BA_ "sigExplanation" SG_ 1749 BMS_CellT41 "null";
BA_ "sigSecLevel" SG_ 1749 BMS_CellT41 "null";
BA_ "GenSigStartValue" SG_ 1749 BMS_CellT42 48;
BA_ "sigConfig" SG_ 1749 BMS_CellT42 "null";
BA_ "sigExplanation" SG_ 1749 BMS_CellT42 "null";
BA_ "sigSecLevel" SG_ 1749 BMS_CellT42 "null";
BA_ "GenSigStartValue" SG_ 1749 BMS_CellT43 48;
BA_ "sigConfig" SG_ 1749 BMS_CellT43 "null";
BA_ "sigExplanation" SG_ 1749 BMS_CellT43 "null";
BA_ "sigSecLevel" SG_ 1749 BMS_CellT43 "null";
BA_ "GenSigStartValue" SG_ 1749 BMS_CellT44 48;
BA_ "sigConfig" SG_ 1749 BMS_CellT44 "null";
BA_ "sigExplanation" SG_ 1749 BMS_CellT44 "null";
BA_ "sigSecLevel" SG_ 1749 BMS_CellT44 "null";
BA_ "GenSigStartValue" SG_ 1749 BMS_CellT45 48;
BA_ "sigConfig" SG_ 1749 BMS_CellT45 "null";
BA_ "sigExplanation" SG_ 1749 BMS_CellT45 "null";
BA_ "sigSecLevel" SG_ 1749 BMS_CellT45 "null";
BA_ "GenSigStartValue" SG_ 1749 BMS_CellT46 48;
BA_ "sigConfig" SG_ 1749 BMS_CellT46 "null";
BA_ "sigExplanation" SG_ 1749 BMS_CellT46 "null";
BA_ "sigSecLevel" SG_ 1749 BMS_CellT46 "null";
BA_ "GenSigStartValue" SG_ 1749 BMS_CellT47 48;
BA_ "sigConfig" SG_ 1749 BMS_CellT47 "null";
BA_ "sigExplanation" SG_ 1749 BMS_CellT47 "null";
BA_ "sigSecLevel" SG_ 1749 BMS_CellT47 "null";
BA_ "GenSigStartValue" SG_ 1749 BMS_CellT48 48;
BA_ "sigConfig" SG_ 1749 BMS_CellT48 "null";
BA_ "sigExplanation" SG_ 1749 BMS_CellT48 "null";
BA_ "sigSecLevel" SG_ 1749 BMS_CellT48 "null";
BA_ "GenSigStartValue" SG_ 1750 BMS_CellT49 48;
BA_ "sigConfig" SG_ 1750 BMS_CellT49 "null";
BA_ "sigExplanation" SG_ 1750 BMS_CellT49 "null";
BA_ "sigSecLevel" SG_ 1750 BMS_CellT49 "null";
BA_ "GenSigStartValue" SG_ 1750 BMS_CellT50 48;
BA_ "sigConfig" SG_ 1750 BMS_CellT50 "null";
BA_ "sigExplanation" SG_ 1750 BMS_CellT50 "null";
BA_ "sigSecLevel" SG_ 1750 BMS_CellT50 "null";
BA_ "GenSigStartValue" SG_ 1750 BMS_CellT51 48;
BA_ "sigConfig" SG_ 1750 BMS_CellT51 "null";
BA_ "sigExplanation" SG_ 1750 BMS_CellT51 "null";
BA_ "sigSecLevel" SG_ 1750 BMS_CellT51 "null";
BA_ "GenSigStartValue" SG_ 1750 BMS_CellT52 48;
BA_ "sigConfig" SG_ 1750 BMS_CellT52 "null";
BA_ "sigExplanation" SG_ 1750 BMS_CellT52 "null";
BA_ "sigSecLevel" SG_ 1750 BMS_CellT52 "null";
BA_ "GenSigStartValue" SG_ 1750 BMS_CellT53 48;
BA_ "sigConfig" SG_ 1750 BMS_CellT53 "null";
BA_ "sigExplanation" SG_ 1750 BMS_CellT53 "null";
BA_ "sigSecLevel" SG_ 1750 BMS_CellT53 "null";
BA_ "GenSigStartValue" SG_ 1750 BMS_CellT54 48;
BA_ "sigConfig" SG_ 1750 BMS_CellT54 "null";
BA_ "sigExplanation" SG_ 1750 BMS_CellT54 "null";
BA_ "sigSecLevel" SG_ 1750 BMS_CellT54 "null";
BA_ "GenSigStartValue" SG_ 1750 BMS_CellT55 48;
BA_ "sigConfig" SG_ 1750 BMS_CellT55 "null";
BA_ "sigExplanation" SG_ 1750 BMS_CellT55 "null";
BA_ "sigSecLevel" SG_ 1750 BMS_CellT55 "null";
BA_ "GenSigStartValue" SG_ 1750 BMS_CellT56 48;
BA_ "sigConfig" SG_ 1750 BMS_CellT56 "null";
BA_ "sigExplanation" SG_ 1750 BMS_CellT56 "null";
BA_ "sigSecLevel" SG_ 1750 BMS_CellT56 "null";
BA_ "GenSigStartValue" SG_ 1751 BMS_CellT57 48;
BA_ "sigConfig" SG_ 1751 BMS_CellT57 "null";
BA_ "sigExplanation" SG_ 1751 BMS_CellT57 "null";
BA_ "sigSecLevel" SG_ 1751 BMS_CellT57 "null";
BA_ "GenSigStartValue" SG_ 1751 BMS_CellT58 48;
BA_ "sigConfig" SG_ 1751 BMS_CellT58 "null";
BA_ "sigExplanation" SG_ 1751 BMS_CellT58 "null";
BA_ "sigSecLevel" SG_ 1751 BMS_CellT58 "null";
BA_ "GenSigStartValue" SG_ 1751 BMS_CellT59 48;
BA_ "sigConfig" SG_ 1751 BMS_CellT59 "null";
BA_ "sigExplanation" SG_ 1751 BMS_CellT59 "null";
BA_ "sigSecLevel" SG_ 1751 BMS_CellT59 "null";
BA_ "GenSigStartValue" SG_ 1751 BMS_CellT60 48;
BA_ "sigConfig" SG_ 1751 BMS_CellT60 "null";
BA_ "sigExplanation" SG_ 1751 BMS_CellT60 "null";
BA_ "sigSecLevel" SG_ 1751 BMS_CellT60 "null";
BA_ "GenSigStartValue" SG_ 1751 BMS_CellT61 48;
BA_ "sigConfig" SG_ 1751 BMS_CellT61 "null";
BA_ "sigExplanation" SG_ 1751 BMS_CellT61 "null";
BA_ "sigSecLevel" SG_ 1751 BMS_CellT61 "null";
BA_ "GenSigStartValue" SG_ 1751 BMS_CellT62 48;
BA_ "sigConfig" SG_ 1751 BMS_CellT62 "null";
BA_ "sigExplanation" SG_ 1751 BMS_CellT62 "null";
BA_ "sigSecLevel" SG_ 1751 BMS_CellT62 "null";
BA_ "GenSigStartValue" SG_ 1751 BMS_CellT63 48;
BA_ "sigConfig" SG_ 1751 BMS_CellT63 "null";
BA_ "sigExplanation" SG_ 1751 BMS_CellT63 "null";
BA_ "sigSecLevel" SG_ 1751 BMS_CellT63 "null";
BA_ "GenSigStartValue" SG_ 1751 BMS_CellT64 48;
BA_ "sigConfig" SG_ 1751 BMS_CellT64 "null";
BA_ "sigExplanation" SG_ 1751 BMS_CellT64 "null";
BA_ "sigSecLevel" SG_ 1751 BMS_CellT64 "null";
BA_ "GenSigStartValue" SG_ 1752 BMS_CellT65 48;
BA_ "sigConfig" SG_ 1752 BMS_CellT65 "null";
BA_ "sigExplanation" SG_ 1752 BMS_CellT65 "null";
BA_ "sigSecLevel" SG_ 1752 BMS_CellT65 "null";
BA_ "GenSigStartValue" SG_ 1752 BMS_CellT66 48;
BA_ "sigConfig" SG_ 1752 BMS_CellT66 "null";
BA_ "sigExplanation" SG_ 1752 BMS_CellT66 "null";
BA_ "sigSecLevel" SG_ 1752 BMS_CellT66 "null";
BA_ "GenSigStartValue" SG_ 1752 BMS_CellT67 48;
BA_ "sigConfig" SG_ 1752 BMS_CellT67 "null";
BA_ "sigExplanation" SG_ 1752 BMS_CellT67 "null";
BA_ "sigSecLevel" SG_ 1752 BMS_CellT67 "null";
BA_ "GenSigStartValue" SG_ 1752 BMS_CellT68 48;
BA_ "sigConfig" SG_ 1752 BMS_CellT68 "null";
BA_ "sigExplanation" SG_ 1752 BMS_CellT68 "null";
BA_ "sigSecLevel" SG_ 1752 BMS_CellT68 "null";
BA_ "GenSigStartValue" SG_ 1752 BMS_CellT69 48;
BA_ "sigConfig" SG_ 1752 BMS_CellT69 "null";
BA_ "sigExplanation" SG_ 1752 BMS_CellT69 "null";
BA_ "sigSecLevel" SG_ 1752 BMS_CellT69 "null";
BA_ "GenSigStartValue" SG_ 1752 BMS_CellT70 48;
BA_ "sigConfig" SG_ 1752 BMS_CellT70 "null";
BA_ "sigExplanation" SG_ 1752 BMS_CellT70 "null";
BA_ "sigSecLevel" SG_ 1752 BMS_CellT70 "null";
BA_ "GenSigStartValue" SG_ 1752 BMS_CellT71 48;
BA_ "sigConfig" SG_ 1752 BMS_CellT71 "null";
BA_ "sigExplanation" SG_ 1752 BMS_CellT71 "null";
BA_ "sigSecLevel" SG_ 1752 BMS_CellT71 "null";
BA_ "GenSigStartValue" SG_ 1752 BMS_CellT72 48;
BA_ "sigConfig" SG_ 1752 BMS_CellT72 "null";
BA_ "sigExplanation" SG_ 1752 BMS_CellT72 "null";
BA_ "sigSecLevel" SG_ 1752 BMS_CellT72 "null";
BA_ "GenSigStartValue" SG_ 1753 BMS_CellT73 48;
BA_ "sigConfig" SG_ 1753 BMS_CellT73 "null";
BA_ "sigExplanation" SG_ 1753 BMS_CellT73 "null";
BA_ "sigSecLevel" SG_ 1753 BMS_CellT73 "null";
BA_ "GenSigStartValue" SG_ 1753 BMS_CellT74 48;
BA_ "sigConfig" SG_ 1753 BMS_CellT74 "null";
BA_ "sigExplanation" SG_ 1753 BMS_CellT74 "null";
BA_ "sigSecLevel" SG_ 1753 BMS_CellT74 "null";
BA_ "GenSigStartValue" SG_ 1753 BMS_CellT75 48;
BA_ "sigConfig" SG_ 1753 BMS_CellT75 "null";
BA_ "sigExplanation" SG_ 1753 BMS_CellT75 "null";
BA_ "sigSecLevel" SG_ 1753 BMS_CellT75 "null";
BA_ "GenSigStartValue" SG_ 1753 BMS_CellT76 48;
BA_ "sigConfig" SG_ 1753 BMS_CellT76 "null";
BA_ "sigExplanation" SG_ 1753 BMS_CellT76 "null";
BA_ "sigSecLevel" SG_ 1753 BMS_CellT76 "null";
BA_ "GenSigStartValue" SG_ 1753 BMS_CellT77 48;
BA_ "sigConfig" SG_ 1753 BMS_CellT77 "null";
BA_ "sigExplanation" SG_ 1753 BMS_CellT77 "null";
BA_ "sigSecLevel" SG_ 1753 BMS_CellT77 "null";
BA_ "GenSigStartValue" SG_ 1753 BMS_CellT78 48;
BA_ "sigConfig" SG_ 1753 BMS_CellT78 "null";
BA_ "sigExplanation" SG_ 1753 BMS_CellT78 "null";
BA_ "sigSecLevel" SG_ 1753 BMS_CellT78 "null";
BA_ "GenSigStartValue" SG_ 1753 BMS_CellT79 48;
BA_ "sigConfig" SG_ 1753 BMS_CellT79 "null";
BA_ "sigExplanation" SG_ 1753 BMS_CellT79 "null";
BA_ "sigSecLevel" SG_ 1753 BMS_CellT79 "null";
BA_ "GenSigStartValue" SG_ 1753 BMS_CellT80 48;
BA_ "sigConfig" SG_ 1753 BMS_CellT80 "null";
BA_ "sigExplanation" SG_ 1753 BMS_CellT80 "null";
BA_ "sigSecLevel" SG_ 1753 BMS_CellT80 "null";
BA_ "sigConfig" SG_ 1754 VCU_PwrGridAllwMaxPwrSplyCrt "null";
BA_ "sigExplanation" SG_ 1754 VCU_PwrGridAllwMaxPwrSplyCrt "null";
BA_ "sigSecLevel" SG_ 1754 VCU_PwrGridAllwMaxPwrSplyCrt "null";
BA_ "sigConfig" SG_ 1754 VCU_ChrgLineAllwtCrt "null";
BA_ "sigExplanation" SG_ 1754 VCU_ChrgLineAllwtCrt "null";
BA_ "sigSecLevel" SG_ 1754 VCU_ChrgLineAllwtCrt "null";
BA_ "sigConfig" SG_ 1754 VCU_DchaLineAllwCrt "null";
BA_ "sigExplanation" SG_ 1754 VCU_DchaLineAllwCrt "null";
BA_ "sigSecLevel" SG_ 1754 VCU_DchaLineAllwCrt "null";
BA_ "sigConfig" SG_ 1754 VCU_DchaVehSts "null";
BA_ "sigExplanation" SG_ 1754 VCU_DchaVehSts "null";
BA_ "sigSecLevel" SG_ 1754 VCU_DchaVehSts "null";
BA_ "GenSigStartValue" SG_ 1754 VCU_DCChrgSoktT1 48;
BA_ "sigConfig" SG_ 1754 VCU_DCChrgSoktT1 "null";
BA_ "sigExplanation" SG_ 1754 VCU_DCChrgSoktT1 "null";
BA_ "sigSecLevel" SG_ 1754 VCU_DCChrgSoktT1 "null";
BA_ "GenSigStartValue" SG_ 1754 VCU_DCChrgSoktT2 48;
BA_ "sigConfig" SG_ 1754 VCU_DCChrgSoktT2 "null";
BA_ "sigExplanation" SG_ 1754 VCU_DCChrgSoktT2 "null";
BA_ "sigSecLevel" SG_ 1754 VCU_DCChrgSoktT2 "null";
BA_ "GenSigStartValue" SG_ 1754 VCU_ACChrgDchaSoktT1 48;
BA_ "sigConfig" SG_ 1754 VCU_ACChrgDchaSoktT1 "null";
BA_ "sigExplanation" SG_ 1754 VCU_ACChrgDchaSoktT1 "null";
BA_ "sigSecLevel" SG_ 1754 VCU_ACChrgDchaSoktT1 "null";
BA_ "sigConfig" SG_ 1754 VCU_6DA_SSecOC_Fresh_Byte0 "null";
BA_ "sigExplanation" SG_ 1754 VCU_6DA_SSecOC_Fresh_Byte0 "null";
BA_ "sigSecLevel" SG_ 1754 VCU_6DA_SSecOC_Fresh_Byte0 "null";
BA_ "sigConfig" SG_ 1754 VCU_6DA_SSecOC_MAC_Byte0 "null";
BA_ "sigExplanation" SG_ 1754 VCU_6DA_SSecOC_MAC_Byte0 "null";
BA_ "sigSecLevel" SG_ 1754 VCU_6DA_SSecOC_MAC_Byte0 "null";
BA_ "sigConfig" SG_ 1754 VCU_6DA_SSecOC_MAC_Byte1 "null";
BA_ "sigExplanation" SG_ 1754 VCU_6DA_SSecOC_MAC_Byte1 "null";
BA_ "sigSecLevel" SG_ 1754 VCU_6DA_SSecOC_MAC_Byte1 "null";
BA_ "sigConfig" SG_ 1754 VCU_6DA_SSecOC_MAC_Byte2 "null";
BA_ "sigExplanation" SG_ 1754 VCU_6DA_SSecOC_MAC_Byte2 "null";
BA_ "sigSecLevel" SG_ 1754 VCU_6DA_SSecOC_MAC_Byte2 "null";
BA_ "GenSigStartValue" SG_ 1755 BMS_CellT81 48;
BA_ "sigConfig" SG_ 1755 BMS_CellT81 "null";
BA_ "sigExplanation" SG_ 1755 BMS_CellT81 "null";
BA_ "sigSecLevel" SG_ 1755 BMS_CellT81 "null";
BA_ "GenSigStartValue" SG_ 1755 BMS_CellT82 48;
BA_ "sigConfig" SG_ 1755 BMS_CellT82 "null";
BA_ "sigExplanation" SG_ 1755 BMS_CellT82 "null";
BA_ "sigSecLevel" SG_ 1755 BMS_CellT82 "null";
BA_ "GenSigStartValue" SG_ 1755 BMS_CellT83 48;
BA_ "sigConfig" SG_ 1755 BMS_CellT83 "null";
BA_ "sigExplanation" SG_ 1755 BMS_CellT83 "null";
BA_ "sigSecLevel" SG_ 1755 BMS_CellT83 "null";
BA_ "GenSigStartValue" SG_ 1755 BMS_CellT84 48;
BA_ "sigConfig" SG_ 1755 BMS_CellT84 "null";
BA_ "sigExplanation" SG_ 1755 BMS_CellT84 "null";
BA_ "sigSecLevel" SG_ 1755 BMS_CellT84 "null";
BA_ "GenSigStartValue" SG_ 1755 BMS_CellT85 48;
BA_ "sigConfig" SG_ 1755 BMS_CellT85 "null";
BA_ "sigExplanation" SG_ 1755 BMS_CellT85 "null";
BA_ "sigSecLevel" SG_ 1755 BMS_CellT85 "null";
BA_ "GenSigStartValue" SG_ 1755 BMS_CellT86 48;
BA_ "sigConfig" SG_ 1755 BMS_CellT86 "null";
BA_ "sigExplanation" SG_ 1755 BMS_CellT86 "null";
BA_ "sigSecLevel" SG_ 1755 BMS_CellT86 "null";
BA_ "GenSigStartValue" SG_ 1755 BMS_CellT87 48;
BA_ "sigConfig" SG_ 1755 BMS_CellT87 "null";
BA_ "sigExplanation" SG_ 1755 BMS_CellT87 "null";
BA_ "sigSecLevel" SG_ 1755 BMS_CellT87 "null";
BA_ "GenSigStartValue" SG_ 1755 BMS_CellT88 48;
BA_ "sigConfig" SG_ 1755 BMS_CellT88 "null";
BA_ "sigExplanation" SG_ 1755 BMS_CellT88 "null";
BA_ "sigSecLevel" SG_ 1755 BMS_CellT88 "null";
BA_ "GenSigSendType" SG_ 1756 BMS_mxCounterEnergy 4;
BA_ "sigConfig" SG_ 1756 BMS_mxCounterEnergy "null";
BA_ "sigExplanation" SG_ 1756 BMS_mxCounterEnergy "null";
BA_ "sigSecLevel" SG_ 1756 BMS_mxCounterEnergy "null";
BA_ "GenSigSendType" SG_ 1756 BMS_mxEnergyValue1 4;
BA_ "sigConfig" SG_ 1756 BMS_mxEnergyValue1 "null";
BA_ "sigExplanation" SG_ 1756 BMS_mxEnergyValue1 "null";
BA_ "sigSecLevel" SG_ 1756 BMS_mxEnergyValue1 "null";
BA_ "GenSigSendType" SG_ 1756 BMS_mxEnergyValue2 4;
BA_ "sigConfig" SG_ 1756 BMS_mxEnergyValue2 "null";
BA_ "sigExplanation" SG_ 1756 BMS_mxEnergyValue2 "null";
BA_ "sigSecLevel" SG_ 1756 BMS_mxEnergyValue2 "null";
BA_ "sigConfig" SG_ 1757 BMS_PVIU_actPower "null";
BA_ "sigExplanation" SG_ 1757 BMS_PVIU_actPower "null";
BA_ "sigSecLevel" SG_ 1757 BMS_PVIU_actPower "null";
BA_ "sigConfig" SG_ 1757 BMS_PVIU_EnergyOverall "null";
BA_ "sigExplanation" SG_ 1757 BMS_PVIU_EnergyOverall "null";
BA_ "sigSecLevel" SG_ 1757 BMS_PVIU_EnergyOverall "null";
BA_ "sigConfig" SG_ 1757 BMS_PVIU_ActEngyYear "null";
BA_ "sigExplanation" SG_ 1757 BMS_PVIU_ActEngyYear "null";
BA_ "sigSecLevel" SG_ 1757 BMS_PVIU_ActEngyYear "null";
BA_ "sigConfig" SG_ 1758 DCDC_CheckSum2 "null";
BA_ "sigExplanation" SG_ 1758 DCDC_CheckSum2 "null";
BA_ "sigSecLevel" SG_ 1758 DCDC_CheckSum2 "null";
BA_ "sigConfig" SG_ 1758 BMS_RollCounter2 "null";
BA_ "sigExplanation" SG_ 1758 BMS_RollCounter2 "null";
BA_ "sigSecLevel" SG_ 1758 BMS_RollCounter2 "null";
BA_ "sigConfig" SG_ 1758 PVIU_DCDC_ActLVVolt "null";
BA_ "sigExplanation" SG_ 1758 PVIU_DCDC_ActLVVolt "null";
BA_ "sigSecLevel" SG_ 1758 PVIU_DCDC_ActLVVolt "null";
BA_ "sigConfig" SG_ 1758 PVIU_DCDC_ActLVCurr "null";
BA_ "sigExplanation" SG_ 1758 PVIU_DCDC_ActLVCurr "null";
BA_ "sigSecLevel" SG_ 1758 PVIU_DCDC_ActLVCurr "null";
BA_ "sigConfig" SG_ 1758 PVIU_DCDC_ActHVVolt "null";
BA_ "sigExplanation" SG_ 1758 PVIU_DCDC_ActHVVolt "null";
BA_ "sigSecLevel" SG_ 1758 PVIU_DCDC_ActHVVolt "null";
BA_ "sigConfig" SG_ 1758 PVIU_DCDC_ActHVCurr "null";
BA_ "sigExplanation" SG_ 1758 PVIU_DCDC_ActHVCurr "null";
BA_ "sigSecLevel" SG_ 1758 PVIU_DCDC_ActHVCurr "null";
BA_ "sigConfig" SG_ 1759 BMS_0x6DF_CheckSum "null";
BA_ "sigExplanation" SG_ 1759 BMS_0x6DF_CheckSum "null";
BA_ "sigSecLevel" SG_ 1759 BMS_0x6DF_CheckSum "null";
BA_ "sigConfig" SG_ 1759 BMS_0x6DF_RollCounter "null";
BA_ "sigExplanation" SG_ 1759 BMS_0x6DF_RollCounter "null";
BA_ "sigSecLevel" SG_ 1759 BMS_0x6DF_RollCounter "null";
BA_ "sigConfig" SG_ 1759 BMS_PVIU_ModeReqSt "null";
BA_ "sigExplanation" SG_ 1759 BMS_PVIU_ModeReqSt "null";
BA_ "sigSecLevel" SG_ 1759 BMS_PVIU_ModeReqSt "null";
BA_ "sigConfig" SG_ 1759 BMS_PVIU_ModeSt "null";
BA_ "sigExplanation" SG_ 1759 BMS_PVIU_ModeSt "null";
BA_ "sigSecLevel" SG_ 1759 BMS_PVIU_ModeSt "null";
BA_ "sigConfig" SG_ 1759 BMS_PVIU_AvailInputPower "null";
BA_ "sigExplanation" SG_ 1759 BMS_PVIU_AvailInputPower "null";
BA_ "sigSecLevel" SG_ 1759 BMS_PVIU_AvailInputPower "null";
BA_ "sigConfig" SG_ 1759 BMS_PVIU_ActOutputPower "null";
BA_ "sigExplanation" SG_ 1759 BMS_PVIU_ActOutputPower "null";
BA_ "sigSecLevel" SG_ 1759 BMS_PVIU_ActOutputPower "null";
BA_ "sigConfig" SG_ 1759 BMS_PVIU_ActOutputEnergy "null";
BA_ "sigExplanation" SG_ 1759 BMS_PVIU_ActOutputEnergy "null";
BA_ "sigSecLevel" SG_ 1759 BMS_PVIU_ActOutputEnergy "null";
BA_ "sigConfig" SG_ 1759 BMS_PVIU_FailSt "null";
BA_ "sigExplanation" SG_ 1759 BMS_PVIU_FailSt "null";
BA_ "sigSecLevel" SG_ 1759 BMS_PVIU_FailSt "null";
BA_ "sigConfig" SG_ 1759 BMS_PVIU_F_Input_OVP "null";
BA_ "sigExplanation" SG_ 1759 BMS_PVIU_F_Input_OVP "null";
BA_ "sigSecLevel" SG_ 1759 BMS_PVIU_F_Input_OVP "null";
BA_ "sigConfig" SG_ 1759 BMS_PVIU_F_Input_UVP "null";
BA_ "sigExplanation" SG_ 1759 BMS_PVIU_F_Input_UVP "null";
BA_ "sigSecLevel" SG_ 1759 BMS_PVIU_F_Input_UVP "null";
BA_ "sigConfig" SG_ 1759 BMS_PVIU_F_Output_OVP "null";
BA_ "sigExplanation" SG_ 1759 BMS_PVIU_F_Output_OVP "null";
BA_ "sigSecLevel" SG_ 1759 BMS_PVIU_F_Output_OVP "null";
BA_ "sigConfig" SG_ 1759 BMS_PVIU_F_Output_UVP "null";
BA_ "sigExplanation" SG_ 1759 BMS_PVIU_F_Output_UVP "null";
BA_ "sigSecLevel" SG_ 1759 BMS_PVIU_F_Output_UVP "null";
BA_ "sigConfig" SG_ 1759 BMS_PVIU_F_12V_OVP "null";
BA_ "sigExplanation" SG_ 1759 BMS_PVIU_F_12V_OVP "null";
BA_ "sigSecLevel" SG_ 1759 BMS_PVIU_F_12V_OVP "null";
BA_ "sigConfig" SG_ 1759 BMS_PVIU_F_12V_UVP "null";
BA_ "sigExplanation" SG_ 1759 BMS_PVIU_F_12V_UVP "null";
BA_ "sigSecLevel" SG_ 1759 BMS_PVIU_F_12V_UVP "null";
BA_ "sigConfig" SG_ 1759 BMS_PVIU_F_Output_SCP "null";
BA_ "sigExplanation" SG_ 1759 BMS_PVIU_F_Output_SCP "null";
BA_ "sigSecLevel" SG_ 1759 BMS_PVIU_F_Output_SCP "null";
BA_ "sigConfig" SG_ 1759 BMS_PVIU_F_OTP "null";
BA_ "sigExplanation" SG_ 1759 BMS_PVIU_F_OTP "null";
BA_ "sigSecLevel" SG_ 1759 BMS_PVIU_F_OTP "null";
BA_ "sigConfig" SG_ 1759 BMS_PVIU_F_HVIL "null";
BA_ "sigExplanation" SG_ 1759 BMS_PVIU_F_HVIL "null";
BA_ "sigSecLevel" SG_ 1759 BMS_PVIU_F_HVIL "null";
BA_ "sigConfig" SG_ 1759 BMS_PVIU_F_CANRx_Timeout "null";
BA_ "sigExplanation" SG_ 1759 BMS_PVIU_F_CANRx_Timeout "null";
BA_ "sigSecLevel" SG_ 1759 BMS_PVIU_F_CANRx_Timeout "null";
BA_ "sigConfig" SG_ 1759 BMS_PVIU_F_Output_OCP "null";
BA_ "sigExplanation" SG_ 1759 BMS_PVIU_F_Output_OCP "null";
BA_ "sigSecLevel" SG_ 1759 BMS_PVIU_F_Output_OCP "null";
BA_ "sigConfig" SG_ 1765 VCU_VINCod1 "null";
BA_ "sigExplanation" SG_ 1765 VCU_VINCod1 "null";
BA_ "sigSecLevel" SG_ 1765 VCU_VINCod1 "null";
BA_ "sigConfig" SG_ 1766 VCU_VINCod2 "null";
BA_ "sigExplanation" SG_ 1766 VCU_VINCod2 "null";
BA_ "sigSecLevel" SG_ 1766 VCU_VINCod2 "null";
BA_ "sigConfig" SG_ 1767 VCU_VINCod3 "null";
BA_ "sigExplanation" SG_ 1767 VCU_VINCod3 "null";
BA_ "sigSecLevel" SG_ 1767 VCU_VINCod3 "null";
BA_ "sigConfig" SG_ 1776 BMS_PwrBattPackCod1 "null";
BA_ "sigExplanation" SG_ 1776 BMS_PwrBattPackCod1 "null";
BA_ "sigSecLevel" SG_ 1776 BMS_PwrBattPackCod1 "null";
BA_ "sigConfig" SG_ 1777 BMS_PwrBattPackCod2 "null";
BA_ "sigExplanation" SG_ 1777 BMS_PwrBattPackCod2 "null";
BA_ "sigSecLevel" SG_ 1777 BMS_PwrBattPackCod2 "null";
BA_ "sigConfig" SG_ 1778 BMS_PwrBattPackCod3 "null";
BA_ "sigExplanation" SG_ 1778 BMS_PwrBattPackCod3 "null";
BA_ "sigSecLevel" SG_ 1778 BMS_PwrBattPackCod3 "null";
BA_ "sigConfig" SG_ 1779 BMS_PwrBattPackCod4 "null";
BA_ "sigExplanation" SG_ 1779 BMS_PwrBattPackCod4 "null";
BA_ "sigSecLevel" SG_ 1779 BMS_PwrBattPackCod4 "null";
BA_ "sigConfig" SG_ 1780 BMS_PwrBattPackNr "null";
BA_ "sigExplanation" SG_ 1780 BMS_PwrBattPackNr "null";
BA_ "sigSecLevel" SG_ 1780 BMS_PwrBattPackNr "null";
BA_ "sigConfig" SG_ 1780 BMS_PwrBattPackCodLen "null";
BA_ "sigExplanation" SG_ 1780 BMS_PwrBattPackCodLen "null";
BA_ "sigSecLevel" SG_ 1780 BMS_PwrBattPackCodLen "null";
BA_ "sigConfig" SG_ 1780 BMS_PwrBattSubsysNr "null";
BA_ "sigExplanation" SG_ 1780 BMS_PwrBattSubsysNr "null";
BA_ "sigSecLevel" SG_ 1780 BMS_PwrBattSubsysNr "null";
BA_ "sigConfig" SG_ 1780 BMS_PwrBattCellSum "null";
BA_ "sigExplanation" SG_ 1780 BMS_PwrBattCellSum "null";
BA_ "sigSecLevel" SG_ 1780 BMS_PwrBattCellSum "null";
BA_ "sigConfig" SG_ 1780 BMS_PwrBattCellTSum "null";
BA_ "sigExplanation" SG_ 1780 BMS_PwrBattCellTSum "null";
BA_ "sigSecLevel" SG_ 1780 BMS_PwrBattCellTSum "null";
BA_ "sigConfig" SG_ 1780 BMS_PwrBattFltSum "null";
BA_ "sigExplanation" SG_ 1780 BMS_PwrBattFltSum "null";
BA_ "sigSecLevel" SG_ 1780 BMS_PwrBattFltSum "null";
BA_ "sigConfig" SG_ 1791 VCU_BattChrgSOC "null";
BA_ "sigExplanation" SG_ 1791 VCU_BattChrgSOC "null";
BA_ "sigSecLevel" SG_ 1791 VCU_BattChrgSOC "null";
BA_ "sigConfig" SG_ 1791 VCU_BattChrgSOCEEPROM "null";
BA_ "sigExplanation" SG_ 1791 VCU_BattChrgSOCEEPROM "null";
BA_ "sigSecLevel" SG_ 1791 VCU_BattChrgSOCEEPROM "null";
BA_ "sigConfig" SG_ 1791 VCU_UsrAvrgPwrCns "null";
BA_ "sigExplanation" SG_ 1791 VCU_UsrAvrgPwrCns "null";
BA_ "sigSecLevel" SG_ 1791 VCU_UsrAvrgPwrCns "null";
BA_ "sigConfig" SG_ 1791 VCU_DrvgMilgReqReducePwrLvl "null";
BA_ "sigExplanation" SG_ 1791 VCU_DrvgMilgReqReducePwrLvl "null";
BA_ "sigSecLevel" SG_ 1791 VCU_DrvgMilgReqReducePwrLvl "null";
BA_ "GenSigSendType" SG_ 1796 BMS_XCP_Tx_Byte0 1;
BA_ "sigConfig" SG_ 1796 BMS_XCP_Tx_Byte0 "null";
BA_ "sigExplanation" SG_ 1796 BMS_XCP_Tx_Byte0 "null";
BA_ "sigSecLevel" SG_ 1796 BMS_XCP_Tx_Byte0 "null";
BA_ "GenSigSendType" SG_ 1796 BMS_XCP_Tx_Byte1 1;
BA_ "sigConfig" SG_ 1796 BMS_XCP_Tx_Byte1 "null";
BA_ "sigExplanation" SG_ 1796 BMS_XCP_Tx_Byte1 "null";
BA_ "sigSecLevel" SG_ 1796 BMS_XCP_Tx_Byte1 "null";
BA_ "GenSigSendType" SG_ 1796 BMS_XCP_Tx_Byte2 1;
BA_ "sigConfig" SG_ 1796 BMS_XCP_Tx_Byte2 "null";
BA_ "sigExplanation" SG_ 1796 BMS_XCP_Tx_Byte2 "null";
BA_ "sigSecLevel" SG_ 1796 BMS_XCP_Tx_Byte2 "null";
BA_ "GenSigSendType" SG_ 1796 BMS_XCP_Tx_Byte3 1;
BA_ "sigConfig" SG_ 1796 BMS_XCP_Tx_Byte3 "null";
BA_ "sigExplanation" SG_ 1796 BMS_XCP_Tx_Byte3 "null";
BA_ "sigSecLevel" SG_ 1796 BMS_XCP_Tx_Byte3 "null";
BA_ "GenSigSendType" SG_ 1796 BMS_XCP_Tx_Byte4 1;
BA_ "sigConfig" SG_ 1796 BMS_XCP_Tx_Byte4 "null";
BA_ "sigExplanation" SG_ 1796 BMS_XCP_Tx_Byte4 "null";
BA_ "sigSecLevel" SG_ 1796 BMS_XCP_Tx_Byte4 "null";
BA_ "GenSigSendType" SG_ 1796 BMS_XCP_Tx_Byte5 1;
BA_ "sigConfig" SG_ 1796 BMS_XCP_Tx_Byte5 "null";
BA_ "sigExplanation" SG_ 1796 BMS_XCP_Tx_Byte5 "null";
BA_ "sigSecLevel" SG_ 1796 BMS_XCP_Tx_Byte5 "null";
BA_ "GenSigSendType" SG_ 1796 BMS_XCP_Tx_Byte6 1;
BA_ "sigConfig" SG_ 1796 BMS_XCP_Tx_Byte6 "null";
BA_ "sigExplanation" SG_ 1796 BMS_XCP_Tx_Byte6 "null";
BA_ "sigSecLevel" SG_ 1796 BMS_XCP_Tx_Byte6 "null";
BA_ "GenSigSendType" SG_ 1796 BMS_XCP_Tx_Byte7 1;
BA_ "sigConfig" SG_ 1796 BMS_XCP_Tx_Byte7 "null";
BA_ "sigExplanation" SG_ 1796 BMS_XCP_Tx_Byte7 "null";
BA_ "sigSecLevel" SG_ 1796 BMS_XCP_Tx_Byte7 "null";
BA_ "GenSigSendType" SG_ 1797 BMS_XCP_Rx_Byte0 1;
BA_ "sigConfig" SG_ 1797 BMS_XCP_Rx_Byte0 "null";
BA_ "sigExplanation" SG_ 1797 BMS_XCP_Rx_Byte0 "null";
BA_ "sigSecLevel" SG_ 1797 BMS_XCP_Rx_Byte0 "null";
BA_ "GenSigSendType" SG_ 1797 BMS_XCP_Rx_Byte1 1;
BA_ "sigConfig" SG_ 1797 BMS_XCP_Rx_Byte1 "null";
BA_ "sigExplanation" SG_ 1797 BMS_XCP_Rx_Byte1 "null";
BA_ "sigSecLevel" SG_ 1797 BMS_XCP_Rx_Byte1 "null";
BA_ "GenSigSendType" SG_ 1797 BMS_XCP_Rx_Byte2 1;
BA_ "sigConfig" SG_ 1797 BMS_XCP_Rx_Byte2 "null";
BA_ "sigExplanation" SG_ 1797 BMS_XCP_Rx_Byte2 "null";
BA_ "sigSecLevel" SG_ 1797 BMS_XCP_Rx_Byte2 "null";
BA_ "GenSigSendType" SG_ 1797 BMS_XCP_Rx_Byte3 1;
BA_ "sigConfig" SG_ 1797 BMS_XCP_Rx_Byte3 "null";
BA_ "sigExplanation" SG_ 1797 BMS_XCP_Rx_Byte3 "null";
BA_ "sigSecLevel" SG_ 1797 BMS_XCP_Rx_Byte3 "null";
BA_ "GenSigSendType" SG_ 1797 BMS_XCP_Rx_Byte4 1;
BA_ "sigConfig" SG_ 1797 BMS_XCP_Rx_Byte4 "null";
BA_ "sigExplanation" SG_ 1797 BMS_XCP_Rx_Byte4 "null";
BA_ "sigSecLevel" SG_ 1797 BMS_XCP_Rx_Byte4 "null";
BA_ "GenSigSendType" SG_ 1797 BMS_XCP_Rx_Byte5 1;
BA_ "sigConfig" SG_ 1797 BMS_XCP_Rx_Byte5 "null";
BA_ "sigExplanation" SG_ 1797 BMS_XCP_Rx_Byte5 "null";
BA_ "sigSecLevel" SG_ 1797 BMS_XCP_Rx_Byte5 "null";
BA_ "GenSigSendType" SG_ 1797 BMS_XCP_Rx_Byte6 1;
BA_ "sigConfig" SG_ 1797 BMS_XCP_Rx_Byte6 "null";
BA_ "sigExplanation" SG_ 1797 BMS_XCP_Rx_Byte6 "null";
BA_ "sigSecLevel" SG_ 1797 BMS_XCP_Rx_Byte6 "null";
BA_ "GenSigSendType" SG_ 1797 BMS_XCP_Rx_Byte7 1;
BA_ "sigConfig" SG_ 1797 BMS_XCP_Rx_Byte7 "null";
BA_ "sigExplanation" SG_ 1797 BMS_XCP_Rx_Byte7 "null";
BA_ "sigSecLevel" SG_ 1797 BMS_XCP_Rx_Byte7 "null";
BA_ "GenSigSendType" SG_ 1799 VCU_XCP_Tx_Signal 7;
BA_ "GenSigSendType" SG_ 1800 ECC_XCP_Tx_Signal 7;
BA_ "GenSigStartValue" SG_ 1812 DCDC_TempMOS 45;
BA_ "GenSigStartValue" SG_ 1812 OBC_LLCTemp 45;
BA_ "GenSigStartValue" SG_ 1812 OBC_PFCTemp 45;
BA_ "GenSigSendType" SG_ 1874 WTC_H_Byte2_Req 1;
BA_ "GenSigSendType" SG_ 1874 WTC_H_Byte3_Req 1;
BA_ "GenSigSendType" SG_ 1874 WTC_H_Byte4_Req 1;
BA_ "GenSigSendType" SG_ 1874 WTC_H_Byte5_Req 1;
BA_ "GenSigSendType" SG_ 1874 WTC_H_Byte6_Req 1;
BA_ "GenSigSendType" SG_ 1874 WTC_H_Byte7_Req 1;
BA_ "GenSigSendType" SG_ 1874 WTC_H_Byte8_Req 1;
BA_ "GenSigSendType" SG_ 1874 WTC_H_TPCI_Req 1;
BA_ "GenSigSendType" SG_ 1882 WTC_H_Byte2_Resp 1;
BA_ "GenSigSendType" SG_ 1882 WTC_H_Byte3_Resp 1;
BA_ "GenSigSendType" SG_ 1882 WTC_H_Byte4_Resp 1;
BA_ "GenSigSendType" SG_ 1882 WTC_H_Byte5_Resp 1;
BA_ "GenSigSendType" SG_ 1882 WTC_H_Byte6_Resp 1;
BA_ "GenSigSendType" SG_ 1882 WTC_H_Byte7_Resp 1;
BA_ "GenSigSendType" SG_ 1882 WTC_H_Byte8_Resp 1;
BA_ "GenSigSendType" SG_ 1882 WTC_H_TPCI_Resp 1;
BA_ "GenSigSendType" SG_ 1937 PVIU_Byte2_Req 1;
BA_ "GenSigSendType" SG_ 1937 PVIU_Byte3_Req 1;
BA_ "GenSigSendType" SG_ 1937 PVIU_Byte4_Req 1;
BA_ "GenSigSendType" SG_ 1937 PVIU_Byte5_Req 1;
BA_ "GenSigSendType" SG_ 1937 PVIU_Byte6_Req 1;
BA_ "GenSigSendType" SG_ 1937 PVIU_Byte7_Req 1;
BA_ "GenSigSendType" SG_ 1937 PVIU_Byte8_Req 1;
BA_ "GenSigSendType" SG_ 1937 PVIU_TPCI_Req 1;
BA_ "GenSigSendType" SG_ 1945 PVIU_Byte2_Resp 1;
BA_ "GenSigSendType" SG_ 1945 PVIU_Byte3_Resp 1;
BA_ "GenSigSendType" SG_ 1945 PVIU_Byte4_Resp 1;
BA_ "GenSigSendType" SG_ 1945 PVIU_Byte5_Resp 1;
BA_ "GenSigSendType" SG_ 1945 PVIU_Byte6_Resp 1;
BA_ "GenSigSendType" SG_ 1945 PVIU_Byte7_Resp 1;
BA_ "GenSigSendType" SG_ 1945 PVIU_Byte8_Resp 1;
BA_ "GenSigSendType" SG_ 1945 PVIU_TPCI_Resp 1;
BA_ "GenSigSendType" SG_ 1986 VCU_Byte2_Req 1;
BA_ "GenSigSendType" SG_ 1986 VCU_Byte3_Req 1;
BA_ "GenSigSendType" SG_ 1986 VCU_Byte4_Req 1;
BA_ "GenSigSendType" SG_ 1986 VCU_Byte5_Req 1;
BA_ "GenSigSendType" SG_ 1986 VCU_Byte6_Req 1;
BA_ "GenSigSendType" SG_ 1986 VCU_Byte7_Req 1;
BA_ "GenSigSendType" SG_ 1986 VCU_Byte8_Req 1;
BA_ "GenSigSendType" SG_ 1986 VCU_TPCI_Req 1;
BA_ "GenSigSendType" SG_ 1994 VCU_Byte2_Resp 1;
BA_ "GenSigSendType" SG_ 1994 VCU_Byte3_Resp 1;
BA_ "GenSigSendType" SG_ 1994 VCU_Byte4_Resp 1;
BA_ "GenSigSendType" SG_ 1994 VCU_Byte5_Resp 1;
BA_ "GenSigSendType" SG_ 1994 VCU_Byte6_Resp 1;
BA_ "GenSigSendType" SG_ 1994 VCU_Byte7_Resp 1;
BA_ "GenSigSendType" SG_ 1994 VCU_Byte8_Resp 1;
BA_ "GenSigSendType" SG_ 1994 VCU_TPCI_Resp 1;
BA_ "GenSigSendType" SG_ 2005 WTC_B_Byte2_Req 1;
BA_ "GenSigSendType" SG_ 2005 WTC_B_Byte3_Req 1;
BA_ "GenSigSendType" SG_ 2005 WTC_B_Byte4_Req 1;
BA_ "GenSigSendType" SG_ 2005 WTC_B_Byte5_Req 1;
BA_ "GenSigSendType" SG_ 2005 WTC_B_Byte6_Req 1;
BA_ "GenSigSendType" SG_ 2005 WTC_B_Byte7_Req 1;
BA_ "GenSigSendType" SG_ 2005 WTC_B_Byte8_Req 1;
BA_ "GenSigSendType" SG_ 2005 WTC_B_TPCI_Req 1;
BA_ "GenSigSendType" SG_ 2013 WTC_B_Byte2_Resp 1;
BA_ "GenSigSendType" SG_ 2013 WTC_B_Byte3_Resp 1;
BA_ "GenSigSendType" SG_ 2013 WTC_B_Byte4_Resp 1;
BA_ "GenSigSendType" SG_ 2013 WTC_B_Byte5_Resp 1;
BA_ "GenSigSendType" SG_ 2013 WTC_B_Byte6_Resp 1;
BA_ "GenSigSendType" SG_ 2013 WTC_B_Byte7_Resp 1;
BA_ "GenSigSendType" SG_ 2013 WTC_B_Byte8_Resp 1;
BA_ "GenSigSendType" SG_ 2013 WTC_B_TPCI_Resp 1;
BA_ "GenSigSendType" SG_ 2015 Tester_Byte2_Req 1;
BA_ "GenSigSendType" SG_ 2015 Tester_Byte3_Req 1;
BA_ "GenSigSendType" SG_ 2015 Tester_Byte4_Req 1;
BA_ "GenSigSendType" SG_ 2015 Tester_Byte5_Req 1;
BA_ "GenSigSendType" SG_ 2015 Tester_Byte6_Req 1;
BA_ "GenSigSendType" SG_ 2015 Tester_Byte7_Req 1;
BA_ "GenSigSendType" SG_ 2015 Tester_Byte8_Req 1;
BA_ "GenSigSendType" SG_ 2015 Tester_TPCI_Req 1;
BA_ "GenSigSendType" SG_ 2016 VCU_OBD_Byte2_Req 1;
BA_ "GenSigSendType" SG_ 2016 VCU_OBD_Byte3_Req 1;
BA_ "GenSigSendType" SG_ 2016 VCU_OBD_Byte4_Req 1;
BA_ "GenSigSendType" SG_ 2016 VCU_OBD_Byte5_Req 1;
BA_ "GenSigSendType" SG_ 2016 VCU_OBD_Byte6_Req 1;
BA_ "GenSigSendType" SG_ 2016 VCU_OBD_Byte7_Req 1;
BA_ "GenSigSendType" SG_ 2016 VCU_OBD_Byte8_Req 1;
BA_ "GenSigSendType" SG_ 2016 VCU_OBD_TPCI_Req 1;
BA_ "GenSigSendType" SG_ 2017 BMS_Byte2_Req 1;
BA_ "GenSigSendType" SG_ 2017 BMS_Byte3_Req 1;
BA_ "GenSigSendType" SG_ 2017 BMS_Byte4_Req 1;
BA_ "GenSigSendType" SG_ 2017 BMS_Byte5_Req 1;
BA_ "GenSigSendType" SG_ 2017 BMS_Byte6_Req 1;
BA_ "GenSigSendType" SG_ 2017 BMS_Byte7_Req 1;
BA_ "GenSigSendType" SG_ 2017 BMS_Byte8_Req 1;
BA_ "GenSigSendType" SG_ 2017 BMS_TPCI_Req 1;
BA_ "GenSigSendType" SG_ 2018 EAS_Byte2_Req 1;
BA_ "GenSigSendType" SG_ 2018 EAS_Byte3_Req 1;
BA_ "GenSigSendType" SG_ 2018 EAS_Byte4_Req 1;
BA_ "GenSigSendType" SG_ 2018 EAS_Byte5_Req 1;
BA_ "GenSigSendType" SG_ 2018 EAS_Byte6_Req 1;
BA_ "GenSigSendType" SG_ 2018 EAS_Byte7_Req 1;
BA_ "GenSigSendType" SG_ 2018 EAS_Byte8_Req 1;
BA_ "GenSigSendType" SG_ 2018 EAS_TPCI_Req 1;
BA_ "GenSigSendType" SG_ 2024 VCU_OBD_Byte2_Resp 1;
BA_ "GenSigSendType" SG_ 2024 VCU_OBD_Byte3_Resp 1;
BA_ "GenSigSendType" SG_ 2024 VCU_OBD_Byte4_Resp 1;
BA_ "GenSigSendType" SG_ 2024 VCU_OBD_Byte5_Resp 1;
BA_ "GenSigSendType" SG_ 2024 VCU_OBD_Byte6_Resp 1;
BA_ "GenSigSendType" SG_ 2024 VCU_OBD_Byte7_Resp 1;
BA_ "GenSigSendType" SG_ 2024 VCU_OBD_Byte8_Resp 1;
BA_ "GenSigSendType" SG_ 2024 VCU_OBD_TPCI_Resp 1;
BA_ "GenSigSendType" SG_ 2025 BMS_Byte2_Resp 1;
BA_ "GenSigSendType" SG_ 2025 BMS_Byte3_Resp 1;
BA_ "GenSigSendType" SG_ 2025 BMS_Byte4_Resp 1;
BA_ "GenSigSendType" SG_ 2025 BMS_Byte5_Resp 1;
BA_ "GenSigSendType" SG_ 2025 BMS_Byte6_Resp 1;
BA_ "GenSigSendType" SG_ 2025 BMS_Byte7_Resp 1;
BA_ "GenSigSendType" SG_ 2025 BMS_Byte8_Resp 1;
BA_ "GenSigSendType" SG_ 2025 BMS_TPCI_Resp 1;
BA_ "GenSigSendType" SG_ 2026 EAS_Byte2_Resp 1;
BA_ "GenSigSendType" SG_ 2026 EAS_Byte3_Resp 1;
BA_ "GenSigSendType" SG_ 2026 EAS_Byte4_Resp 1;
BA_ "GenSigSendType" SG_ 2026 EAS_Byte5_Resp 1;
BA_ "GenSigSendType" SG_ 2026 EAS_Byte6_Resp 1;
BA_ "GenSigSendType" SG_ 2026 EAS_Byte7_Resp 1;
BA_ "GenSigSendType" SG_ 2026 EAS_Byte8_Resp 1;
BA_ "GenSigSendType" SG_ 2026 EAS_TPCI_Resp 1;
BA_ "GenSigSendType" SG_ 2032 ECC_Byte2_Req 1;
BA_ "GenSigSendType" SG_ 2032 ECC_Byte3_Req 1;
BA_ "GenSigSendType" SG_ 2032 ECC_Byte4_Req 1;
BA_ "GenSigSendType" SG_ 2032 ECC_Byte5_Req 1;
BA_ "GenSigSendType" SG_ 2032 ECC_Byte6_Req 1;
BA_ "GenSigSendType" SG_ 2032 ECC_Byte7_Req 1;
BA_ "GenSigSendType" SG_ 2032 ECC_Byte8_Req 1;
BA_ "GenSigSendType" SG_ 2032 ECC_TPCI_Req 1;
BA_ "GenSigSendType" SG_ 2035 OBC_Byte2_Req 1;
BA_ "GenSigSendType" SG_ 2035 OBC_Byte3_Req 1;
BA_ "GenSigSendType" SG_ 2035 OBC_Byte4_Req 1;
BA_ "GenSigSendType" SG_ 2035 OBC_Byte5_Req 1;
BA_ "GenSigSendType" SG_ 2035 OBC_Byte6_Req 1;
BA_ "GenSigSendType" SG_ 2035 OBC_Byte7_Req 1;
BA_ "GenSigSendType" SG_ 2035 OBC_Byte8_Req 1;
BA_ "GenSigSendType" SG_ 2035 OBC_TPCI_Req 1;
BA_ "GenSigSendType" SG_ 2040 ECC_Byte2_Resp 1;
BA_ "GenSigSendType" SG_ 2040 ECC_Byte3_Resp 1;
BA_ "GenSigSendType" SG_ 2040 ECC_Byte4_Resp 1;
BA_ "GenSigSendType" SG_ 2040 ECC_Byte5_Resp 1;
BA_ "GenSigSendType" SG_ 2040 ECC_Byte6_Resp 1;
BA_ "GenSigSendType" SG_ 2040 ECC_Byte7_Resp 1;
BA_ "GenSigSendType" SG_ 2040 ECC_Byte8_Resp 1;
BA_ "GenSigSendType" SG_ 2040 ECC_TPCI_Resp 1;
BA_ "GenSigSendType" SG_ 2043 OBC_Byte2_Resp 1;
BA_ "GenSigSendType" SG_ 2043 OBC_Byte3_Resp 1;
BA_ "GenSigSendType" SG_ 2043 OBC_Byte4_Resp 1;
BA_ "GenSigSendType" SG_ 2043 OBC_Byte5_Resp 1;
BA_ "GenSigSendType" SG_ 2043 OBC_Byte6_Resp 1;
BA_ "GenSigSendType" SG_ 2043 OBC_Byte7_Resp 1;
BA_ "GenSigSendType" SG_ 2043 OBC_Byte8_Resp 1;
BA_ "GenSigSendType" SG_ 2043 OBC_TPCI_Resp 1;
VAL_ 1696 BMS_mxCounterActEnergy 0 "no_information" 1 "Byte1_ActEngyHour,_Byte4_ActEngyDay" 2 "Byte1_ActEngyWeek,_Byte4_SctEngyMonth" ;
VAL_ 1701 BMS_MaxCellVoltPackNr 0 "Reserved" 1 "Battery_pack_1" 2 "Battery_pack_2" 3 "Battery_pack_3" 4 "Battery_pack_4" 5 "Reserved" 6 "Reserved" 7 "Reserved" ;
VAL_ 1701 BMS_MaxTPackNr 0 "Reserved" 1 "Battery_pack_1" 2 "Battery_pack_2" 3 "Battery_pack_3" 4 "Battery_pack_4" 5 "Reserved" 6 "Reserved" 7 "Reserved" ;
VAL_ 1701 BMS_MinTPackNr 0 "Reserved" 1 "Battery_pack_1" 2 "Battery_pack_2" 3 "Battery_pack_3" 4 "Battery_pack_4" 5 "Reserved" 6 "Reserved" 7 "Reserved" ;
VAL_ 1701 BMS_MinCellVoltPackNr 0 "Reserved" 1 "Battery_pack_1" 2 "Battery_pack_2" 3 "Battery_pack_3" 4 "Battery_pack_4" 5 "Reserved" 6 "Reserved" 7 "Reserved" ;
VAL_ 1712 BMS_CellVolt1 65535 "Invalid" ;
VAL_ 1712 BMS_CellVolt2 65535 "Invalid" ;
VAL_ 1712 BMS_CellVolt3 65535 "Invalid" ;
VAL_ 1712 BMS_CellVolt4 65535 "Invalid" ;
VAL_ 1713 BMS_CellVolt5 65535 "Invalid" ;
VAL_ 1713 BMS_CellVolt6 65535 "Invalid" ;
VAL_ 1713 BMS_CellVolt7 65535 "Invalid" ;
VAL_ 1713 BMS_CellVolt8 65535 "Invalid" ;
VAL_ 1714 BMS_CellVolt9 65535 "Invalid" ;
VAL_ 1714 BMS_CellVolt10 65535 "Invalid" ;
VAL_ 1714 BMS_CellVolt11 65535 "Invalid" ;
VAL_ 1714 BMS_CellVolt12 65535 "Invalid" ;
VAL_ 1715 BMS_CellVolt13 65535 "Invalid" ;
VAL_ 1715 BMS_CellVolt14 65535 "Invalid" ;
VAL_ 1715 BMS_CellVolt15 65535 "Invalid" ;
VAL_ 1715 BMS_CellVolt16 65535 "Invalid" ;
VAL_ 1716 BMS_CellVolt17 65535 "Invalid" ;
VAL_ 1716 BMS_CellVolt18 65535 "Invalid" ;
VAL_ 1716 BMS_CellVolt19 65535 "Invalid" ;
VAL_ 1716 BMS_CellVolt20 65535 "Invalid" ;
VAL_ 1717 BMS_CellVolt21 65535 "Invalid" ;
VAL_ 1717 BMS_CellVolt22 65535 "Invalid" ;
VAL_ 1717 BMS_CellVolt23 65535 "Invalid" ;
VAL_ 1717 BMS_CellVolt24 65535 "Invalid" ;
VAL_ 1718 BMS_CellVolt25 65535 "Invalid" ;
VAL_ 1718 BMS_CellVolt26 65535 "Invalid" ;
VAL_ 1718 BMS_CellVolt27 65535 "Invalid" ;
VAL_ 1718 BMS_CellVolt28 65535 "Invalid" ;
VAL_ 1719 BMS_CellVolt29 65535 "Invalid" ;
VAL_ 1719 BMS_CellVolt30 65535 "Invalid" ;
VAL_ 1719 BMS_CellVolt31 65535 "Invalid" ;
VAL_ 1719 BMS_CellVolt32 65535 "Invalid" ;
VAL_ 1720 BMS_CellVolt33 65535 "Invalid" ;
VAL_ 1720 BMS_CellVolt34 65535 "Invalid" ;
VAL_ 1720 BMS_CellVolt35 65535 "Invalid" ;
VAL_ 1720 BMS_CellVolt36 65535 "Invalid" ;
VAL_ 1721 BMS_CellVolt37 65535 "Invalid" ;
VAL_ 1721 BMS_CellVolt38 65535 "Invalid" ;
VAL_ 1721 BMS_CellVolt39 65535 "Invalid" ;
VAL_ 1721 BMS_CellVolt40 65535 "Invalid" ;
VAL_ 1722 BMS_CellVolt41 65535 "Invalid" ;
VAL_ 1722 BMS_CellVolt42 65535 "Invalid" ;
VAL_ 1722 BMS_CellVolt43 65535 "Invalid" ;
VAL_ 1722 BMS_CellVolt44 65535 "Invalid" ;
VAL_ 1723 BMS_CellVolt45 65535 "Invalid" ;
VAL_ 1723 BMS_CellVolt46 65535 "Invalid" ;
VAL_ 1723 BMS_CellVolt47 65535 "Invalid" ;
VAL_ 1723 BMS_CellVolt48 65535 "Invalid" ;
VAL_ 1724 BMS_CellVolt49 65535 "Invalid" ;
VAL_ 1724 BMS_CellVolt50 65535 "Invalid" ;
VAL_ 1724 BMS_CellVolt51 65535 "Invalid" ;
VAL_ 1724 BMS_CellVolt52 65535 "Invalid" ;
VAL_ 1725 BMS_CellVolt53 65535 "Invalid" ;
VAL_ 1725 BMS_CellVolt54 65535 "Invalid" ;
VAL_ 1725 BMS_CellVolt55 65535 "Invalid" ;
VAL_ 1725 BMS_CellVolt56 65535 "Invalid" ;
VAL_ 1726 BMS_CellVolt57 65535 "Invalid" ;
VAL_ 1726 BMS_CellVolt58 65535 "Invalid" ;
VAL_ 1726 BMS_CellVolt59 65535 "Invalid" ;
VAL_ 1726 BMS_CellVolt60 65535 "Invalid" ;
VAL_ 1727 BMS_CellVolt61 65535 "Invalid" ;
VAL_ 1727 BMS_CellVolt62 65535 "Invalid" ;
VAL_ 1727 BMS_CellVolt63 65535 "Invalid" ;
VAL_ 1727 BMS_CellVolt64 65535 "Invalid" ;
VAL_ 1728 BMS_CellVolt65 65535 "Invalid" ;
VAL_ 1728 BMS_CellVolt66 65535 "Invalid" ;
VAL_ 1728 BMS_CellVolt67 65535 "Invalid" ;
VAL_ 1728 BMS_CellVolt68 65535 "Invalid" ;
VAL_ 1729 BMS_CellVolt69 65535 "Invalid" ;
VAL_ 1729 BMS_CellVolt70 65535 "Invalid" ;
VAL_ 1729 BMS_CellVolt71 65535 "Invalid" ;
VAL_ 1729 BMS_CellVolt72 65535 "Invalid" ;
VAL_ 1730 BMS_CellVolt73 65535 "Invalid" ;
VAL_ 1730 BMS_CellVolt74 65535 "Invalid" ;
VAL_ 1730 BMS_CellVolt75 65535 "Invalid" ;
VAL_ 1730 BMS_CellVolt76 65535 "Invalid" ;
VAL_ 1731 BMS_CellVolt77 65535 "Invalid" ;
VAL_ 1731 BMS_CellVolt78 65535 "Invalid" ;
VAL_ 1731 BMS_CellVolt79 65535 "Invalid" ;
VAL_ 1731 BMS_CellVolt80 65535 "Invalid" ;
VAL_ 1732 BMS_CellVolt81 65535 "Invalid" ;
VAL_ 1732 BMS_CellVolt82 65535 "Invalid" ;
VAL_ 1732 BMS_CellVolt83 65535 "Invalid" ;
VAL_ 1732 BMS_CellVolt84 65535 "Invalid" ;
VAL_ 1733 BMS_CellVolt85 65535 "Invalid" ;
VAL_ 1733 BMS_CellVolt86 65535 "Invalid" ;
VAL_ 1733 BMS_CellVolt87 65535 "Invalid" ;
VAL_ 1733 BMS_CellVolt88 65535 "Invalid" ;
VAL_ 1734 BMS_CellVolt89 65535 "Invalid" ;
VAL_ 1734 BMS_CellVolt90 65535 "Invalid" ;
VAL_ 1734 BMS_CellVolt91 65535 "Invalid" ;
VAL_ 1734 BMS_CellVolt92 65535 "Invalid" ;
VAL_ 1735 BMS_CellVolt93 65535 "Invalid" ;
VAL_ 1735 BMS_CellVolt94 65535 "Invalid" ;
VAL_ 1735 BMS_CellVolt95 65535 "Invalid" ;
VAL_ 1735 BMS_CellVolt96 65535 "Invalid" ;
VAL_ 1736 BMS_CellVolt97 65535 "Invalid" ;
VAL_ 1736 BMS_CellVolt98 65535 "Invalid" ;
VAL_ 1736 BMS_CellVolt99 65535 "Invalid" ;
VAL_ 1736 BMS_CellVolt100 65535 "Invalid" ;
VAL_ 1737 BMS_CellVolt101 65535 "Invalid" ;
VAL_ 1737 BMS_CellVolt102 65535 "Invalid" ;
VAL_ 1737 BMS_CellVolt103 65535 "Invalid" ;
VAL_ 1737 BMS_CellVolt104 65535 "Invalid" ;
VAL_ 1738 BMS_CellVolt105 65535 "Invalid" ;
VAL_ 1738 BMS_CellVolt106 65535 "Invalid" ;
VAL_ 1738 BMS_CellVolt107 65535 "Invalid" ;
VAL_ 1738 BMS_CellVolt108 65535 "Invalid" ;
VAL_ 1739 BMS_CellVolt109 65535 "Invalid" ;
VAL_ 1739 BMS_CellVolt110 65535 "Invalid" ;
VAL_ 1739 BMS_CellVolt111 65535 "Invalid" ;
VAL_ 1739 BMS_CellVolt112 65535 "Invalid" ;
VAL_ 1740 BMS_CellVolt113 65535 "Invalid" ;
VAL_ 1740 BMS_CellVolt114 65535 "Invalid" ;
VAL_ 1740 BMS_CellVolt115 65535 "Invalid" ;
VAL_ 1740 BMS_CellVolt116 65535 "Invalid" ;
VAL_ 1741 BMS_CellVolt117 65535 "Invalid" ;
VAL_ 1741 BMS_CellVolt118 65535 "Invalid" ;
VAL_ 1741 BMS_CellVolt119 65535 "Invalid" ;
VAL_ 1741 BMS_CellVolt120 65535 "Invalid" ;
VAL_ 1744 BMS_CellT1 255 "Invalid" ;
VAL_ 1744 BMS_CellT2 255 "Invalid" ;
VAL_ 1744 BMS_CellT3 255 "Invalid" ;
VAL_ 1744 BMS_CellT4 255 "Invalid" ;
VAL_ 1744 BMS_CellT5 255 "Invalid" ;
VAL_ 1744 BMS_CellT6 255 "Invalid" ;
VAL_ 1744 BMS_CellT7 255 "Invalid" ;
VAL_ 1744 BMS_CellT8 255 "Invalid" ;
VAL_ 1745 BMS_CellT9 255 "Invalid" ;
VAL_ 1745 BMS_CellT10 255 "Invalid" ;
VAL_ 1745 BMS_CellT11 255 "Invalid" ;
VAL_ 1745 BMS_CellT12 255 "Invalid" ;
VAL_ 1745 BMS_CellT13 255 "Invalid" ;
VAL_ 1745 BMS_CellT14 255 "Invalid" ;
VAL_ 1745 BMS_CellT15 255 "Invalid" ;
VAL_ 1745 BMS_CellT16 255 "Invalid" ;
VAL_ 1746 BMS_CellT17 255 "Invalid" ;
VAL_ 1746 BMS_CellT18 255 "Invalid" ;
VAL_ 1746 BMS_CellT19 255 "Invalid" ;
VAL_ 1746 BMS_CellT20 255 "Invalid" ;
VAL_ 1746 BMS_CellT21 255 "Invalid" ;
VAL_ 1746 BMS_CellT22 255 "Invalid" ;
VAL_ 1746 BMS_CellT23 255 "Invalid" ;
VAL_ 1746 BMS_CellT24 255 "Invalid" ;
VAL_ 1747 BMS_CellT25 255 "Invalid" ;
VAL_ 1747 BMS_CellT26 255 "Invalid" ;
VAL_ 1747 BMS_CellT27 255 "Invalid" ;
VAL_ 1747 BMS_CellT28 255 "Invalid" ;
VAL_ 1747 BMS_CellT29 255 "Invalid" ;
VAL_ 1747 BMS_CellT30 255 "Invalid" ;
VAL_ 1747 BMS_CellT31 255 "Invalid" ;
VAL_ 1747 BMS_CellT32 255 "Invalid" ;
VAL_ 1748 BMS_CellT33 255 "Invalid" ;
VAL_ 1748 BMS_CellT34 255 "Invalid" ;
VAL_ 1748 BMS_CellT35 255 "Invalid" ;
VAL_ 1748 BMS_CellT36 255 "Invalid" ;
VAL_ 1748 BMS_CellT37 255 "Invalid" ;
VAL_ 1748 BMS_CellT38 255 "Invalid" ;
VAL_ 1748 BMS_CellT39 255 "Invalid" ;
VAL_ 1748 BMS_CellT40 255 "Invalid" ;
VAL_ 1749 BMS_CellT41 255 "Invalid" ;
VAL_ 1749 BMS_CellT42 255 "Invalid" ;
VAL_ 1749 BMS_CellT43 255 "Invalid" ;
VAL_ 1749 BMS_CellT44 255 "Invalid" ;
VAL_ 1749 BMS_CellT45 255 "Invalid" ;
VAL_ 1749 BMS_CellT46 255 "Invalid" ;
VAL_ 1749 BMS_CellT47 255 "Invalid" ;
VAL_ 1749 BMS_CellT48 255 "Invalid" ;
VAL_ 1750 BMS_CellT49 255 "Invalid" ;
VAL_ 1750 BMS_CellT50 255 "Invalid" ;
VAL_ 1750 BMS_CellT51 255 "Invalid" ;
VAL_ 1750 BMS_CellT52 255 "Invalid" ;
VAL_ 1750 BMS_CellT53 255 "Invalid" ;
VAL_ 1750 BMS_CellT54 255 "Invalid" ;
VAL_ 1750 BMS_CellT55 255 "Invalid" ;
VAL_ 1750 BMS_CellT56 255 "Invalid" ;
VAL_ 1751 BMS_CellT57 255 "Invalid" ;
VAL_ 1751 BMS_CellT58 255 "Invalid" ;
VAL_ 1751 BMS_CellT59 255 "Invalid" ;
VAL_ 1751 BMS_CellT60 255 "Invalid" ;
VAL_ 1751 BMS_CellT61 255 "Invalid" ;
VAL_ 1751 BMS_CellT62 255 "Invalid" ;
VAL_ 1751 BMS_CellT63 255 "Invalid" ;
VAL_ 1751 BMS_CellT64 255 "Invalid" ;
VAL_ 1752 BMS_CellT65 255 "Invalid" ;
VAL_ 1752 BMS_CellT66 255 "Invalid" ;
VAL_ 1752 BMS_CellT67 255 "Invalid" ;
VAL_ 1752 BMS_CellT68 255 "Invalid" ;
VAL_ 1752 BMS_CellT69 255 "Invalid" ;
VAL_ 1752 BMS_CellT70 255 "Invalid" ;
VAL_ 1752 BMS_CellT71 255 "Invalid" ;
VAL_ 1752 BMS_CellT72 255 "Invalid" ;
VAL_ 1753 BMS_CellT73 255 "Invalid" ;
VAL_ 1753 BMS_CellT74 255 "Invalid" ;
VAL_ 1753 BMS_CellT75 255 "Invalid" ;
VAL_ 1753 BMS_CellT76 255 "Invalid" ;
VAL_ 1753 BMS_CellT77 255 "Invalid" ;
VAL_ 1753 BMS_CellT78 255 "Invalid" ;
VAL_ 1753 BMS_CellT79 255 "Invalid" ;
VAL_ 1753 BMS_CellT80 255 "Invalid" ;
VAL_ 1754 VCU_ChrgLineAllwtCrt 255 "Invalid" ;
VAL_ 1754 VCU_DchaLineAllwCrt 255 "Invalid" ;
VAL_ 1754 VCU_DchaVehSts 0 "Initial_value" 1 "state_3" 2 "state_2" 3 "state_2¡®" 4 "state_3¡®" 5 "Discharge_CP" 6 "Discharging_stopped" 7 "Invalid" ;
VAL_ 1754 VCU_DCChrgSoktT1 255 "Invalid" ;
VAL_ 1754 VCU_DCChrgSoktT2 255 "Invalid" ;
VAL_ 1754 VCU_ACChrgDchaSoktT1 255 "Invalid" ;
VAL_ 1755 BMS_CellT81 255 "Invalid" ;
VAL_ 1755 BMS_CellT82 255 "Invalid" ;
VAL_ 1755 BMS_CellT83 255 "Invalid" ;
VAL_ 1755 BMS_CellT84 255 "Invalid" ;
VAL_ 1755 BMS_CellT85 255 "Invalid" ;
VAL_ 1755 BMS_CellT86 255 "Invalid" ;
VAL_ 1755 BMS_CellT87 255 "Invalid" ;
VAL_ 1755 BMS_CellT88 255 "Invalid" ;
VAL_ 1756 BMS_mxCounterEnergy 0 "no_information" 1 "Byte1_EgyHr1,Byte4_EgyHr2" 2 "Byte1_EgyHr3,Byte4_EgyHr4" 3 "Byte1_EgyHr5,Byte4_EgyHr6" 4 "Byte1_EgyHr7,Byte4_EgyHr8" 5 "Byte1_EgyHr9,Byte4_EgyHr10" 6 "Byte1_EgyHr11,Byte4_EgyHr12" 7 "Byte1_EgyHr13,Byte4_EgyHr14" 8 "Byte1_EgyHr15,Byte4_EgyHr16" 9 "Byte1_EgyHr17,Byte4_EgyHr18" 10 "Byte1_EgyHr19,Byte4_EgyHr20" 11 "Byte1_EgyHr21,Byte4_EgyHr22" 12 "Byte1_EgyHr23,Byte4_EgyHr24" 13 "Byte1_EgyHr25,Byte4_EgyHr26" 14 "Byte1_EgyHr27,Byte4_EgyHr28" 15 "Byte1_EgyHr29,Byte4_EgyHr30" 16 "Byte1_EgyHr31,Byte4_EgyHr32" 17 "Byte1_EgyHr33,Byte4_EgyHr34" 18 "Byte1_EgyHr35,Byte4_EgyHr36" 19 "Byte1_EgyHr37,Byte4_EgyHr38" 20 "Byte1_EgyHr39,Byte4_EgyHr40" 21 "Byte1_EgyHr41,Byte4_EgyHr42" 22 "Byte1_EgyHr43,Byte4_EgyHr44" 23 "Byte1_EgyHr45,Byte4_EgyHr46" 24 "Byte1_EgyHr47,Byte4_EgyHr48" 33 "Byte1_EgyDy1,Byte4_EgyDy2" 34 "Byte1_EgyDy3,Byte4_EgyDy4" 35 "Byte1_EgyDy5,Byte4_EgyDy6" 36 "Byte1_EgyDy7" 37 "Byte1_EgyWk1,Byte4_EgyWk2" 38 "Byte1_EgyWk3,Byte4_EgyWk4" 39 "Byte1_EgyWk5" 40 "Byte1_EgyMth1,Byte4_EgyMth2" 41 "Byte1_EgyMth3,Byte4_EgyMth4" 42 "Byte1_EgyMth5,Byte4_EgyMth6" 43 "Byte1_EgyMth7,Byte4_EgyMth8" 44 "Byte1_EgyMth9,Byte4_EgyMth10" 49 "Byte1_EgyMth9,Byte4_EgyMth10" 50 "Byte1_EgyYr3,Byte4_EgyYr4" 51 "Byte1_EgyYr5,Byte4_EgyYr6" 52 "Byte1_EgyYr7,Byte4_EgyYr8" 53 "Byte1_EgyYr9,Byte4_EgyYr10" 54 "Byte1_EgyYr11,Byte4_EgyYr12" 55 "Byte1_EgyYr13,Byte4_EgyYr14" ;
VAL_ 1759 BMS_PVIU_ModeReqSt 0 "Standby" 1 "Charging" 2 "Shutdown" 3 "Diagnostics" ;
VAL_ 1759 BMS_PVIU_ModeSt 0 "Standby" 1 "Charging" 2 "Shutdown" 3 "Diagnostics" ;
VAL_ 1759 BMS_PVIU_FailSt 0 "No_error" 1 "Derating" 2 "Failure,_Healed_automatically" 3 "Failure,_Healed_by_reset_module" ;
VAL_ 1759 BMS_PVIU_F_Input_OVP 0 "No_error" 1 "Error" ;
VAL_ 1759 BMS_PVIU_F_Input_UVP 0 "No_error" 1 "Error" ;
VAL_ 1759 BMS_PVIU_F_Output_OVP 0 "No_error" 1 "Error" ;
VAL_ 1759 BMS_PVIU_F_Output_UVP 0 "No_error" 1 "Error" ;
VAL_ 1759 BMS_PVIU_F_12V_OVP 0 "No_error" 1 "Error" ;
VAL_ 1759 BMS_PVIU_F_12V_UVP 0 "No_error" 1 "Error" ;
VAL_ 1759 BMS_PVIU_F_Output_SCP 0 "No_error" 1 "Error" ;
VAL_ 1759 BMS_PVIU_F_OTP 0 "No_error" 1 "Error" ;
VAL_ 1759 BMS_PVIU_F_HVIL 0 "No_error" 1 "Error" ;
VAL_ 1759 BMS_PVIU_F_CANRx_Timeout 0 "No_error" 1 "Error" ;
VAL_ 1759 BMS_PVIU_F_Output_OCP 0 "No_error" 1 "Error" ;
VAL_ 1791 VCU_DrvgMilgReqReducePwrLvl 0 "Default" 1 "Power_limit_under_the_operating_conditions_in_Chinese_cities" 2 "Power_limit_under_NEDC's_operating_conditions" 3 "power_limit_under_the_user's_operating_conditions" ;
VAL_ 1812 OBC_CtrlActMode 0 "Init" 1 "Standby" 2 "Charging_SelfCheck" 3 "Discharging_SelfCheck" 4 "Charging" 5 "Discharging" 6 "Fault" 7 "FunctionSafety" ;
VAL_ 1812 DCDC_CtrlMode 0 "Standby" 1 "Reserved" 2 "Buck" 3 "Reserved" 4 "Reserved" 5 "Fault" ;
VAL_ 1812 OBC_ElockCtrlCmd 0 "Initial_value" 1 "locking" 2 "Unlocking" 3 "Invalid" ;
